VERSION ""

NS_ :

BS_:

BU_: HCM IPMA_ADAS PSCM GWM _delete SCCM PDM DDM GENERIC TSTR

BO_ 2613272740 SymKeyPhysPDMtoGWM_ECG: 64 PDM
 SG_ SymKeyPhysPDMtoGWM_ECG : 7|29@0+ (1,0) [0|536870911] "unitless"  GWM

BO_ 2613215448 SymKeyPhysGWM_ECGtoDDM: 64 GWM
 SG_ SymKeyPhysGWM_ECGtoDDM : 7|29@0+ (1,0) [0|536870911] "unitless"  DDM

BO_ 2613272736 SymKeyPhysDDMtoGWM_ECG: 64 DDM
 SG_ SymKeyPhysDDMtoGWM_ECG : 7|29@0+ (1,0) [0|536870911] "unitless"  GWM

BO_ 831 Pass_Mirror_Sw_StatM: 16 DDM
 SG_ MirrorTelescopic_D_Rq : 9|2@0+ (1,0) [0|3] "SED"  PDM,GWM
 SG_ RearPassWindowLockCmd : 0|1@0+ (1,0) [0|1] "SED"  PDM,GWM
 SG_ RearPassWindowCmd : 20|3@0+ (1,0) [0|7] "SED"  PDM,GWM
 SG_ PassWindowCmd : 12|3@0+ (1,0) [0|7] "SED"  PDM,GWM
 SG_ PassMirrorCmd : 15|3@0+ (1,0) [0|7] "SED"  PDM,GWM
 SG_ DipMirrorPosPassenger : 4|1@0+ (1,0) [0|1] "SED"  PDM,GWM
 SG_ ActiveStoragePassenger : 7|3@0+ (1,0) [0|7] "SED"  PDM,GWM
 SG_ RearDriverWindowPos : 23|3@0+ (1,0) [0|7] "SED"  GWM
 SG_ DriverWindowPosition : 3|3@0+ (1,0) [0|7] "SED"  GWM

BO_ 1258 IPMB_Data1_FD3: 8 GWM
 SG_ TrlrCamraCalib_D_Stat : 3|2@0+ (1,0) [0|3] "SED"  IPMA_ADAS,PSCM
 SG_ TrlrCamraView_D_Stat : 7|4@0+ (1,0) [0|15] "SED"  IPMA_ADAS

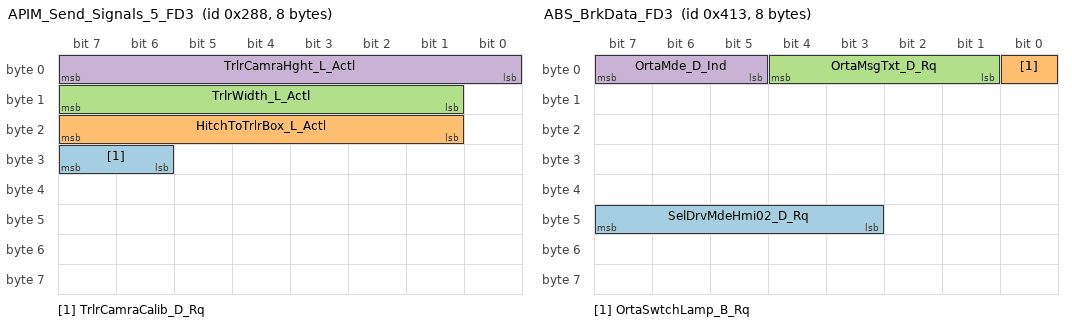
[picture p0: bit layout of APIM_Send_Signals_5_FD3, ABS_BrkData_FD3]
BO_ 648 APIM_Send_Signals_5_FD3: 8 GWM
 SG_ TrlrCamraCalib_D_Rq : 31|2@0+ (1,0) [0|3] "SED"  IPMA_ADAS
 SG_ HitchToTrlrBox_L_Actl : 23|7@0+ (25,0) [0|3175] "millimeter" Vector__XXX
 SG_ TrlrWidth_L_Actl : 15|7@0+ (25,0) [0|3175] "millimeter" Vector__XXX
 SG_ TrlrCamraHght_L_Actl : 7|8@0+ (25,0) [0|6375] "millimeter" Vector__XXX

BO_ 1158 BTT5GRH_Data1_FD3: 8 GWM
 SG_ SodAltRight_D2_StatAft : 7|2@0+ (1,0) [0|3] "SED"  IPMA_ADAS

BO_ 1157 BTT5GLH_Data1_FD3: 8 GWM
 SG_ SodAltLeft_D2_StatAft : 7|2@0+ (1,0) [0|3] "SED"  IPMA_ADAS

BO_ 1208 APIM_Send_Signals_4_FD3: 8 GWM
 SG_ Btt_L2_Actl2 : 7|7@0+ (0.1,5.1) [5.1|17.6] "meter"  IPMA_ADAS

BO_ 1218 Body_Info_5_FD3: 24 GWM
 SG_ OprtSrc_D_Stat : 47|3@0+ (1,0) [0|7] "SED"  _delete
 SG_ DrStopTglRl_No_Actl : 20|3@0+ (1,0) [0|7] "unitless"  _delete
 SG_ DrStopTglRr_No_Actl : 23|3@0+ (1,0) [0|7] "unitless"  _delete
 SG_ DrPsngrRearLck_D_Stat : 5|2@0+ (1,0) [0|3] "SED"  _delete
 SG_ DrDrvRearLck_D_Stat : 7|2@0+ (1,0) [0|3] "SED"  _delete
 SG_ ClsrOprtSrvcId_No_Actl : 36|3@0+ (1,0) [0|7] "unitless" Vector__XXX
 SG_ LckUnlckSrvcId_No_Actl : 39|3@0+ (1,0) [0|7] "unitless" Vector__XXX
 SG_ ClsrOprtSrvc_D_Res : 27|4@0+ (1,0) [0|15] "SED" Vector__XXX
 SG_ LckUnlckSrvc_D_Res : 31|4@0+ (1,0) [0|15] "SED" Vector__XXX
 SG_ ClsrOprtSrvc_D_Arb : 17|2@0+ (1,0) [0|3] "SED" Vector__XXX
 SG_ LckUnlckSrvc_D_Arb : 9|2@0+ (1,0) [0|3] "SED" Vector__XXX
 SG_ LatchFdbck_B_Stat : 33|1@0+ (1,0) [0|1] "SED" Vector__XXX
 SG_ FecSwtchExtLck_D_Stat : 11|2@0+ (1,0) [0|3] "SED" Vector__XXX
 SG_ DrPsngrLck_D_Stat : 13|2@0+ (1,0) [0|3] "SED" Vector__XXX
 SG_ DrDrvLck_D_Stat : 15|2@0+ (1,0) [0|3] "SED" Vector__XXX
 SG_ BecSwtchExtLck_D_Stat : 1|2@0+ (1,0) [0|3] "SED" Vector__XXX
 SG_ BecSwtch2ExtLck_D_Stat : 3|2@0+ (1,0) [0|3] "SED" Vector__XXX

BO_ 121 Steering_Data3: 64 SCCM
 SG_ SteSnsDiagData_No_Actl : 7|64@0+ (1,0) [0|1.84467440737096E+019] "unitless"  GWM

BO_ 1972 TesterPhysicalReqDCMH_FD3: 64 TSTR
 SG_ TesterPhysicalReqDCMH : 7|64@0+ (1,0) [0|1.84467E+019] "unitless" Vector__XXX

BO_ 1971 TesterPhysicalReqDCMG_FD3: 64 TSTR
 SG_ TesterPhysicalReqDCMG : 7|64@0+ (1,0) [0|1.84467E+019] "unitless" Vector__XXX

BO_ 2613272689 SymKeyPhysHCMtoGWM_ECG: 64 HCM
 SG_ SymKeyPhysHCMtoGWM_ECG : 7|29@0+ (1,0) [0|536870911] "unitless"  GWM

BO_ 2613167320 SymKeyPhysGWM_ECGtoHCM: 64 GWM
 SG_ SymKeyPhysGWM_ECGtoHCM : 7|29@0+ (1,0) [0|536870911] "unitless"  HCM

BO_ 1043 ABS_BrkData_FD3: 8 GWM
 SG_ SelDrvMdeHmi02_D_Rq : 47|5@0+ (1,0) [0|31] "SED" Vector__XXX
 SG_ OrtaSwtchLamp_B_Rq : 0|1@0+ (1,0) [0|1] "SED" Vector__XXX
 SG_ OrtaMsgTxt_D_Rq : 4|4@0+ (1,0) [0|15] "SED" Vector__XXX
 SG_ OrtaMde_D_Ind : 7|3@0+ (1,0) [0|7] "SED" Vector__XXX

BO_ 2609948888 OTAPhysGWM_ECGtoPBM: 64 GWM
 SG_ OTAPhysGWM_ECGtoPBM : 7|29@0+ (1,0) [0|536870911] "unitless" Vector__XXX

BO_ 2610997464 PARSEDPhysGWM_ECGtoPBM: 64 GWM
 SG_ PARSEDPhysGWM_ECGtoPBM : 7|29@0+ (1,0) [0|536870911] "unitless" Vector__XXX

BO_ 2612046040 PARSEDPushFcGWM_ECGtoPBM: 8 GWM
 SG_ PARSEDPushFcGWM_ECGtoPBM : 7|29@0+ (1,0) [0|536870911] "unitless" Vector__XXX

BO_ 2613094616 SymKeyPhysGWM_ECGtoPBM: 64 GWM
 SG_ SymKeyPhysGWM_ECGtoPBM : 7|29@0+ (1,0) [0|536870911] "unitless" Vector__XXX

BO_ 1049 APIMSDMsignals_FD3: 8 GWM
 SG_ TrlrRngId_No_RqReset : 27|4@0+ (1,0) [0|15] "unitless"  _delete
 SG_ TrlrId_No_ActlMnu : 31|4@0+ (1,0) [0|15] "unitless"  _delete
 SG_ TrailCtlSwtch_B_Stat4 : 21|1@0+ (1,0) [0|1] "SED"  _delete
 SG_ StabBarCnncButtn_D_Sta3 : 23|2@0+ (1,0) [0|3] "SED"  _delete
 SG_ RearDiffLck_D_RqDrv3 : 9|2@0+ (1,0) [0|3] "SED"  _delete
 SG_ FrontDiffLck_D_RqDrv3 : 11|2@0+ (1,0) [0|3] "SED"  _delete
 SG_ TurnAsstSwtch_D_Stat : 14|2@0+ (1,0) [0|3] "SED"  _delete
 SG_ SelDrvMdeTxtRst_B_Rq2 : 15|1@0+ (1,0) [0|1] "SED"  _delete
 SG_ SelDrvMdePage_B_Stat : 0|1@0+ (1,0) [0|1] "SED"  _delete
 SG_ SelDrvMdeCnfm_D_Stat2 : 2|2@0+ (1,0) [0|3] "SED"  _delete
 SG_ SelDrvMde_D_RqDrv : 7|5@0+ (1,0) [0|31] "SED"  _delete
 SG_ Chrgr_Pw_EstMx : 55|9@0+ (2,0) [0|1018] "kilowatt" Vector__XXX
 SG_ DcacZone3PwBttn_B_Stat : 34|1@0+ (1,0) [0|1] "SED" Vector__XXX
 SG_ DcacZone2PwBttn_B_Stat : 35|1@0+ (1,0) [0|1] "SED" Vector__XXX
 SG_ DcacPwResetBtn2_B_Stat : 36|1@0+ (1,0) [0|1] "SED" Vector__XXX
 SG_ DcacPwOffButtn2_B_Stat : 37|1@0+ (1,0) [0|1] "SED" Vector__XXX
 SG_ DcacPwHiButtn2_B_Stat : 38|1@0+ (1,0) [0|1] "SED" Vector__XXX
 SG_ DcacGfciTestBtn2_B_Stat : 39|1@0+ (1,0) [0|1] "SED" Vector__XXX
 SG_ DcacAllZoneBttn_B_Stat : 16|1@0+ (1,0) [0|1] "SED" Vector__XXX
 SG_ DcacChime_D_Rq : 18|2@0+ (1,0) [0|3] "SED" Vector__XXX
 SG_ PersTurnSglView_D_RqMnu : 20|2@0+ (1,0) [0|3] "SED"  IPMA_ADAS
 SG_ CamraFrnt_B_RqMnu : 12|1@0+ (1,0) [0|1] "SED"  IPMA_ADAS

BO_ 2611024088 PARSEDPhysGWM_ECGtoSCCM: 64 GWM
 SG_ PARSEDPhysGWM_ECGtoSCCM : 7|29@0+ (1,0) [0|536870911] "unitless"  SCCM

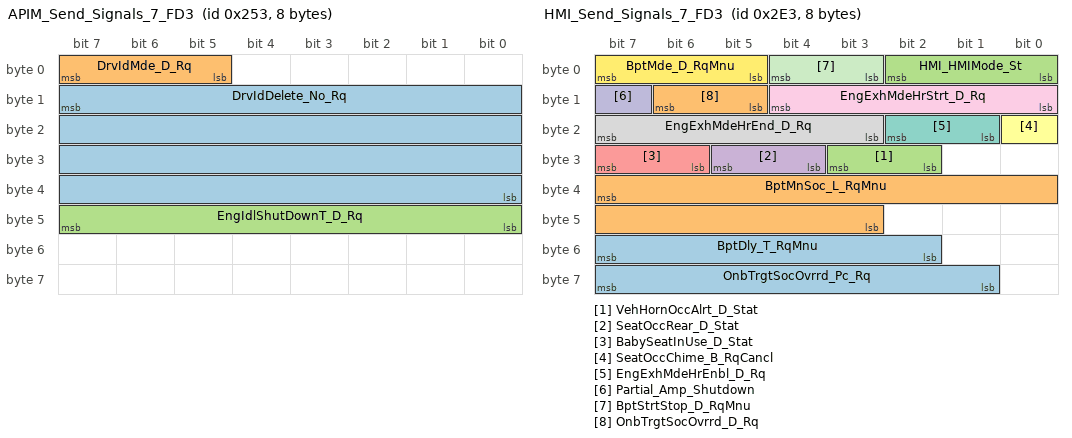
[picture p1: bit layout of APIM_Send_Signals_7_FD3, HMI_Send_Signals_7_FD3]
BO_ 595 APIM_Send_Signals_7_FD3: 8 GWM
 SG_ DrvIdDelete_No_Rq : 15|32@0+ (1,0) [0|4294967295] "Unitless"  _delete
 SG_ DrvIdMde_D_Rq : 7|3@0+ (1,0) [0|7] "SED"  _delete
 SG_ EngIdlShutDownT_D_Rq : 47|8@0+ (1,0) [0|255] "SED" Vector__XXX

BO_ 542 LocationServices_3_FD3: 8 GWM
 SG_ LocationServices_3 : 7|64@0+ (1,0) [0|1.84467440737096E+019] "unitless"  IPMA_ADAS

BO_ 2612224078 PARSEDPushLDCMBtoGWM_ECG: 8 HCM
 SG_ PARSEDPushLDCMBtoGWM_ECG : 7|29@0+ (1,0) [0|536870911] "unitless"  GWM

BO_ 2612224079 PARSEDPushLDCMAtoGWM_ECG: 8 HCM
 SG_ PARSEDPushLDCMAtoGWM_ECG : 7|29@0+ (1,0) [0|536870911] "unitless"  GWM

BO_ 2612082904 PARSEDPushFcGWM_ECGtoLDCMB: 8 GWM
 SG_ PARSEDPushFcGWM_ECGtoLDCMB : 7|29@0+ (1,0) [0|536870911] "unitless"  HCM

BO_ 2612083928 PARSEDPushFcGWM_ECGtoLDCMA: 8 GWM
 SG_ PARSEDPushFcGWM_ECGtoLDCMA : 7|29@0+ (1,0) [0|536870911] "unitless"  HCM

BO_ 2611175502 PARSEDPhysLDCMBtoGWM_ECG: 64 HCM
 SG_ PARSEDPhysLDCMBtoGWM_ECG : 7|29@0+ (1,0) [0|536870911] "Unitless"  GWM

BO_ 2611175503 PARSEDPhysLDCMAtoGWM_ECG: 64 HCM
 SG_ PARSEDPhysLDCMAtoGWM_ECG : 7|29@0+ (1,0) [0|536870911] "unitless"  GWM

BO_ 2611034328 PARSEDPhysGWM_ECGtoLDCMB: 64 GWM
 SG_ PARSEDPhysGWM_ECGtoLDCMB : 7|29@0+ (1,0) [0|536870911] "unitless"  HCM

BO_ 2611035352 PARSEDPhysGWM_ECGtoLDCMA: 64 GWM
 SG_ PARSEDPhysGWM_ECGtoLDCMA : 7|29@0+ (1,0) [0|536870911] "unitless"  HCM

BO_ 2610126926 OTAPhysLDCMBtoGWM_ECG: 64 HCM
 SG_ OTAPhysLDCMBtoGWM_ECG : 7|29@0+ (1,0) [0|536870911] "unitless"  GWM

BO_ 2610126927 OTAPhysLDCMAtoGWM_ECG: 64 HCM
 SG_ OTAPhysLDCMAtoGWM_ECG : 7|29@0+ (1,0) [0|536870911] "unitless"  GWM

BO_ 2609985752 OTAPhysGWM_ECGtoLDCMB: 64 GWM
 SG_ OTAPhysGWM_ECGtoLDCMB : 7|29@0+ (1,0) [0|536870911] "unitless"  HCM

BO_ 2609986776 OTAPhysGWM_ECGtoLDCMA: 64 GWM
 SG_ OTAPhysGWM_ECGtoLDCMA : 7|29@0+ (1,0) [0|536870911] "unitless"  HCM

BO_ 1791 TesterPhysicalResLDCMB: 64 HCM
 SG_ TesterPhysicalResLDCMB : 7|64@0+ (1,0) [0|1.84467E+019] "unitless"  TSTR

BO_ 1790 TesterPhysicalResLDCMA: 64 HCM
 SG_ TesterPhysicalResLDCMA : 7|64@0+ (1,0) [0|1.84467E+019] "unitless"  TSTR

BO_ 1783 TesterPhysicalReqLDCMB: 64 TSTR
 SG_ TesterPhysicalReqLDCMB : 7|64@0+ (1,0) [0|1.84467E+019] "unitless"  HCM

BO_ 1782 TesterPhysicalReqLDCMA: 64 TSTR
 SG_ TesterPhysicalReqLDCMA : 7|64@0+ (1,0) [0|1.84467E+019] "unitless"  HCM

BO_ 140 CruiseCtrl_StrgData2_FD3: 8 GWM
 SG_ DcacPwResetBttn_D_Stat : 36|2@0+ (1,0) [0|3] "SED" Vector__XXX

BO_ 739 HMI_Send_Signals_7_FD3: 8 GWM
 SG_ BptDly_T_RqMnu : 55|6@0+ (0.5,0) [0|30.5] "minute"  _delete
 SG_ BptMnSoc_L_RqMnu : 39|13@0+ (0.1,0) [0|818.9] "kilometer"  _delete
 SG_ VehHornOccAlrt_D_Stat : 27|2@0+ (1,0) [0|3] "SED"  _delete
 SG_ SeatOccRear_D_Stat : 29|2@0+ (1,0) [0|3] "SED"  _delete
 SG_ BabySeatInUse_D_Stat : 31|2@0+ (1,0) [0|3] "SED"  _delete
 SG_ SeatOccChime_B_RqCancl : 16|1@0+ (1,0) [0|1] "SED"  _delete
 SG_ EngExhMdeHrEnbl_D_Rq : 18|2@0+ (1,0) [0|3] "SED"  _delete
 SG_ EngExhMdeHrEnd_D_Rq : 23|5@0+ (1,0) [0|31] "SED"  _delete
 SG_ EngExhMdeHrStrt_D_Rq : 12|5@0+ (1,0) [0|31] "SED"  _delete
 SG_ Partial_Amp_Shutdown : 15|1@0+ (1,0) [0|1] "SED"  _delete
 SG_ BptStrtStop_D_RqMnu : 4|2@0+ (1,0) [0|3] "SED"  _delete
 SG_ BptMde_D_RqMnu : 7|3@0+ (1,0) [0|7] "SED"  _delete
 SG_ OnbTrgtSocOvrrd_Pc_Rq : 63|7@0+ (1,0) [0|127] "percent" Vector__XXX
 SG_ OnbTrgtSocOvrrd_D_Rq : 14|2@0+ (1,0) [0|3] "SED" Vector__XXX
 SG_ HMI_HMIMode_St : 2|3@0+ (1,0) [0|7] "SED"  SCCM,PDM,DDM

BO_ 129 Steering_Wheel_Data2: 8 SCCM
 SG_ SelDrvMdeSwtch4_D_Stat4 : 38|2@0+ (1,0) [0|3] "SED"  GWM
 SG_ EngExhMdeQuiet_B_RqDrv2 : 39|1@0+ (1,0) [0|1] "SED"  GWM
 SG_ SelDrvMdeSwtch3_D_Stat4 : 25|2@0+ (1,0) [0|3] "SED"  GWM
 SG_ SelDrvMdeSwtch2_D_Stat4 : 27|2@0+ (1,0) [0|3] "SED"  GWM
 SG_ SelDrvMdeSwtch1_D_Stat4 : 29|2@0+ (1,0) [0|3] "SED"  GWM
 SG_ PoliceAux4Swtch_B_Stat : 30|1@0+ (1,0) [0|1] "SED"  GWM
 SG_ PoliceAux3Swtch_B_Stat : 31|1@0+ (1,0) [0|1] "SED"  GWM
 SG_ PoliceAux2Swtch_B_Stat : 16|1@0+ (1,0) [0|1] "SED"  GWM
 SG_ PoliceAux1Swtch_B_Stat : 17|1@0+ (1,0) [0|1] "SED"  GWM
 SG_ SteWhlSwtchView_B_Stat : 23|1@0+ (1,0) [0|1] "SED"  GWM
 SG_ SteWhlSwtchSet_B_Stat : 8|1@0+ (1,0) [0|1] "SED"  GWM
 SG_ SteWhlSwtchPhon_B_Stat : 9|1@0+ (1,0) [0|1] "SED"  GWM
 SG_ SteWhlSwtchNav_B_Stat : 10|1@0+ (1,0) [0|1] "SED"  GWM
 SG_ SteWhlSwtchMed_B_Stat : 11|1@0+ (1,0) [0|1] "SED"  GWM
 SG_ SteWhlSwtchIod_B_Stat : 12|1@0+ (1,0) [0|1] "SED"  GWM
 SG_ SteWhlSwtchHud_B_Stat : 13|1@0+ (1,0) [0|1] "SED"  GWM
 SG_ SteWhlSwtchBack_B_Stat : 14|1@0+ (1,0) [0|1] "SED"  GWM
 SG_ SteWhlSwtchMenu_B_Stat : 22|1@0+ (1,0) [0|1] "SED"  GWM
 SG_ SteEffortInc_B_RqDrv : 5|1@0+ (1,0) [0|1] "SED"  GWM
 SG_ SelDrvMdeInc_B_RqDrv : 6|1@0+ (1,0) [0|1] "SED"  GWM
 SG_ SelDrvMdeDec_B_RqDrv : 7|1@0+ (1,0) [0|1] "SED"  GWM
 SG_ SuspDampInc_B_RqDrv : 15|1@0+ (1,0) [0|1] "SED"  GWM
 SG_ SteWhlSwtchUp_B_Stat : 3|1@0+ (1,0) [0|1] "SED"  GWM
 SG_ SteWhlSwtchRght_B_Stat : 2|1@0+ (1,0) [0|1] "SED"  GWM
 SG_ SteWhlSwtchOk_B_Stat : 4|1@0+ (1,0) [0|1] "SED"  GWM
 SG_ SteWhlSwtchLeft_B_Stat : 1|1@0+ (1,0) [0|1] "SED"  GWM
 SG_ SteWhlSwtchDown_B_Stat : 0|1@0+ (1,0) [0|1] "SED"  GWM

BO_ 863 Steering_Data2: 8 SCCM
 SG_ SteWhlHeat_D_Stat : 7|4@0+ (1,0) [0|15] "SED"  GWM

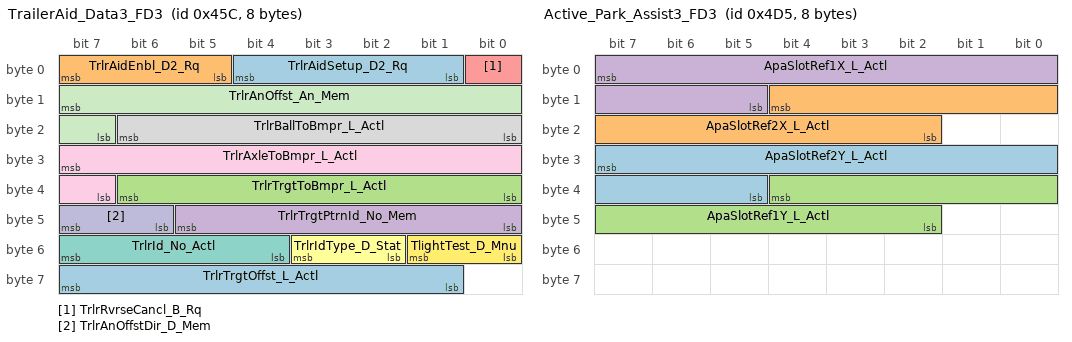
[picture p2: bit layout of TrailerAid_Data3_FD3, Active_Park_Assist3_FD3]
BO_ 1116 TrailerAid_Data3_FD3: 8 GWM
 SG_ TrlrAidSetup_D2_Rq : 4|4@0+ (1,0) [0|15] "SED"  PSCM,IPMA_ADAS
 SG_ TrlrAidEnbl_D2_Rq : 7|3@0+ (1,0) [0|7] "SED"  PSCM,IPMA_ADAS
 SG_ TrlrTrgtToBmpr_L_Actl : 38|7@0+ (0.0127,0) [0|1.6129] "meter"  PSCM,IPMA_ADAS
 SG_ TrlrTrgtPtrnId_No_Mem : 45|6@0+ (1,0) [0|63] "unitless"  IPMA_ADAS
 SG_ TrlrRvrseCancl_B_Rq : 0|1@0+ (1,0) [0|1] "SED"  PSCM,IPMA_ADAS
 SG_ TrlrIdType_D_Stat : 51|2@0+ (1,0) [0|3] "SED"  PSCM,IPMA_ADAS
 SG_ TrlrId_No_Actl : 55|4@0+ (1,0) [0|15] "unitless"  PSCM,IPMA_ADAS
 SG_ TrlrBallToBmpr_L_Actl : 22|7@0+ (0.0127,0) [0|1.6129] "meter"  PSCM,IPMA_ADAS
 SG_ TrlrAxleToBmpr_L_Actl : 31|9@0+ (0.0254,0) [0|12.9794] "meter"  PSCM,IPMA_ADAS
 SG_ TrlrAnOffstDir_D_Mem : 47|2@0+ (1,0) [0|3] "SED"  PSCM,IPMA_ADAS
 SG_ TrlrAnOffst_An_Mem : 15|9@0+ (0.1,0) [0|51.1] "degrees"  PSCM,IPMA_ADAS
 SG_ TlightTest_D_Mnu : 49|2@0+ (1,0) [0|3] "SED" Vector__XXX
 SG_ TrlrTrgtOffst_L_Actl : 63|7@0+ (0.0127,0) [0|1.6129] "meter"  PSCM,IPMA_ADAS

BO_ 1237 Active_Park_Assist3_FD3: 8 IPMA_ADAS
 SG_ ApaSlotRef2Y_L_Actl : 31|11@0+ (0.02,-20.96) [-20.96|19.98] "meter"  GWM
 SG_ ApaSlotRef2X_L_Actl : 12|11@0+ (0.02,-20.96) [-20.96|19.98] "meter"  GWM
 SG_ ApaSlotRef1Y_L_Actl : 36|11@0+ (0.02,-20.96) [-20.96|19.98] "meter"  GWM
 SG_ ApaSlotRef1X_L_Actl : 7|11@0+ (0.02,-20.96) [-20.96|19.98] "meter"  GWM

BO_ 1003 Personality_BCM2_Data_FD3: 16 GWM
 SG_ Pers4Key_D_Stat : 49|2@0+ (1,0) [0|3] "SED"  _delete
 SG_ EmPrflNo_D_Stat : 52|3@0+ (1,0) [0|7] "SED"  _delete
 SG_ EmPrflKeyAssoc_D_Stat : 55|3@0+ (1,0) [0|7] "SED"  _delete
 SG_ Pers3Key_D_Stat : 41|2@0+ (1,0) [0|3] "SED"  _delete
 SG_ Pers2Key_D_Stat : 43|2@0+ (1,0) [0|3] "SED"  _delete
 SG_ VehKeyActv_D_Stat : 47|4@0+ (1,0) [0|15] "SED"  _delete
 SG_ PersNoPos_D_Actl : 18|3@0+ (1,0) [0|7] "SED"  _delete
 SG_ PersConflict_D_Actl : 22|1@0+ (1,0) [0|1] "SED"  _delete
 SG_ Pers1Key_D_Stat : 12|2@0+ (1,0) [0|3] "SED"  _delete
 SG_ AssocConfirm_D_Actl : 15|3@0+ (1,0) [0|7] "SED"  _delete
 SG_ TailLghtLoadMde_D_Stat : 60|3@0+ (1,0) [0|7] "SED" Vector__XXX
 SG_ PersRecallSrc_D_Actl : 63|3@0+ (1,0) [0|7] "SED" Vector__XXX
 SG_ PersSetupRestr_D_Actl : 21|2@0+ (1,0) [0|3] "SED"  DDM,PDM
 SG_ PersSetupAccessCtrl : 19|1@0+ (1,0) [0|1] "SED"  DDM
 SG_ PersSetup_No_Actl : 31|16@0+ (1,0) [0|65535] "Number"  DDM,PDM
 SG_ RecallEvent_No_Cnt : 7|8@0+ (1,0) [0|255] "Counts"  DDM,IPMA_ADAS
 SG_ PersNo_D_Actl : 10|3@0+ (1,0) [0|7] "SED"  DDM,IPMA_ADAS

BO_ 1146 TrailerInfo_2_FD3: 8 GWM
 SG_ TrlrAidSwtch_D_RqDrv : 35|2@0+ (1,0) [0|3] "SED"  PSCM,IPMA_ADAS
 SG_ TrlrAidCtl_U_RqDrv : 31|12@0+ (0.00125,0) [0|5.11625] "volt"  PSCM

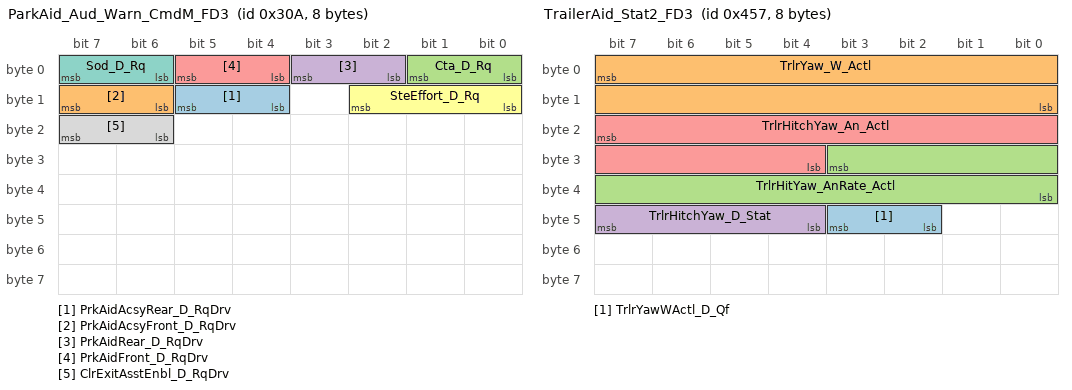
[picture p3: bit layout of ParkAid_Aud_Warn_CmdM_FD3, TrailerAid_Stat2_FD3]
BO_ 778 ParkAid_Aud_Warn_CmdM_FD3: 8 GWM
 SG_ PrkAidAcsyRear_D_RqDrv : 13|2@0+ (1,0) [0|3] "SED"  IPMA_ADAS
 SG_ PrkAidAcsyFront_D_RqDrv : 15|2@0+ (1,0) [0|3] "SED"  IPMA_ADAS
 SG_ Cta_D_Rq : 1|2@0+ (1,0) [0|3] "SED"  IPMA_ADAS
 SG_ PrkAidRear_D_RqDrv : 3|2@0+ (1,0) [0|3] "SED"  IPMA_ADAS
 SG_ PrkAidFront_D_RqDrv : 5|2@0+ (1,0) [0|3] "SED"  IPMA_ADAS
 SG_ SteEffort_D_Rq : 10|3@0+ (1,0) [0|7] "SED" Vector__XXX
 SG_ Sod_D_Rq : 7|2@0+ (1,0) [0|3] "SED"  IPMA_ADAS
 SG_ ClrExitAsstEnbl_D_RqDrv : 23|2@0+ (1,0) [0|3] "SED"  IPMA_ADAS

BO_ 1255 BoundaryAlert_Right_4: 16 IPMA_ADAS
 SG_ BalrRight4Threat_D_Stat : 16|1@0+ (1,0) [0|1] "SED"  GWM
 SG_ BalrRight4Prev3Y_L_Actl : 51|7@0+ (0.5,-32) [-32|31.5] "meter"  GWM
 SG_ BalrRight4Prev3X_L_Actl : 42|7@0+ (0.5,-32) [-32|31.5] "meter"  GWM
 SG_ BalrRight4Prev2Y_L_Actl : 33|7@0+ (0.5,-32) [-32|31.5] "meter"  GWM
 SG_ BalrRight4Prev2X_L_Actl : 24|7@0+ (0.5,-32) [-32|31.5] "meter"  GWM
 SG_ BalrRight4Prev1Y_L_Actl : 31|7@0+ (0.5,-32) [-32|31.5] "meter"  GWM
 SG_ BalrRight4Prev1X_L_Actl : 23|7@0+ (0.5,-32) [-32|31.5] "meter"  GWM
 SG_ BalrRight4Fast_B_Stat : 8|1@0+ (1,0) [0|1] "SED"  GWM
 SG_ BalrRight4Dsply_B_Stat : 0|1@0+ (1,0) [0|1] "SED"  GWM
 SG_ BalrRight4CurntY_L_Actl : 15|7@0+ (0.5,-32) [-32|31.5] "meter"  GWM
 SG_ BalrRight4CurntX_L_Actl : 7|7@0+ (0.5,-32) [-32|31.5] "meter"  GWM

BO_ 1254 BoundaryAlert_Right_3: 16 IPMA_ADAS
 SG_ BalrRight3Threat_D_Stat : 16|1@0+ (1,0) [0|1] "SED"  GWM
 SG_ BalrRight3Prev3Y_L_Actl : 51|7@0+ (0.5,-32) [-32|31.5] "meter"  GWM
 SG_ BalrRight3Prev3X_L_Actl : 42|7@0+ (0.5,-32) [-32|31.5] "meter"  GWM
 SG_ BalrRight3Prev2Y_L_Actl : 33|7@0+ (0.5,-32) [-32|31.5] "meter"  GWM
 SG_ BalrRight3Prev2X_L_Actl : 24|7@0+ (0.5,-32) [-32|31.5] "meter"  GWM
 SG_ BalrRight3Prev1Y_L_Actl : 31|7@0+ (0.5,-32) [-32|31.5] "meter"  GWM
 SG_ BalrRight3Prev1X_L_Actl : 23|7@0+ (0.5,-32) [-32|31.5] "meter"  GWM
 SG_ BalrRight3Fast_B_Stat : 8|1@0+ (1,0) [0|1] "SED"  GWM
 SG_ BalrRight3Dsply_B_Stat : 0|1@0+ (1,0) [0|1] "SED"  GWM
 SG_ BalrRight3CurntY_L_Actl : 15|7@0+ (0.5,-32) [-32|31.5] "meter"  GWM
 SG_ BalrRight3CurntX_L_Actl : 7|7@0+ (0.5,-32) [-32|31.5] "meter"  GWM

BO_ 1253 BoundaryAlert_Right_2: 16 IPMA_ADAS
 SG_ BalrRight2Prev3Y_L_Actl : 51|7@0+ (0.5,-32) [-32|31.5] "meter"  GWM
 SG_ BalrRight2Prev3X_L_Actl : 42|7@0+ (0.5,-32) [-32|31.5] "meter"  GWM
 SG_ BalrRight2Threat_D_Stat : 16|1@0+ (1,0) [0|1] "SED"  GWM
 SG_ BalrRight2Prev2Y_L_Actl : 33|7@0+ (0.5,-32) [-32|31.5] "meter"  GWM
 SG_ BalrRight2Prev2X_L_Actl : 24|7@0+ (0.5,-32) [-32|31.5] "meter"  GWM
 SG_ BalrRight2Prev1Y_L_Actl : 31|7@0+ (0.5,-32) [-32|31.5] "meter"  GWM
 SG_ BalrRight2Prev1X_L_Actl : 23|7@0+ (0.5,-32) [-32|31.5] "meter"  GWM
 SG_ BalrRight2Fast_B_Stat : 8|1@0+ (1,0) [0|1] "SED"  GWM
 SG_ BalrRight2Dsply_B_Stat : 0|1@0+ (1,0) [0|1] "SED"  GWM
 SG_ BalrRight2CurntY_L_Actl : 15|7@0+ (0.5,-32) [-32|31.5] "meter"  GWM
 SG_ BalrRight2CurntX_L_Actl : 7|7@0+ (0.5,-32) [-32|31.5] "meter"  GWM

BO_ 1252 BoundaryAlert_Right_1: 16 IPMA_ADAS
 SG_ BalrRight1Prev3Y_L_Actl : 51|7@0+ (0.5,-32) [-32|31.5] "meter"  GWM
 SG_ BalrRight1Prev3X_L_Actl : 42|7@0+ (0.5,-32) [-32|31.5] "meter"  GWM
 SG_ BalrRight1Threat_D_Stat : 16|1@0+ (1,0) [0|1] "SED"  GWM
 SG_ BalrRight1Prev2Y_L_Actl : 33|7@0+ (0.5,-32) [-32|31.5] "meter"  GWM
 SG_ BalrRight1Prev2X_L_Actl : 24|7@0+ (0.5,-32) [-32|31.5] "meter"  GWM
 SG_ BalrRight1Prev1Y_L_Actl : 31|7@0+ (0.5,-32) [-32|31.5] "meter"  GWM
 SG_ BalrRight1Prev1X_L_Actl : 23|7@0+ (0.5,-32) [-32|31.5] "meter"  GWM
 SG_ BalrRight1Fast_B_Stat : 8|1@0+ (1,0) [0|1] "SED"  GWM
 SG_ BalrRight1Dsply_B_Stat : 0|1@0+ (1,0) [0|1] "SED"  GWM
 SG_ BalrRight1CurntY_L_Actl : 15|7@0+ (0.5,-32) [-32|31.5] "meter"  GWM
 SG_ BalrRight1CurntX_L_Actl : 7|7@0+ (0.5,-32) [-32|31.5] "meter"  GWM

BO_ 1251 BoundaryAlert_Left_4: 16 IPMA_ADAS
 SG_ BalrLeft4Threat_D_Stat : 16|1@0+ (1,0) [0|1] "SED"  GWM
 SG_ BalrLeft4Prev3Y_L_Actl : 51|7@0+ (0.5,-32) [-32|31.5] "meter"  GWM
 SG_ BalrLeft4Prev3X_L_Actl : 42|7@0+ (0.5,-32) [-32|31.5] "meter"  GWM
 SG_ BalrLeft4Prev2Y_L_Actl : 33|7@0+ (0.5,-32) [-32|31.5] "meter"  GWM
 SG_ BalrLeft4Prev2X_L_Actl : 24|7@0+ (0.5,-32) [-32|31.5] "meter"  GWM
 SG_ BalrLeft4Prev1Y_L_Actl : 31|7@0+ (0.5,-32) [-32|31.5] "meter"  GWM
 SG_ BalrLeft4Prev1X_L_Actl : 23|7@0+ (0.5,-32) [-32|31.5] "meter"  GWM
 SG_ BalrLeft4Fast_B_Stat : 8|1@0+ (1,0) [0|1] "SED"  GWM
 SG_ BalrLeft4Dsply_B_Stat : 0|1@0+ (1,0) [0|1] "SED"  GWM
 SG_ BalrLeft4CurntY_L_Actl : 15|7@0+ (0.5,-32) [-32|31.5] "meter"  GWM
 SG_ BalrLeft4CurntX_L_Actl : 7|7@0+ (0.5,-32) [-32|31.5] "meter"  GWM

BO_ 1250 BoundaryAlert_Left_3: 16 IPMA_ADAS
 SG_ BalrLeft3Threat_D_Stat : 16|1@0+ (1,0) [0|1] "SED"  GWM
 SG_ BalrLeft3Prev3Y_L_Actl : 51|7@0+ (0.5,-32) [-32|31.5] "meter"  GWM
 SG_ BalrLeft3Prev3X_L_Actl : 42|7@0+ (0.5,-32) [-32|31.5] "meter"  GWM
 SG_ BalrLeft3Prev2Y_L_Actl : 33|7@0+ (0.5,-32) [-32|31.5] "meter"  GWM
 SG_ BalrLeft3Prev2X_L_Actl : 24|7@0+ (0.5,-32) [-32|31.5] "meter"  GWM
 SG_ BalrLeft3Prev1Y_L_Actl : 31|7@0+ (0.5,-32) [-32|31.5] "meter"  GWM
 SG_ BalrLeft3Prev1X_L_Actl : 23|7@0+ (0.5,-32) [-32|31.5] "meter"  GWM
 SG_ BalrLeft3Fast_B_Stat : 8|1@0+ (1,0) [0|1] "SED"  GWM
 SG_ BalrLeft3Dsply_B_Stat : 0|1@0+ (1,0) [0|1] "SED"  GWM
 SG_ BalrLeft3CurntY_L_Actl : 15|7@0+ (0.5,-32) [-32|31.5] "meter"  GWM
 SG_ BalrLeft3CurntX_L_Actl : 7|7@0+ (0.5,-32) [-32|31.5] "meter"  GWM

BO_ 1249 BoundaryAlert_Left_2: 16 IPMA_ADAS
 SG_ BalrLeft2Prev3Y_L_Actl : 51|7@0+ (0.5,-32) [-32|31.5] "meter"  GWM
 SG_ BalrLeft2Prev3X_L_Actl : 42|7@0+ (0.5,-32) [-32|31.5] "meter"  GWM
 SG_ BalrLeft2Threat_D_Stat : 16|1@0+ (1,0) [0|1] "SED"  GWM
 SG_ BalrLeft2Prev2Y_L_Actl : 33|7@0+ (0.5,-32) [-32|31.5] "meter"  GWM
 SG_ BalrLeft2Prev2X_L_Actl : 24|7@0+ (0.5,-32) [-32|31.5] "meter"  GWM
 SG_ BalrLeft2Prev1Y_L_Actl : 31|7@0+ (0.5,-32) [-32|31.5] "meter"  GWM
 SG_ BalrLeft2Prev1X_L_Actl : 23|7@0+ (0.5,-32) [-32|31.5] "meter"  GWM
 SG_ BalrLeft2Fast_B_Stat : 8|1@0+ (1,0) [0|1] "SED"  GWM
 SG_ BalrLeft2Dsply_B_Stat : 0|1@0+ (1,0) [0|1] "SED"  GWM
 SG_ BalrLeft2CurntY_L_Actl : 15|7@0+ (0.5,-32) [-32|31.5] "meter"  GWM
 SG_ BalrLeft2CurntX_L_Actl : 7|7@0+ (0.5,-32) [-32|31.5] "meter"  GWM

BO_ 1248 BoundaryAlert_Left_1: 16 IPMA_ADAS
 SG_ BalrLeft1Threat_D_Stat : 16|1@0+ (1,0) [0|1] "SED"  GWM
 SG_ BalrLeft1Prev3Y_L_Actl : 51|7@0+ (0.5,-32) [-32|31.5] "meter"  GWM
 SG_ BalrLeft1Prev3X_L_Actl : 42|7@0+ (0.5,-32) [-32|31.5] "meter"  GWM
 SG_ BalrLeft1Prev2Y_L_Actl : 33|7@0+ (0.5,-32) [-32|31.5] "meter"  GWM
 SG_ BalrLeft1Prev2X_L_Actl : 24|7@0+ (0.5,-32) [-32|31.5] "meter"  GWM
 SG_ BalrLeft1Prev1Y_L_Actl : 31|7@0+ (0.5,-32) [-32|31.5] "meter"  GWM
 SG_ BalrLeft1Prev1X_L_Actl : 23|7@0+ (0.5,-32) [-32|31.5] "meter"  GWM
 SG_ BalrLeft1Fast_B_Stat : 8|1@0+ (1,0) [0|1] "SED"  GWM
 SG_ BalrLeft1Dsply_B_Stat : 0|1@0+ (1,0) [0|1] "SED"  GWM
 SG_ BalrLeft1CurntY_L_Actl : 15|7@0+ (0.5,-32) [-32|31.5] "meter"  GWM
 SG_ BalrLeft1CurntX_L_Actl : 7|7@0+ (0.5,-32) [-32|31.5] "meter"  GWM

BO_ 2610988248 PARSEDPhysGWM_ECGtoIPMA: 64 GWM
 SG_ PARSEDPhysGWM_ECGtoIPMA : 7|29@0+ (1,0) [0|536870911] "unitless"  IPMA_ADAS

BO_ 1105 Image_Processing_Data: 16 IPMA_ADAS
 SG_ ClrExitAsstMsgTxt2_D_Rq : 55|4@0+ (1,0) [0|15] "SED"  GWM
 SG_ ClrExitAsstActv_B_Rq : 24|1@0+ (1,0) [0|1] "SED"  GWM
 SG_ TrlrRvrseMsgTxt_D2_Rq : 31|6@0+ (1,0) [0|63] "SED"  PSCM,GWM
 SG_ TrlrRvrseEnbl_D2_Stat : 18|3@0+ (1,0) [0|7] "SED"  PSCM,GWM
 SG_ RbaMsg_D_Rq : 22|2@0+ (1,0) [0|3] "SED"  GWM
 SG_ BrkDecel_B_RqRba : 8|1@0+ (1,0) [0|1] "SED"  GWM
 SG_ BrkEnbl_B_RqRba : 23|1@0+ (1,0) [0|1] "SED"  GWM
 SG_ Rba_D_Stat : 14|2@0+ (1,0) [0|3] "SED"  GWM
 SG_ RbaAlrt_D_Dsply : 12|2@0+ (1,0) [0|3] "SED"  GWM
 SG_ RbaMnu_D_Rq : 10|2@0+ (1,0) [0|3] "SED"  GWM
 SG_ CamraFrntStat_D_Stat : 7|2@0+ (1,0) [0|3] "SED"  GWM
 SG_ TrlrHitchLamp_D_Rq2 : 15|1@0+ (1,0) [0|1] "SED"  GWM
 SG_ TrlrAidSwtchLamp_B_Rq : 32|1@0+ (1,0) [0|1] "SED"  GWM
 SG_ TrlrAidEnbl_D_RqAdas : 5|3@0+ (1,0) [0|7] "SED"  PSCM,GWM
 SG_ TrlrHitchMsgTxt_D_Rq : 47|6@0+ (1,0) [0|63] "SED"  GWM
 SG_ TrlrHitchIcon_D_Rq : 36|4@0+ (1,0) [0|15] "SED"  GWM
 SG_ TrlrHitchChime_D_Rq : 39|3@0+ (1,0) [0|7] "SED"  GWM
 SG_ CamraFrntOffRd_B_Stat : 25|1@0+ (1,0) [0|1] "SED"  GWM

BO_ 1111 TrailerAid_Stat2_FD3: 8 GWM
 SG_ TrlrYawWActl_D_Qf : 43|2@0+ (1,0) [0|3] "SED"  PSCM,IPMA_ADAS
 SG_ TrlrYaw_W_Actl : 7|16@0+ (0.0002,-6.5) [-6.5|6.6066] "radians/second"  PSCM,IPMA_ADAS
 SG_ TrlrHitYaw_AnRate_Actl : 27|12@0+ (0.1,-50) [-50|359.3] "degrees/sec"  PSCM,IPMA_ADAS
 SG_ TrlrHitchYaw_D_Stat : 47|4@0+ (1,0) [0|15] "SED"  PSCM,IPMA_ADAS
 SG_ TrlrHitchYaw_An_Actl : 23|12@0+ (0.1,-90) [-90|319.3] "degrees"  PSCM,IPMA_ADAS

BO_ 1106 TrailerAid_Stat1_FD3: 8 GWM
 SG_ TrlrSnsId_No_Actl : 7|48@0+ (1,0) [0|281474976710653] "unitless"  PSCM,IPMA_ADAS

BO_ 909 Body_Info_6_FD3: 16 GWM
 SG_ HazrdLght_B_Stat : 56|1@0+ (1,0) [0|1] "SED"  _delete
 SG_ IgnPsswrdDsply_B_Rq : 57|1@0+ (1,0) [0|1] "SED"  _delete
 SG_ ElPwPoint_D_Rq : 59|2@0+ (1,0) [0|3] "SED"  _delete
 SG_ TurnLghtSwtch_D_Stat2 : 49|2@0+ (1,0) [0|3] "SED"  _delete
 SG_ PoliceIdlMde_D_Stat : 55|4@0+ (1,0) [0|15] "SED"  _delete
 SG_ PrsnlDevcChrgEnbl_B_Rq : 40|1@0+ (1,0) [0|1] "SED"  _delete
 SG_ DrLatchMsgTxt_D_Rq : 43|3@0+ (1,0) [0|7] "SED"  _delete
 SG_ TracKeyMde_D_Stat : 45|2@0+ (1,0) [0|3] "SED"  _delete
 SG_ SecurityMsgTxt_D_Rq : 47|2@0+ (1,0) [0|3] "SED"  _delete
 SG_ PrmtrAlrmEvnt_D_Stat : 35|4@0+ (1,0) [0|15] "SED"  _delete
 SG_ immoMsgTxt_D_Rq : 39|4@0+ (1,0) [0|15] "SED"  _delete
 SG_ SteWhlLckMsgTxt_D_Rq : 25|2@0+ (1,0) [0|3] "SED"  _delete
 SG_ PEBackupSlot_Stats : 27|2@0+ (1,0) [0|3] "SED"  _delete
 SG_ Keycode_Status : 15|20@0+ (1,0) [0|1048575] "unitless"  _delete
 SG_ KeyMykeyTot_No_Cnt : 3|4@0+ (1,0) [0|15] "Counts"  _delete
 SG_ KeyAdmnTot_No_Cnt : 7|4@0+ (1,0) [0|15] "Counts"  _delete
 SG_ WiprFront_D_Stat2 : 63|4@0+ (1,0) [0|15] "SED" Vector__XXX
 SG_ HeadLghtHiPrmsn_D_Stat : 51|2@0+ (1,0) [0|3] "SED"  SCCM,HCM,IPMA_ADAS

BO_ 963 BCM_Lamp_Stat_FD3: 16 GWM
 SG_ PudLampPsngr_D_Rq : 57|2@0+ (1,0) [0|3] "SED"  _delete
 SG_ DrTgateLck_D_Stat : 61|2@0+ (1,0) [0|3] "SED"  _delete
 SG_ Illuminated_Entry_Stat : 63|2@0+ (1,0) [0|3] "SED"  _delete
 SG_ Dr_Courtesy_Light_Stat : 49|2@0+ (1,0) [0|3] "SED"  _delete
 SG_ Courtesy_Delay_Status : 51|2@0+ (1,0) [0|3] "SED"  _delete
 SG_ ImpactEvntFdbck_D_Stat : 53|2@0+ (1,0) [0|3] "SED"  _delete
 SG_ WrlssAcsyChrgInhbt_B_Rq : 40|1@0+ (1,0) [0|1] "SED"  _delete
 SG_ HeadLampLoOut_B_Stat : 32|1@0+ (1,0) [0|1] "SED"  _delete
 SG_ TrnNotInPrkChime_B_Rq : 24|1@0+ (1,0) [0|1] "SED"  _delete
 SG_ PrkLightChime_B_Rq : 25|1@0+ (1,0) [0|1] "SED"  _delete
 SG_ Park_Brake_Chime_Rqst : 26|1@0+ (1,0) [0|1] "SED"  _delete
 SG_ KeyInIgnWarn_B_Cmd : 27|1@0+ (1,0) [0|1] "SED"  _delete
 SG_ HomeSafeLtChime_B_Rq : 28|1@0+ (1,0) [0|1] "SED"  _delete
 SG_ Headlamp_On_Wrning_Cmd : 29|1@0+ (1,0) [0|1] "SED"  _delete
 SG_ Brk_Fluid_Lvl_Low : 31|2@0+ (1,0) [0|3] "SED"  _delete
 SG_ ReducedGuard_D_Stat : 19|2@0+ (1,0) [0|3] "SED"  _delete
 SG_ BrkWarnInd_B_Rq : 20|1@0+ (1,0) [0|1] "SED"  _delete
 SG_ RvrseLghtOn_B_Stat : 9|1@0+ (1,0) [0|1] "SED"  _delete
 SG_ PrkLght_D_Stat : 13|2@0+ (1,0) [0|3] "SED"  _delete
 SG_ PerimeterAlarmChimeRq : 0|1@0+ (1,0) [0|1] "SED"  _delete
 SG_ CrnrLghtRight_Pc_Rq : 47|7@0+ (1,0) [0|100] "percent"  HCM
 SG_ CrnrLghtLeft_Pc_Rq : 39|7@0+ (1,0) [0|100] "percent"  HCM
 SG_ HeadLghtHiFdbck_D_Stat : 55|2@0+ (1,0) [0|3] "SED"  SCCM
 SG_ PudLampDrv_D_Rq : 59|2@0+ (1,0) [0|3] "SED"  DDM
 SG_ StopLghtOn_B_Stat : 8|1@0+ (1,0) [0|1] "SED"  HCM
 SG_ HeadLghtSwtch_D_Stat : 15|2@0+ (1,0) [0|3] "SED"  HCM,IPMA_ADAS
 SG_ HeadLampLoFrOn_B_Stat : 2|1@0+ (1,0) [0|1] "SED"  SCCM,HCM,IPMA_ADAS
 SG_ HeadLampLoFlOn_B_Stat : 3|1@0+ (1,0) [0|1] "SED"  SCCM,HCM,IPMA_ADAS
 SG_ HeadLampLoActv_B_Stat : 4|1@0+ (1,0) [0|1] "SED"  HCM,IPMA_ADAS
 SG_ HeadLghtHiOn_B_Stat : 1|1@0+ (1,0) [0|1] "SED"  HCM,IPMA_ADAS
 SG_ Perimeter_Alarm_Status : 17|2@0+ (1,0) [0|3] "SED"  IPMA_ADAS
 SG_ Courtesy_BSave_Stat : 7|2@0+ (1,0) [0|3] "SED"  PDM,DDM
 SG_ WndwGlbl_D_Cmd : 23|3@0+ (1,0) [0|7] "SED"  PDM,DDM
 SG_ PudLamp_D_Rq : 11|2@0+ (1,0) [0|3] "SED"  PDM,DDM
 SG_ DayRnngLampOn_B_Stat : 5|1@0+ (1,0) [0|1] "SED"  HCM

BO_ 578 Body_Info_4_FD3: 16 GWM
 SG_ PtLatchActv_B_RqBcm : 56|1@0+ (1,0) [0|1] "SED" Vector__XXX
 SG_ immoSecureIdleMode : 61|2@0+ (1,0) [0|3] "SED" Vector__XXX
 SG_ ReFuelSwtchStat_D_Actl : 63|2@0+ (1,0) [0|3] "SED" Vector__XXX
 SG_ FuelPumpPwr_D_Stat : 50|3@0+ (1,0) [0|7] "SED" Vector__XXX
 SG_ BattULo_U_Actl : 39|8@0+ (0.0625,0) [0|15.875] "volt"  PSCM,IPMA_ADAS
 SG_ PrkLckCtl_B_Enbl : 22|1@0+ (1,0) [0|1] "SED" Vector__XXX
 SG_ PrkLckCtlMsgTxt_D_Rq : 55|2@0+ (1,0) [0|3] "SED" Vector__XXX
 SG_ PrkLckCtlAvail_T_Stat : 47|8@0+ (1,0) [0|255] "second" Vector__XXX
 SG_ BrkTrnShifLck_B_Stat : 23|1@0+ (1,0) [0|1] "SED" Vector__XXX
 SG_ PrkLckCtlUnlck_D_Stat : 58|2@0+ (1,0) [0|3] "SED" Vector__XXX
 SG_ PrkLckCtlTow_B_Enbl : 59|1@0+ (1,0) [0|1] "SED" Vector__XXX
 SG_ DriverCrankingReq : 51|1@0+ (1,0) [0|1] "SED" Vector__XXX
 SG_ EngOff_T_Actl : 7|16@0+ (1,0) [0|65534] "second^0.5"  IPMA_ADAS
 SG_ DcacElPw_D_Rq : 53|2@0+ (1,0) [0|3] "SED" Vector__XXX
 SG_ BattULo_I_Actl : 21|14@0+ (0.0625,-512) [-512|511.875] "ampere" Vector__XXX

BO_ 1892 TesterPhysicalReqCCM: 64 TSTR
 SG_ TesterPhysicalReqCCM : 7|64@0+ (1,0) [0|1.84467E+019] "unitless"  IPMA_ADAS

BO_ 1798 TesterPhysicalReqIPMA: 64 TSTR
 SG_ TesterPhysicalReqIPMA : 7|64@0+ (1,0) [0|1.84467E+019] "unitless"  IPMA_ADAS

BO_ 1900 TesterPhysicalResCCM: 64 IPMA_ADAS
 SG_ TesterPhysicalResCCM : 7|64@0+ (1,0) [0|1.84467E+019] "unitless"  TSTR

BO_ 1806 TesterPhysicalResIPMA: 64 IPMA_ADAS
 SG_ TesterPhysicalResIPMA : 7|64@0+ (1,0) [0|1.84467E+019] "unitless"  TSTR

BO_ 1010 IPMA_Data3: 16 IPMA_ADAS
 SG_ LightRng_L_Max : 55|6@0+ (2,0) [0|126] "meter"  HCM,GWM
 SG_ LightPathOffst_L_Actl : 31|10@0+ (0.01,-5.12) [-5.12|5.11] "meter"  HCM,GWM
 SG_ LightPath_An_Actl : 12|11@0+ (0.0005,-0.5) [-0.5|0.5235] "radians"  HCM,GWM
 SG_ LightCurv_NoRate_Actl : 37|13@0+ (2.5E-007,-0.001024) [-0.001024|0.00102375] "1/meter"  HCM,GWM
 SG_ LightCurv_No_Actl : 7|11@0+ (2E-005,-0.02) [-0.02|0.02094] "1/meter"  HCM,GWM
 SG_ MbdblActv_B_RqAdas : 48|1@0+ (1,0) [0|1] "SED"  GWM,HCM
 SG_ CbdblActv_B_RqAdas : 49|1@0+ (1,0) [0|1] "SED"  HCM,GWM
 SG_ AdbUrbanArea_B_Stat : 40|1@0+ (1,0) [0|1] "SED"  HCM,GWM

BO_ 985 IPMA_Data2: 16 IPMA_ADAS
 SG_ LongCtrlEnblDRq_No_Cs : 63|8@0+ (1,0) [0|255] "Unitless"  GWM
 SG_ LongCtrlEnblDRq_No_Cnt : 29|4@0+ (1,0) [0|15] "Unitless"  GWM
 SG_ ClrExitAsst_D_Stat : 39|2@0+ (1,0) [0|3] "SED"  GWM
 SG_ ClrExitAsstMsgTxt_D_Rq : 52|4@0+ (1,0) [0|15] "SED"  GWM
 SG_ ClrExitAsstChime_D_Rq : 55|3@0+ (1,0) [0|7] "SED"  GWM
 SG_ PwSustnAdas_B_Rq : 48|1@0+ (1,0) [0|1] "SED"  GWM
 SG_ AdbDrvSide_B_Stat : 35|1@0+ (1,0) [0|1] "SED"  GWM
 SG_ LcwaMsgTxt_D_Stat : 37|2@0+ (1,0) [0|3] "SED"  GWM
 SG_ AdbDividedRoad_B_Stat : 30|1@0+ (1,0) [0|1] "SED"  GWM
 SG_ IsaVLimUnit_D_Rq : 15|2@0+ (1,0) [0|3] "SED"  GWM
 SG_ SblmYieldScnr_B_Stat : 31|1@0+ (1,0) [0|1] "SED"  HCM,GWM
 SG_ SblmStopScnr_B_Stat : 8|1@0+ (1,0) [0|1] "SED"  HCM,GWM
 SG_ IsaVLim_D_Rq : 7|8@0+ (1,0) [0|255] "SED"  GWM
 SG_ IaccVLimUnit_D_Rq : 11|2@0+ (1,0) [0|3] "SED"  GWM
 SG_ IaccVLim_D_Rq : 23|8@0+ (1,0) [0|255] "SED"  GWM
 SG_ DasAlrtInfo_D_Dsply : 13|2@0+ (1,0) [0|3] "SED"  GWM
 SG_ SblmRndAbtScnr_B_Stat : 9|1@0+ (1,0) [0|1] "SED"  HCM,GWM
 SG_ LongCtrlEnbl_D_Rq : 42|3@0+ (1,0) [0|7] "SED"  GWM
 SG_ SblmPedCrossScnr_B_Stat : 33|1@0+ (1,0) [0|1] "SED"  HCM,GWM
 SG_ TsrRegionTxt_D_Stat : 47|5@0+ (1,0) [0|31] "SED"  GWM
 SG_ LongCtrlBrk_D_Rq : 25|2@0+ (1,0) [0|3] "SED"  GWM
 SG_ LdwChime_B_Rq : 34|1@0+ (1,0) [0|1] "SED"  GWM

BO_ 984 IPMA_Data: 16 IPMA_ADAS
 SG_ AhbFeat_D_Stat : 63|2@0+ (1,0) [0|3] "SED"  HCM,SCCM,GWM
 SG_ LaActvStats_D2_Dsply : 55|5@0+ (1,0) [0|31] "SED"  GWM
 SG_ DasWarn_D_Dsply : 44|2@0+ (1,0) [0|3] "SED"  GWM
 SG_ DasStats_D_Dsply : 47|2@0+ (1,0) [0|3] "SED"  GWM
 SG_ DasAlrtLvl_D_Dsply : 42|3@0+ (1,0) [0|7] "SED"  GWM
 SG_ CamraStats_D_Dsply : 35|2@0+ (1,0) [0|3] "SED"  GWM
 SG_ CamraDefog_B_Req : 36|1@0+ (1,0) [0|1] "SED"  GWM
 SG_ LaHandsOff_D_Dsply : 50|2@0+ (1,0) [0|3] "SED"  GWM
 SG_ LaDenyStats_B_Dsply : 32|1@0+ (1,0) [0|1] "SED"  GWM
 SG_ AhbcRampingV_D_Rq : 57|2@0+ (1,0) [0|3] "SED"  GWM
 SG_ PersIndexIpma_D_Actl : 39|3@0+ (1,0) [0|7] "SED"  GWM
 SG_ FeatNoIpmaActl : 23|16@0+ (1,0) [0|65535] "Number"  GWM
 SG_ FeatConfigIpmaActl : 7|16@0+ (1,0) [0|65535] "Undefined"  GWM
 SG_ AhbHiBeam_D_Rq : 59|2@0+ (1,0) [0|3] "SED"  SCCM,GWM
 SG_ DsmcMsgTxt_D_Dsply : 61|2@0+ (1,0) [0|3] "SED" Vector__XXX

BO_ 983 Steer_Assist_Data: 16 IPMA_ADAS
 SG_ CmbbObjRelLong_V_Actl : 39|10@0+ (0.1,-102.1) [-102.1|0] "meters/sec"  PSCM,GWM
 SG_ CmbbObjRelLat_V_Actl : 23|9@0+ (0.1,-25.5) [-25.5|25.4] "meters/sec"  PSCM,GWM
 SG_ CmbbObjDistLong_L_Actl : 7|10@0+ (0.1,0) [0|102.1] "meter"  PSCM,GWM
 SG_ CmbbObjDistLat_L_Actl : 45|9@0+ (0.1,-25.5) [-25.5|25.4] "meter"  PSCM,GWM
 SG_ CmbbObjConfdnc_D_Stat : 9|2@0+ (1,0) [0|3] "SED"  PSCM,GWM
 SG_ CmbbObjColl_T_Actl : 30|7@0+ (0.05,0) [0|6.25] "second"  PSCM,GWM
 SG_ CmbbObjClass_D_Stat : 13|4@0+ (1,0) [0|15] "SED"  PSCM,GWM
 SG_ EsaEnbl_D2_Rq : 52|2@0+ (1,0) [0|3] "SED"  PSCM,GWM

BO_ 970 Lane_Assist_Data1: 16 IPMA_ADAS
 SG_ LkaDrvOvrrd_D_Rq : 38|2@0+ (1,0) [0|3] "SED"  PSCM,GWM
 SG_ LkaActvStats_D2_Req : 7|3@0+ (1,0) [0|7] "SED"  PSCM,GWM
 SG_ LaRefAng_No_Req : 19|12@0+ (0.05,-102.4) [-102.4|102.3] "mrad"  PSCM,GWM
 SG_ LaRampType_B_Req : 39|1@0+ (1,0) [0|1] "SED"  PSCM,GWM
 SG_ LaCurvature_No_Calc : 15|12@0+ (5E-006,-0.01024) [-0.01024|0.01023] "1/m"  PSCM,GWM
 SG_ LdwActvStats_D_Req : 4|3@0+ (1,0) [0|7] "SED"  PSCM,GWM
 SG_ LdwActvIntns_D_Req : 1|2@0+ (1,0) [0|3] "SED"  PSCM,GWM

CM_ SG_ 542 LocationServices_3 "Tx by HS3 APIM";
CM_ BO_ 739 "FCDIM Tx";
CM_ SG_ 739 Partial_Amp_Shutdown "Method Partial_Amp_Shutdown";
CM_ SG_ 739 HMI_HMIMode_St "Object ACU System Master.HMIMode
OR
Object NAV System Master.HMIMode

Refer Method HMIAudioMode in the SPSS";
CM_ SG_ 129 SelDrvMdeSwtch3_D_Stat4 "ECM_HEV does not support or Transmit signal.";
CM_ BO_ 1111 " new RCM Serial Trailer Aid (TrailerAid_Stat1) 48 bits";
CM_ BO_ 1106 " new RCM Serial Trailer Aid (TrailerAid_Stat1) 48 bits";
CM_ SG_ 985 LongCtrlEnblDRq_No_Cs "Signal not transmitted on gas and diesel variants.";
CM_ SG_ 985 LongCtrlEnblDRq_No_Cnt "Signal not transmitted on gas and diesel variants.";
BA_DEF_ BO_  "VFrameFormat" ENUM  "StandardCAN","ExtendedCAN","reserved","reserved","reserved","reserved","reserved","reserved","reserved","reserved","reserved","reserved","reserved","reserved","StandardCAN_FD","ExtendedCAN_FD";
BA_DEF_ BO_  "FrameRouting" STRING ;
BA_DEF_ BO_  "NetworkInitialization" ENUM  "No","Yes";
BA_DEF_ BO_  "GenMsgStartDelayTime" INT 0 10000;
BA_DEF_ BO_  "GenMsgNrOfRepetition" INT 0 100;
BA_DEF_ BO_  "GenMsgDelayTime" INT 0 1000;
BA_DEF_ BO_  "GenMsgCycleTime" INT 0 100000;
BA_DEF_ BO_  "GenMsgSendType" ENUM  "FixedPeriodic","Event","EnabledPeriodic","NotUsed","NotUsed","EventPeriodic","NotUsed","NotUsed","NoMsgSendType";
BA_DEF_ SG_  "U_P702_MY2024_Tx" ENUM  "No","Yes";
BA_DEF_ SG_  "U_V710_MY2023_Tx" ENUM  "No","Yes";
BA_DEF_ SG_  "U_CDX74X_MY2024_Tx" ENUM  "No","Yes";
BA_DEF_ SG_  "U_P708_MY2023_Tx" ENUM  "No","Yes";
BA_DEF_ SG_  "U_V713AV_MY2022_Tx" ENUM  "No","Yes";
BA_DEF_ SG_  "U_V713N_MY2022_Tx" ENUM  "No","Yes";
BA_DEF_ SG_  "ECGUsedTxSignal" ENUM  "No","Yes";
BA_DEF_ SG_  "U_P702_MY2024_Rx" ENUM  "No","Yes";
BA_DEF_ SG_  "U_V710_MY2023_Rx" ENUM  "No","Yes";
BA_DEF_ SG_  "U_CDX74X_MY2024_Rx" ENUM  "No","Yes";
BA_DEF_ SG_  "U_CDX707_MY2023_Rx" ENUM  "No","Yes";
BA_DEF_ SG_  "U_P708_MY2023_Rx" ENUM  "No","Yes";
BA_DEF_ SG_  "U_V713N_MY2022_Rx" ENUM  "No","Yes";
BA_DEF_ SG_  "ECGUsedRxSignal" ENUM  "No","Yes";
BA_DEF_ SG_  "UsedOnPgmDBC" ENUM  "No","Yes";
BA_DEF_ SG_  "ContentDependant" ENUM  "No","Yes";
BA_DEF_ SG_  "GenSigStartValue" HEX 0 268435455;
BA_DEF_ SG_  "MetaData" ENUM  "No","Yes";
BA_DEF_ SG_  "WakeupSignal" ENUM  "No","Yes";
BA_DEF_ SG_  "GenSigInactiveValue" INT 0 100000;
BA_DEF_ SG_  "GenSigSendType" ENUM  "Cyclic","OnWrite","vector_leerstring","OnChange","vector_leerstring","IfActive","vector_leerstring","NoSigSendType";
BA_DEF_ BO_  "TpTxIndex" INT 0 536870911;
BA_DEF_ BO_  "OvtpPushApplication" ENUM  "FALSE","TRUE";
BA_DEF_ BO_  "SCP_FreshnessValueLength" INT 0 512;
BA_DEF_ BO_  "SCP_DataId" INT 0 17663;
BA_DEF_ BO_  "SCP_FreshnessValueTxLength" INT 0 512;
BA_DEF_ BO_  "SCP_AuthInfoTxLength" INT 0 512;
BA_DEF_ BO_  "SC_Message" ENUM  "No","Yes";
BA_DEF_ BO_  "GenMsgRoutingTimeoutTime" INT 0 5000;
BA_DEF_ BO_  "MessageGateway" ENUM  "No","Yes";
BA_DEF_ BO_  "NmAsrMessage" ENUM  "No","Yes";
BA_DEF_ BO_  "DiagState" ENUM  "No","Yes";
BA_DEF_ BO_  "DiagRequest" ENUM  "No","Yes";
BA_DEF_ BO_  "DiagResponse" ENUM  "No","Yes";
BA_DEF_ BO_  "GenMsgILSupport" ENUM  "No","Yes";
BA_DEF_REL_ BU_SG_REL_  "SC_Verification" ENUM  "No","Yes";
BA_DEF_DEF_  "VFrameFormat" "ExtendedCAN_FD";
BA_DEF_DEF_  "FrameRouting" "";
BA_DEF_DEF_  "NetworkInitialization" "Yes";
BA_DEF_DEF_  "GenMsgStartDelayTime" 0;
BA_DEF_DEF_  "GenMsgNrOfRepetition" 1;
BA_DEF_DEF_  "GenMsgDelayTime" 20;
BA_DEF_DEF_  "GenMsgCycleTime" 0;
BA_DEF_DEF_  "GenMsgSendType" "NoMsgSendType";
BA_DEF_DEF_  "U_P702_MY2024_Tx" "No";
BA_DEF_DEF_  "U_V710_MY2023_Tx" "No";
BA_DEF_DEF_  "U_CDX74X_MY2024_Tx" "No";
BA_DEF_DEF_  "U_P708_MY2023_Tx" "No";
BA_DEF_DEF_  "U_V713AV_MY2022_Tx" "No";
BA_DEF_DEF_  "U_V713N_MY2022_Tx" "No";
BA_DEF_DEF_  "ECGUsedTxSignal" "No";
BA_DEF_DEF_  "U_P702_MY2024_Rx" "No";
BA_DEF_DEF_  "U_V710_MY2023_Rx" "No";
BA_DEF_DEF_  "U_CDX74X_MY2024_Rx" "No";
BA_DEF_DEF_  "U_CDX707_MY2023_Rx" "No";
BA_DEF_DEF_  "U_P708_MY2023_Rx" "No";
BA_DEF_DEF_  "U_V713N_MY2022_Rx" "No";
BA_DEF_DEF_  "ECGUsedRxSignal" "No";
BA_DEF_DEF_  "UsedOnPgmDBC" "Yes";
BA_DEF_DEF_  "ContentDependant" "No";
BA_DEF_DEF_  "GenSigStartValue" 0;
BA_DEF_DEF_  "MetaData" "No";
BA_DEF_DEF_  "WakeupSignal" "No";
BA_DEF_DEF_  "GenSigInactiveValue" 0;
BA_DEF_DEF_  "GenSigSendType" "NoSigSendType";
BA_DEF_DEF_  "TpTxIndex" 0;
BA_DEF_DEF_  "OvtpPushApplication" "FALSE";
BA_DEF_DEF_  "SCP_FreshnessValueLength" 64;
BA_DEF_DEF_  "SCP_DataId" 0;
BA_DEF_DEF_  "SCP_FreshnessValueTxLength" 11;
BA_DEF_DEF_  "SCP_AuthInfoTxLength" 53;
BA_DEF_DEF_  "SC_Message" "No";
BA_DEF_DEF_  "GenMsgRoutingTimeoutTime" 0;
BA_DEF_DEF_  "MessageGateway" "No";
BA_DEF_DEF_  "NmAsrMessage" "No";
BA_DEF_DEF_  "DiagState" "No";
BA_DEF_DEF_  "DiagRequest" "No";
BA_DEF_DEF_  "DiagResponse" "No";
BA_DEF_DEF_  "GenMsgILSupport" "Yes";
BA_DEF_DEF_REL_ "SC_Verification" "No";
BA_ "GenMsgSendType" BO_ 2613272740 1;
BA_ "GenMsgDelayTime" BO_ 2613272740 0;
BA_ "NetworkInitialization" BO_ 2613272740 0;
BA_ "GenMsgSendType" BO_ 2613215448 1;
BA_ "GenMsgDelayTime" BO_ 2613215448 0;
BA_ "NetworkInitialization" BO_ 2613215448 0;
BA_ "GenMsgSendType" BO_ 2613272736 1;
BA_ "GenMsgDelayTime" BO_ 2613272736 0;
BA_ "NetworkInitialization" BO_ 2613272736 0;
BA_ "GenMsgSendType" BO_ 831 5;
BA_ "GenMsgCycleTime" BO_ 831 1000;
BA_ "GenMsgStartDelayTime" BO_ 831 200;
BA_ "SCP_DataId" BO_ 831 17215;
BA_ "SC_Message" BO_ 831 1;
BA_ "VFrameFormat" BO_ 831 14;
BA_ "FrameRouting" BO_ 1258 "MS2_CAN,0x4EA;";
BA_ "VFrameFormat" BO_ 1258 14;
BA_ "FrameRouting" BO_ 648 "HS3_CAN,0x288;";
BA_ "VFrameFormat" BO_ 648 14;
BA_ "FrameRouting" BO_ 1158 "MS2_CAN,0x486;";
BA_ "VFrameFormat" BO_ 1158 14;
BA_ "FrameRouting" BO_ 1157 "MS2_CAN,0x485;";
BA_ "VFrameFormat" BO_ 1157 14;
BA_ "FrameRouting" BO_ 1208 "HS3_CAN,0x4B8;";
BA_ "VFrameFormat" BO_ 1208 14;
BA_ "FrameRouting" BO_ 1218 "FD1_CAN,0x4C2;";
BA_ "SCP_DataId" BO_ 1218 13506;
BA_ "SC_Message" BO_ 1218 1;
BA_ "VFrameFormat" BO_ 1218 14;
BA_ "GenMsgSendType" BO_ 121 0;
BA_ "GenMsgCycleTime" BO_ 121 10;
BA_ "GenMsgDelayTime" BO_ 121 0;
BA_ "VFrameFormat" BO_ 121 14;
BA_ "GenMsgILSupport" BO_ 1972 0;
BA_ "DiagRequest" BO_ 1972 1;
BA_ "GenMsgSendType" BO_ 1972 1;
BA_ "GenMsgDelayTime" BO_ 1972 0;
BA_ "NetworkInitialization" BO_ 1972 0;
BA_ "VFrameFormat" BO_ 1972 14;
BA_ "GenMsgILSupport" BO_ 1971 0;
BA_ "DiagRequest" BO_ 1971 1;
BA_ "GenMsgSendType" BO_ 1971 1;
BA_ "GenMsgDelayTime" BO_ 1971 0;
BA_ "NetworkInitialization" BO_ 1971 0;
BA_ "VFrameFormat" BO_ 1971 14;
BA_ "TpTxIndex" BO_ 2613272689 465683672;
BA_ "GenMsgSendType" BO_ 2613272689 1;
BA_ "GenMsgDelayTime" BO_ 2613272689 0;
BA_ "NetworkInitialization" BO_ 2613272689 0;
BA_ "TpTxIndex" BO_ 2613167320 465683672;
BA_ "GenMsgSendType" BO_ 2613167320 1;
BA_ "GenMsgDelayTime" BO_ 2613167320 0;
BA_ "NetworkInitialization" BO_ 2613167320 0;
BA_ "FrameRouting" BO_ 1043 "FD1_CAN,0x413;";
BA_ "VFrameFormat" BO_ 1043 14;
BA_ "TpTxIndex" BO_ 2609948888 462465240;
BA_ "GenMsgSendType" BO_ 2609948888 1;
BA_ "GenMsgDelayTime" BO_ 2609948888 0;
BA_ "NetworkInitialization" BO_ 2609948888 0;
BA_ "TpTxIndex" BO_ 2610997464 463513816;
BA_ "GenMsgSendType" BO_ 2610997464 1;
BA_ "GenMsgDelayTime" BO_ 2610997464 0;
BA_ "NetworkInitialization" BO_ 2610997464 0;
BA_ "OvtpPushApplication" BO_ 2612046040 1;
BA_ "TpTxIndex" BO_ 2612046040 464562392;
BA_ "GenMsgSendType" BO_ 2612046040 1;
BA_ "GenMsgDelayTime" BO_ 2612046040 0;
BA_ "NetworkInitialization" BO_ 2612046040 0;
BA_ "TpTxIndex" BO_ 2613094616 465610968;
BA_ "GenMsgSendType" BO_ 2613094616 1;
BA_ "GenMsgDelayTime" BO_ 2613094616 0;
BA_ "NetworkInitialization" BO_ 2613094616 0;
BA_ "FrameRouting" BO_ 1049 "HS3_CAN,0x419;";
BA_ "VFrameFormat" BO_ 1049 14;
BA_ "TpTxIndex" BO_ 2611024088 463540440;
BA_ "GenMsgSendType" BO_ 2611024088 1;
BA_ "GenMsgDelayTime" BO_ 2611024088 0;
BA_ "NetworkInitialization" BO_ 2611024088 0;
BA_ "FrameRouting" BO_ 595 "HS3_CAN,0x253;";
BA_ "VFrameFormat" BO_ 595 14;
BA_ "FrameRouting" BO_ 542 "FD2_CAN,0x21E;";
BA_ "VFrameFormat" BO_ 542 14;
BA_ "OvtpPushApplication" BO_ 2612224078 1;
BA_ "TpTxIndex" BO_ 2612224078 464599256;
BA_ "GenMsgSendType" BO_ 2612224078 1;
BA_ "GenMsgDelayTime" BO_ 2612224078 0;
BA_ "NetworkInitialization" BO_ 2612224078 0;
BA_ "OvtpPushApplication" BO_ 2612224079 1;
BA_ "TpTxIndex" BO_ 2612224079 464600280;
BA_ "GenMsgSendType" BO_ 2612224079 1;
BA_ "GenMsgDelayTime" BO_ 2612224079 0;
BA_ "NetworkInitialization" BO_ 2612224079 0;
BA_ "OvtpPushApplication" BO_ 2612082904 1;
BA_ "TpTxIndex" BO_ 2612082904 464599256;
BA_ "GenMsgSendType" BO_ 2612082904 1;
BA_ "GenMsgDelayTime" BO_ 2612082904 0;
BA_ "NetworkInitialization" BO_ 2612082904 0;
BA_ "OvtpPushApplication" BO_ 2612083928 1;
BA_ "TpTxIndex" BO_ 2612083928 464600280;
BA_ "GenMsgSendType" BO_ 2612083928 1;
BA_ "GenMsgDelayTime" BO_ 2612083928 0;
BA_ "NetworkInitialization" BO_ 2612083928 0;
BA_ "TpTxIndex" BO_ 2611175502 463550680;
BA_ "GenMsgSendType" BO_ 2611175502 1;
BA_ "GenMsgDelayTime" BO_ 2611175502 0;
BA_ "NetworkInitialization" BO_ 2611175502 0;
BA_ "TpTxIndex" BO_ 2611175503 463551704;
BA_ "GenMsgSendType" BO_ 2611175503 1;
BA_ "GenMsgDelayTime" BO_ 2611175503 0;
BA_ "NetworkInitialization" BO_ 2611175503 0;
BA_ "TpTxIndex" BO_ 2611034328 463550680;
BA_ "GenMsgSendType" BO_ 2611034328 1;
BA_ "GenMsgDelayTime" BO_ 2611034328 0;
BA_ "NetworkInitialization" BO_ 2611034328 0;
BA_ "TpTxIndex" BO_ 2611035352 463551704;
BA_ "GenMsgSendType" BO_ 2611035352 1;
BA_ "GenMsgDelayTime" BO_ 2611035352 0;
BA_ "NetworkInitialization" BO_ 2611035352 0;
BA_ "TpTxIndex" BO_ 2610126926 462502104;
BA_ "GenMsgSendType" BO_ 2610126926 1;
BA_ "GenMsgDelayTime" BO_ 2610126926 0;
BA_ "NetworkInitialization" BO_ 2610126926 0;
BA_ "TpTxIndex" BO_ 2610126927 462503128;
BA_ "GenMsgSendType" BO_ 2610126927 1;
BA_ "GenMsgDelayTime" BO_ 2610126927 0;
BA_ "NetworkInitialization" BO_ 2610126927 0;
BA_ "TpTxIndex" BO_ 2609985752 462502104;
BA_ "GenMsgSendType" BO_ 2609985752 1;
BA_ "GenMsgDelayTime" BO_ 2609985752 0;
BA_ "NetworkInitialization" BO_ 2609985752 0;
BA_ "TpTxIndex" BO_ 2609986776 462503128;
BA_ "GenMsgSendType" BO_ 2609986776 1;
BA_ "GenMsgDelayTime" BO_ 2609986776 0;
BA_ "NetworkInitialization" BO_ 2609986776 0;
BA_ "GenMsgILSupport" BO_ 1791 0;
BA_ "DiagResponse" BO_ 1791 1;
BA_ "GenMsgSendType" BO_ 1791 1;
BA_ "GenMsgDelayTime" BO_ 1791 0;
BA_ "NetworkInitialization" BO_ 1791 0;
BA_ "VFrameFormat" BO_ 1791 14;
BA_ "GenMsgILSupport" BO_ 1790 0;
BA_ "DiagResponse" BO_ 1790 1;
BA_ "GenMsgSendType" BO_ 1790 1;
BA_ "GenMsgDelayTime" BO_ 1790 0;
BA_ "NetworkInitialization" BO_ 1790 0;
BA_ "VFrameFormat" BO_ 1790 14;
BA_ "GenMsgILSupport" BO_ 1783 0;
BA_ "DiagRequest" BO_ 1783 1;
BA_ "GenMsgSendType" BO_ 1783 1;
BA_ "GenMsgDelayTime" BO_ 1783 0;
BA_ "NetworkInitialization" BO_ 1783 0;
BA_ "VFrameFormat" BO_ 1783 14;
BA_ "GenMsgILSupport" BO_ 1782 0;
BA_ "DiagRequest" BO_ 1782 1;
BA_ "GenMsgSendType" BO_ 1782 1;
BA_ "GenMsgDelayTime" BO_ 1782 0;
BA_ "NetworkInitialization" BO_ 1782 0;
BA_ "VFrameFormat" BO_ 1782 14;
BA_ "FrameRouting" BO_ 140 "HS3_CAN,0x8C;";
BA_ "VFrameFormat" BO_ 140 14;
BA_ "FrameRouting" BO_ 739 "HS3_CAN,0x2E3;";
BA_ "VFrameFormat" BO_ 739 14;
BA_ "GenMsgSendType" BO_ 129 5;
BA_ "GenMsgCycleTime" BO_ 129 1000;
BA_ "VFrameFormat" BO_ 129 14;
BA_ "GenMsgSendType" BO_ 863 5;
BA_ "GenMsgCycleTime" BO_ 863 1000;
BA_ "VFrameFormat" BO_ 863 14;
BA_ "FrameRouting" BO_ 1116 "HS3_CAN,0x45C;";
BA_ "VFrameFormat" BO_ 1116 14;
BA_ "GenMsgSendType" BO_ 1237 5;
BA_ "GenMsgCycleTime" BO_ 1237 200;
BA_ "VFrameFormat" BO_ 1237 14;
BA_ "FrameRouting" BO_ 1003 "FD1_CAN,0x3EB;";
BA_ "SCP_DataId" BO_ 1003 5099;
BA_ "SC_Message" BO_ 1003 1;
BA_ "VFrameFormat" BO_ 1003 14;
BA_ "FrameRouting" BO_ 1146 "HS3_CAN,0x47A;";
BA_ "VFrameFormat" BO_ 1146 14;
BA_ "FrameRouting" BO_ 778 "HS3_CAN,0x30A;";
BA_ "VFrameFormat" BO_ 778 14;
BA_ "GenMsgSendType" BO_ 1255 0;
BA_ "GenMsgCycleTime" BO_ 1255 1000;
BA_ "SCP_DataId" BO_ 1255 13543;
BA_ "SC_Message" BO_ 1255 1;
BA_ "VFrameFormat" BO_ 1255 14;
BA_ "GenMsgSendType" BO_ 1254 0;
BA_ "GenMsgCycleTime" BO_ 1254 1000;
BA_ "SCP_DataId" BO_ 1254 13542;
BA_ "SC_Message" BO_ 1254 1;
BA_ "VFrameFormat" BO_ 1254 14;
BA_ "GenMsgSendType" BO_ 1253 0;
BA_ "GenMsgCycleTime" BO_ 1253 1000;
BA_ "SCP_DataId" BO_ 1253 13541;
BA_ "SC_Message" BO_ 1253 1;
BA_ "VFrameFormat" BO_ 1253 14;
BA_ "GenMsgSendType" BO_ 1252 0;
BA_ "GenMsgCycleTime" BO_ 1252 1000;
BA_ "SCP_DataId" BO_ 1252 13540;
BA_ "SC_Message" BO_ 1252 1;
BA_ "VFrameFormat" BO_ 1252 14;
BA_ "GenMsgSendType" BO_ 1251 0;
BA_ "GenMsgCycleTime" BO_ 1251 1000;
BA_ "SCP_DataId" BO_ 1251 13539;
BA_ "SC_Message" BO_ 1251 1;
BA_ "VFrameFormat" BO_ 1251 14;
BA_ "GenMsgSendType" BO_ 1250 0;
BA_ "GenMsgCycleTime" BO_ 1250 1000;
BA_ "SCP_DataId" BO_ 1250 13538;
BA_ "SC_Message" BO_ 1250 1;
BA_ "VFrameFormat" BO_ 1250 14;
BA_ "GenMsgSendType" BO_ 1249 0;
BA_ "GenMsgCycleTime" BO_ 1249 1000;
BA_ "SCP_DataId" BO_ 1249 13537;
BA_ "SC_Message" BO_ 1249 1;
BA_ "VFrameFormat" BO_ 1249 14;
BA_ "GenMsgSendType" BO_ 1248 0;
BA_ "GenMsgCycleTime" BO_ 1248 1000;
BA_ "SCP_DataId" BO_ 1248 13536;
BA_ "SC_Message" BO_ 1248 1;
BA_ "VFrameFormat" BO_ 1248 14;
BA_ "TpTxIndex" BO_ 2610988248 463504600;
BA_ "GenMsgSendType" BO_ 2610988248 1;
BA_ "GenMsgDelayTime" BO_ 2610988248 0;
BA_ "NetworkInitialization" BO_ 2610988248 0;
BA_ "GenMsgSendType" BO_ 1105 5;
BA_ "GenMsgCycleTime" BO_ 1105 1000;
BA_ "SCP_DataId" BO_ 1105 5201;
BA_ "SC_Message" BO_ 1105 1;
BA_ "VFrameFormat" BO_ 1105 14;
BA_ "FrameRouting" BO_ 1111 "HS2_CAN,0x457;FD1_CAN,0x457";
BA_ "VFrameFormat" BO_ 1111 14;
BA_ "FrameRouting" BO_ 1106 "HS2_CAN,0x452;FD1_CAN,0x452";
BA_ "VFrameFormat" BO_ 1106 14;
BA_ "FrameRouting" BO_ 909 "FD1_CAN,0x38D;";
BA_ "SCP_DataId" BO_ 909 9101;
BA_ "SC_Message" BO_ 909 1;
BA_ "VFrameFormat" BO_ 909 14;
BA_ "FrameRouting" BO_ 963 "FD1_CAN,0x3C3;";
BA_ "SCP_DataId" BO_ 963 5059;
BA_ "SC_Message" BO_ 963 1;
BA_ "VFrameFormat" BO_ 963 14;
BA_ "FrameRouting" BO_ 578 "FD1_CAN,0x242;";
BA_ "SCP_DataId" BO_ 578 4674;
BA_ "SC_Message" BO_ 578 1;
BA_ "VFrameFormat" BO_ 578 14;
BA_ "GenMsgILSupport" BO_ 1892 0;
BA_ "DiagRequest" BO_ 1892 1;
BA_ "GenMsgSendType" BO_ 1892 1;
BA_ "GenMsgDelayTime" BO_ 1892 0;
BA_ "NetworkInitialization" BO_ 1892 0;
BA_ "VFrameFormat" BO_ 1892 14;
BA_ "GenMsgILSupport" BO_ 1798 0;
BA_ "DiagRequest" BO_ 1798 1;
BA_ "GenMsgSendType" BO_ 1798 1;
BA_ "GenMsgDelayTime" BO_ 1798 0;
BA_ "NetworkInitialization" BO_ 1798 0;
BA_ "VFrameFormat" BO_ 1798 14;
BA_ "GenMsgILSupport" BO_ 1900 0;
BA_ "DiagResponse" BO_ 1900 1;
BA_ "GenMsgSendType" BO_ 1900 1;
BA_ "GenMsgDelayTime" BO_ 1900 0;
BA_ "NetworkInitialization" BO_ 1900 0;
BA_ "VFrameFormat" BO_ 1900 14;
BA_ "GenMsgILSupport" BO_ 1806 0;
BA_ "DiagResponse" BO_ 1806 1;
BA_ "GenMsgSendType" BO_ 1806 1;
BA_ "GenMsgDelayTime" BO_ 1806 0;
BA_ "NetworkInitialization" BO_ 1806 0;
BA_ "VFrameFormat" BO_ 1806 14;
BA_ "GenMsgSendType" BO_ 1010 0;
BA_ "GenMsgCycleTime" BO_ 1010 50;
BA_ "SCP_DataId" BO_ 1010 17394;
BA_ "SC_Message" BO_ 1010 1;
BA_ "VFrameFormat" BO_ 1010 14;
BA_ "GenMsgSendType" BO_ 985 5;
BA_ "GenMsgCycleTime" BO_ 985 60;
BA_ "SCP_DataId" BO_ 985 5081;
BA_ "SC_Message" BO_ 985 1;
BA_ "VFrameFormat" BO_ 985 14;
BA_ "GenMsgSendType" BO_ 984 5;
BA_ "GenMsgCycleTime" BO_ 984 1000;
BA_ "SCP_DataId" BO_ 984 9176;
BA_ "SC_Message" BO_ 984 1;
BA_ "VFrameFormat" BO_ 984 14;
BA_ "GenMsgSendType" BO_ 983 0;
BA_ "GenMsgCycleTime" BO_ 983 50;
BA_ "SCP_DataId" BO_ 983 5079;
BA_ "SC_Message" BO_ 983 1;
BA_ "VFrameFormat" BO_ 983 14;
BA_ "GenMsgSendType" BO_ 970 0;
BA_ "GenMsgCycleTime" BO_ 970 30;
BA_ "GenMsgDelayTime" BO_ 970 10;
BA_ "SCP_DataId" BO_ 970 5066;
BA_ "SC_Message" BO_ 970 1;
BA_ "VFrameFormat" BO_ 970 14;
BA_ "GenSigSendType" SG_ 2613272740 SymKeyPhysPDMtoGWM_ECG 3;
BA_ "ECGUsedRxSignal" SG_ 2613272740 SymKeyPhysPDMtoGWM_ECG 1;
BA_ "U_P708_MY2023_Rx" SG_ 2613272740 SymKeyPhysPDMtoGWM_ECG 1;
BA_ "U_P702_MY2024_Rx" SG_ 2613272740 SymKeyPhysPDMtoGWM_ECG 1;
BA_ "U_P708_MY2023_Tx" SG_ 2613272740 SymKeyPhysPDMtoGWM_ECG 1;
BA_ "U_P702_MY2024_Tx" SG_ 2613272740 SymKeyPhysPDMtoGWM_ECG 1;
BA_ "GenSigSendType" SG_ 2613215448 SymKeyPhysGWM_ECGtoDDM 3;
BA_ "U_P708_MY2023_Rx" SG_ 2613215448 SymKeyPhysGWM_ECGtoDDM 1;
BA_ "U_P702_MY2024_Rx" SG_ 2613215448 SymKeyPhysGWM_ECGtoDDM 1;
BA_ "ECGUsedTxSignal" SG_ 2613215448 SymKeyPhysGWM_ECGtoDDM 1;
BA_ "U_P708_MY2023_Tx" SG_ 2613215448 SymKeyPhysGWM_ECGtoDDM 1;
BA_ "U_CDX74X_MY2024_Tx" SG_ 2613215448 SymKeyPhysGWM_ECGtoDDM 1;
BA_ "U_P702_MY2024_Tx" SG_ 2613215448 SymKeyPhysGWM_ECGtoDDM 1;
BA_ "GenSigSendType" SG_ 2613272736 SymKeyPhysDDMtoGWM_ECG 3;
BA_ "ECGUsedRxSignal" SG_ 2613272736 SymKeyPhysDDMtoGWM_ECG 1;
BA_ "U_P708_MY2023_Rx" SG_ 2613272736 SymKeyPhysDDMtoGWM_ECG 1;
BA_ "U_P702_MY2024_Rx" SG_ 2613272736 SymKeyPhysDDMtoGWM_ECG 1;
BA_ "U_P708_MY2023_Tx" SG_ 2613272736 SymKeyPhysDDMtoGWM_ECG 1;
BA_ "U_P702_MY2024_Tx" SG_ 2613272736 SymKeyPhysDDMtoGWM_ECG 1;
BA_ "GenSigSendType" SG_ 831 MirrorTelescopic_D_Rq 3;
BA_ "U_P708_MY2023_Rx" SG_ 831 MirrorTelescopic_D_Rq 1;
BA_ "U_P702_MY2024_Rx" SG_ 831 MirrorTelescopic_D_Rq 1;
BA_ "U_P708_MY2023_Tx" SG_ 831 MirrorTelescopic_D_Rq 1;
BA_ "U_P702_MY2024_Tx" SG_ 831 MirrorTelescopic_D_Rq 1;
BA_ "GenSigSendType" SG_ 831 RearPassWindowLockCmd 3;
BA_ "U_P708_MY2023_Rx" SG_ 831 RearPassWindowLockCmd 1;
BA_ "U_P702_MY2024_Rx" SG_ 831 RearPassWindowLockCmd 1;
BA_ "U_V713N_MY2022_Tx" SG_ 831 RearPassWindowLockCmd 1;
BA_ "U_P708_MY2023_Tx" SG_ 831 RearPassWindowLockCmd 1;
BA_ "U_P702_MY2024_Tx" SG_ 831 RearPassWindowLockCmd 1;
BA_ "WakeupSignal" SG_ 831 RearPassWindowCmd 1;
BA_ "GenSigSendType" SG_ 831 RearPassWindowCmd 3;
BA_ "U_P708_MY2023_Rx" SG_ 831 RearPassWindowCmd 1;
BA_ "U_P702_MY2024_Rx" SG_ 831 RearPassWindowCmd 1;
BA_ "U_V713N_MY2022_Tx" SG_ 831 RearPassWindowCmd 1;
BA_ "U_P708_MY2023_Tx" SG_ 831 RearPassWindowCmd 1;
BA_ "U_P702_MY2024_Tx" SG_ 831 RearPassWindowCmd 1;
BA_ "WakeupSignal" SG_ 831 PassWindowCmd 1;
BA_ "GenSigSendType" SG_ 831 PassWindowCmd 3;
BA_ "U_P708_MY2023_Rx" SG_ 831 PassWindowCmd 1;
BA_ "U_P702_MY2024_Rx" SG_ 831 PassWindowCmd 1;
BA_ "U_V713N_MY2022_Tx" SG_ 831 PassWindowCmd 1;
BA_ "U_P708_MY2023_Tx" SG_ 831 PassWindowCmd 1;
BA_ "U_P702_MY2024_Tx" SG_ 831 PassWindowCmd 1;
BA_ "WakeupSignal" SG_ 831 PassMirrorCmd 1;
BA_ "GenSigSendType" SG_ 831 PassMirrorCmd 3;
BA_ "U_P708_MY2023_Rx" SG_ 831 PassMirrorCmd 1;
BA_ "U_P702_MY2024_Rx" SG_ 831 PassMirrorCmd 1;
BA_ "U_V713N_MY2022_Tx" SG_ 831 PassMirrorCmd 1;
BA_ "U_P708_MY2023_Tx" SG_ 831 PassMirrorCmd 1;
BA_ "U_P702_MY2024_Tx" SG_ 831 PassMirrorCmd 1;
BA_ "GenSigSendType" SG_ 831 DipMirrorPosPassenger 3;
BA_ "U_P708_MY2023_Rx" SG_ 831 DipMirrorPosPassenger 1;
BA_ "U_P702_MY2024_Rx" SG_ 831 DipMirrorPosPassenger 1;
BA_ "U_P708_MY2023_Tx" SG_ 831 DipMirrorPosPassenger 1;
BA_ "U_P702_MY2024_Tx" SG_ 831 DipMirrorPosPassenger 1;
BA_ "GenSigSendType" SG_ 831 ActiveStoragePassenger 3;
BA_ "U_P708_MY2023_Rx" SG_ 831 ActiveStoragePassenger 1;
BA_ "U_P702_MY2024_Rx" SG_ 831 ActiveStoragePassenger 1;
BA_ "U_P708_MY2023_Tx" SG_ 831 ActiveStoragePassenger 1;
BA_ "U_P702_MY2024_Tx" SG_ 831 ActiveStoragePassenger 1;
BA_ "WakeupSignal" SG_ 831 RearDriverWindowPos 1;
BA_ "GenSigSendType" SG_ 831 RearDriverWindowPos 3;
BA_ "ECGUsedRxSignal" SG_ 831 RearDriverWindowPos 1;
BA_ "U_P708_MY2023_Rx" SG_ 831 RearDriverWindowPos 1;
BA_ "U_CDX74X_MY2024_Rx" SG_ 831 RearDriverWindowPos 1;
BA_ "U_P702_MY2024_Rx" SG_ 831 RearDriverWindowPos 1;
BA_ "U_V713N_MY2022_Tx" SG_ 831 RearDriverWindowPos 1;
BA_ "U_P708_MY2023_Tx" SG_ 831 RearDriverWindowPos 1;
BA_ "U_P702_MY2024_Tx" SG_ 831 RearDriverWindowPos 1;
BA_ "WakeupSignal" SG_ 831 DriverWindowPosition 1;
BA_ "GenSigSendType" SG_ 831 DriverWindowPosition 3;
BA_ "ECGUsedRxSignal" SG_ 831 DriverWindowPosition 1;
BA_ "U_P708_MY2023_Rx" SG_ 831 DriverWindowPosition 1;
BA_ "U_CDX74X_MY2024_Rx" SG_ 831 DriverWindowPosition 1;
BA_ "U_P702_MY2024_Rx" SG_ 831 DriverWindowPosition 1;
BA_ "U_P708_MY2023_Tx" SG_ 831 DriverWindowPosition 1;
BA_ "U_P702_MY2024_Tx" SG_ 831 DriverWindowPosition 1;
BA_ "U_P708_MY2023_Rx" SG_ 1258 TrlrCamraCalib_D_Stat 1;
BA_ "U_P702_MY2024_Rx" SG_ 1258 TrlrCamraCalib_D_Stat 1;
BA_ "U_P708_MY2023_Rx" SG_ 1258 TrlrCamraView_D_Stat 1;
BA_ "U_P702_MY2024_Rx" SG_ 1258 TrlrCamraView_D_Stat 1;
BA_ "U_P708_MY2023_Rx" SG_ 648 TrlrCamraCalib_D_Rq 1;
BA_ "U_P702_MY2024_Rx" SG_ 648 TrlrCamraCalib_D_Rq 1;
BA_ "U_P708_MY2023_Rx" SG_ 1158 SodAltRight_D2_StatAft 1;
BA_ "U_P702_MY2024_Rx" SG_ 1158 SodAltRight_D2_StatAft 1;
BA_ "U_P708_MY2023_Rx" SG_ 1157 SodAltLeft_D2_StatAft 1;
BA_ "U_P702_MY2024_Rx" SG_ 1157 SodAltLeft_D2_StatAft 1;
BA_ "GenSigStartValue" SG_ 1208 Btt_L2_Actl2 124;
BA_ "U_P708_MY2023_Rx" SG_ 1208 Btt_L2_Actl2 1;
BA_ "U_P702_MY2024_Rx" SG_ 1208 Btt_L2_Actl2 1;
BA_ "WakeupSignal" SG_ 1218 DrStopTglRl_No_Actl 1;
BA_ "WakeupSignal" SG_ 1218 DrStopTglRr_No_Actl 1;
BA_ "WakeupSignal" SG_ 1218 DrPsngrRearLck_D_Stat 1;
BA_ "WakeupSignal" SG_ 1218 DrDrvRearLck_D_Stat 1;
BA_ "WakeupSignal" SG_ 1218 LatchFdbck_B_Stat 1;
BA_ "WakeupSignal" SG_ 1218 FecSwtchExtLck_D_Stat 1;
BA_ "WakeupSignal" SG_ 1218 DrPsngrLck_D_Stat 1;
BA_ "WakeupSignal" SG_ 1218 DrDrvLck_D_Stat 1;
BA_ "WakeupSignal" SG_ 1218 BecSwtchExtLck_D_Stat 1;
BA_ "WakeupSignal" SG_ 1218 BecSwtch2ExtLck_D_Stat 1;
BA_ "U_P708_MY2023_Tx" SG_ 121 SteSnsDiagData_No_Actl 1;
BA_ "U_P702_MY2024_Tx" SG_ 121 SteSnsDiagData_No_Actl 1;
BA_ "GenSigSendType" SG_ 1972 TesterPhysicalReqDCMH 3;
BA_ "GenSigSendType" SG_ 1971 TesterPhysicalReqDCMG 3;
BA_ "GenSigSendType" SG_ 2613272689 SymKeyPhysHCMtoGWM_ECG 3;
BA_ "ECGUsedRxSignal" SG_ 2613272689 SymKeyPhysHCMtoGWM_ECG 1;
BA_ "U_P708_MY2023_Rx" SG_ 2613272689 SymKeyPhysHCMtoGWM_ECG 1;
BA_ "U_P702_MY2024_Rx" SG_ 2613272689 SymKeyPhysHCMtoGWM_ECG 1;
BA_ "U_P708_MY2023_Tx" SG_ 2613272689 SymKeyPhysHCMtoGWM_ECG 1;
BA_ "U_CDX74X_MY2024_Tx" SG_ 2613272689 SymKeyPhysHCMtoGWM_ECG 1;
BA_ "U_P702_MY2024_Tx" SG_ 2613272689 SymKeyPhysHCMtoGWM_ECG 1;
BA_ "GenSigSendType" SG_ 2613167320 SymKeyPhysGWM_ECGtoHCM 3;
BA_ "U_P708_MY2023_Rx" SG_ 2613167320 SymKeyPhysGWM_ECGtoHCM 1;
BA_ "U_P702_MY2024_Rx" SG_ 2613167320 SymKeyPhysGWM_ECGtoHCM 1;
BA_ "ECGUsedTxSignal" SG_ 2613167320 SymKeyPhysGWM_ECGtoHCM 1;
BA_ "U_P708_MY2023_Tx" SG_ 2613167320 SymKeyPhysGWM_ECGtoHCM 1;
BA_ "U_P702_MY2024_Tx" SG_ 2613167320 SymKeyPhysGWM_ECGtoHCM 1;
BA_ "GenSigSendType" SG_ 2609948888 OTAPhysGWM_ECGtoPBM 3;
BA_ "ECGUsedTxSignal" SG_ 2609948888 OTAPhysGWM_ECGtoPBM 1;
BA_ "U_P708_MY2023_Tx" SG_ 2609948888 OTAPhysGWM_ECGtoPBM 1;
BA_ "U_P702_MY2024_Tx" SG_ 2609948888 OTAPhysGWM_ECGtoPBM 1;
BA_ "GenSigSendType" SG_ 2610997464 PARSEDPhysGWM_ECGtoPBM 3;
BA_ "ECGUsedTxSignal" SG_ 2610997464 PARSEDPhysGWM_ECGtoPBM 1;
BA_ "U_P708_MY2023_Tx" SG_ 2610997464 PARSEDPhysGWM_ECGtoPBM 1;
BA_ "U_P702_MY2024_Tx" SG_ 2610997464 PARSEDPhysGWM_ECGtoPBM 1;
BA_ "GenSigSendType" SG_ 2612046040 PARSEDPushFcGWM_ECGtoPBM 3;
BA_ "ECGUsedTxSignal" SG_ 2612046040 PARSEDPushFcGWM_ECGtoPBM 1;
BA_ "U_P708_MY2023_Tx" SG_ 2612046040 PARSEDPushFcGWM_ECGtoPBM 1;
BA_ "U_P702_MY2024_Tx" SG_ 2612046040 PARSEDPushFcGWM_ECGtoPBM 1;
BA_ "GenSigSendType" SG_ 2613094616 SymKeyPhysGWM_ECGtoPBM 3;
BA_ "ECGUsedTxSignal" SG_ 2613094616 SymKeyPhysGWM_ECGtoPBM 1;
BA_ "U_P708_MY2023_Tx" SG_ 2613094616 SymKeyPhysGWM_ECGtoPBM 1;
BA_ "U_P702_MY2024_Tx" SG_ 2613094616 SymKeyPhysGWM_ECGtoPBM 1;
BA_ "GenSigStartValue" SG_ 1049 RearDiffLck_D_RqDrv3 2;
BA_ "GenSigStartValue" SG_ 1049 FrontDiffLck_D_RqDrv3 2;
BA_ "GenSigStartValue" SG_ 1049 SelDrvMde_D_RqDrv 31;
BA_ "U_P708_MY2023_Rx" SG_ 1049 PersTurnSglView_D_RqMnu 1;
BA_ "U_V710_MY2023_Rx" SG_ 1049 PersTurnSglView_D_RqMnu 1;
BA_ "U_P702_MY2024_Rx" SG_ 1049 PersTurnSglView_D_RqMnu 1;
BA_ "U_P708_MY2023_Rx" SG_ 1049 CamraFrnt_B_RqMnu 1;
BA_ "U_V710_MY2023_Rx" SG_ 1049 CamraFrnt_B_RqMnu 1;
BA_ "U_P702_MY2024_Rx" SG_ 1049 CamraFrnt_B_RqMnu 1;
BA_ "GenSigSendType" SG_ 2611024088 PARSEDPhysGWM_ECGtoSCCM 3;
BA_ "U_P708_MY2023_Rx" SG_ 2611024088 PARSEDPhysGWM_ECGtoSCCM 1;
BA_ "ECGUsedTxSignal" SG_ 2611024088 PARSEDPhysGWM_ECGtoSCCM 1;
BA_ "U_P708_MY2023_Tx" SG_ 2611024088 PARSEDPhysGWM_ECGtoSCCM 1;
BA_ "U_P702_MY2024_Tx" SG_ 2611024088 PARSEDPhysGWM_ECGtoSCCM 1;
BA_ "U_CDX707_MY2023_Rx" SG_ 595 DrvIdDelete_No_Rq 1;
BA_ "GenSigStartValue" SG_ 595 DrvIdMde_D_Rq 1;
BA_ "U_CDX707_MY2023_Rx" SG_ 595 DrvIdMde_D_Rq 1;
BA_ "U_P708_MY2023_Rx" SG_ 542 LocationServices_3 1;
BA_ "U_V710_MY2023_Rx" SG_ 542 LocationServices_3 1;
BA_ "U_P702_MY2024_Rx" SG_ 542 LocationServices_3 1;
BA_ "ECGUsedRxSignal" SG_ 2612224078 PARSEDPushLDCMBtoGWM_ECG 1;
BA_ "U_P708_MY2023_Rx" SG_ 2612224078 PARSEDPushLDCMBtoGWM_ECG 1;
BA_ "U_P702_MY2024_Rx" SG_ 2612224078 PARSEDPushLDCMBtoGWM_ECG 1;
BA_ "U_P708_MY2023_Tx" SG_ 2612224078 PARSEDPushLDCMBtoGWM_ECG 1;
BA_ "U_CDX74X_MY2024_Tx" SG_ 2612224078 PARSEDPushLDCMBtoGWM_ECG 1;
BA_ "U_P702_MY2024_Tx" SG_ 2612224078 PARSEDPushLDCMBtoGWM_ECG 1;
BA_ "GenSigSendType" SG_ 2612224079 PARSEDPushLDCMAtoGWM_ECG 3;
BA_ "ECGUsedRxSignal" SG_ 2612224079 PARSEDPushLDCMAtoGWM_ECG 1;
BA_ "U_P708_MY2023_Rx" SG_ 2612224079 PARSEDPushLDCMAtoGWM_ECG 1;
BA_ "U_P702_MY2024_Rx" SG_ 2612224079 PARSEDPushLDCMAtoGWM_ECG 1;
BA_ "U_CDX74X_MY2024_Tx" SG_ 2612224079 PARSEDPushLDCMAtoGWM_ECG 1;
BA_ "U_P702_MY2024_Tx" SG_ 2612224079 PARSEDPushLDCMAtoGWM_ECG 1;
BA_ "GenSigSendType" SG_ 2612082904 PARSEDPushFcGWM_ECGtoLDCMB 3;
BA_ "U_P708_MY2023_Rx" SG_ 2612082904 PARSEDPushFcGWM_ECGtoLDCMB 1;
BA_ "U_CDX74X_MY2024_Rx" SG_ 2612082904 PARSEDPushFcGWM_ECGtoLDCMB 1;
BA_ "U_P702_MY2024_Rx" SG_ 2612082904 PARSEDPushFcGWM_ECGtoLDCMB 1;
BA_ "ECGUsedTxSignal" SG_ 2612082904 PARSEDPushFcGWM_ECGtoLDCMB 1;
BA_ "U_P708_MY2023_Tx" SG_ 2612082904 PARSEDPushFcGWM_ECGtoLDCMB 1;
BA_ "U_P702_MY2024_Tx" SG_ 2612082904 PARSEDPushFcGWM_ECGtoLDCMB 1;
BA_ "GenSigSendType" SG_ 2612083928 PARSEDPushFcGWM_ECGtoLDCMA 3;
BA_ "U_P708_MY2023_Rx" SG_ 2612083928 PARSEDPushFcGWM_ECGtoLDCMA 1;
BA_ "U_CDX74X_MY2024_Rx" SG_ 2612083928 PARSEDPushFcGWM_ECGtoLDCMA 1;
BA_ "U_P702_MY2024_Rx" SG_ 2612083928 PARSEDPushFcGWM_ECGtoLDCMA 1;
BA_ "ECGUsedTxSignal" SG_ 2612083928 PARSEDPushFcGWM_ECGtoLDCMA 1;
BA_ "U_P708_MY2023_Tx" SG_ 2612083928 PARSEDPushFcGWM_ECGtoLDCMA 1;
BA_ "U_P702_MY2024_Tx" SG_ 2612083928 PARSEDPushFcGWM_ECGtoLDCMA 1;
BA_ "GenSigSendType" SG_ 2611175502 PARSEDPhysLDCMBtoGWM_ECG 3;
BA_ "ECGUsedRxSignal" SG_ 2611175502 PARSEDPhysLDCMBtoGWM_ECG 1;
BA_ "U_P708_MY2023_Rx" SG_ 2611175502 PARSEDPhysLDCMBtoGWM_ECG 1;
BA_ "U_P702_MY2024_Rx" SG_ 2611175502 PARSEDPhysLDCMBtoGWM_ECG 1;
BA_ "U_P708_MY2023_Tx" SG_ 2611175502 PARSEDPhysLDCMBtoGWM_ECG 1;
BA_ "U_CDX74X_MY2024_Tx" SG_ 2611175502 PARSEDPhysLDCMBtoGWM_ECG 1;
BA_ "U_P702_MY2024_Tx" SG_ 2611175502 PARSEDPhysLDCMBtoGWM_ECG 1;
BA_ "GenSigSendType" SG_ 2611175503 PARSEDPhysLDCMAtoGWM_ECG 3;
BA_ "ECGUsedRxSignal" SG_ 2611175503 PARSEDPhysLDCMAtoGWM_ECG 1;
BA_ "U_P708_MY2023_Rx" SG_ 2611175503 PARSEDPhysLDCMAtoGWM_ECG 1;
BA_ "U_P702_MY2024_Rx" SG_ 2611175503 PARSEDPhysLDCMAtoGWM_ECG 1;
BA_ "U_P708_MY2023_Tx" SG_ 2611175503 PARSEDPhysLDCMAtoGWM_ECG 1;
BA_ "U_CDX74X_MY2024_Tx" SG_ 2611175503 PARSEDPhysLDCMAtoGWM_ECG 1;
BA_ "U_P702_MY2024_Tx" SG_ 2611175503 PARSEDPhysLDCMAtoGWM_ECG 1;
BA_ "GenSigSendType" SG_ 2611034328 PARSEDPhysGWM_ECGtoLDCMB 3;
BA_ "U_P708_MY2023_Rx" SG_ 2611034328 PARSEDPhysGWM_ECGtoLDCMB 1;
BA_ "U_CDX74X_MY2024_Rx" SG_ 2611034328 PARSEDPhysGWM_ECGtoLDCMB 1;
BA_ "U_P702_MY2024_Rx" SG_ 2611034328 PARSEDPhysGWM_ECGtoLDCMB 1;
BA_ "ECGUsedTxSignal" SG_ 2611034328 PARSEDPhysGWM_ECGtoLDCMB 1;
BA_ "U_P708_MY2023_Tx" SG_ 2611034328 PARSEDPhysGWM_ECGtoLDCMB 1;
BA_ "U_P702_MY2024_Tx" SG_ 2611034328 PARSEDPhysGWM_ECGtoLDCMB 1;
BA_ "GenSigSendType" SG_ 2611035352 PARSEDPhysGWM_ECGtoLDCMA 3;
BA_ "U_P708_MY2023_Rx" SG_ 2611035352 PARSEDPhysGWM_ECGtoLDCMA 1;
BA_ "U_CDX74X_MY2024_Rx" SG_ 2611035352 PARSEDPhysGWM_ECGtoLDCMA 1;
BA_ "U_P702_MY2024_Rx" SG_ 2611035352 PARSEDPhysGWM_ECGtoLDCMA 1;
BA_ "ECGUsedTxSignal" SG_ 2611035352 PARSEDPhysGWM_ECGtoLDCMA 1;
BA_ "U_P708_MY2023_Tx" SG_ 2611035352 PARSEDPhysGWM_ECGtoLDCMA 1;
BA_ "U_P702_MY2024_Tx" SG_ 2611035352 PARSEDPhysGWM_ECGtoLDCMA 1;
BA_ "GenSigSendType" SG_ 2610126926 OTAPhysLDCMBtoGWM_ECG 3;
BA_ "ECGUsedRxSignal" SG_ 2610126926 OTAPhysLDCMBtoGWM_ECG 1;
BA_ "U_P708_MY2023_Rx" SG_ 2610126926 OTAPhysLDCMBtoGWM_ECG 1;
BA_ "U_P702_MY2024_Rx" SG_ 2610126926 OTAPhysLDCMBtoGWM_ECG 1;
BA_ "U_P708_MY2023_Tx" SG_ 2610126926 OTAPhysLDCMBtoGWM_ECG 1;
BA_ "U_CDX74X_MY2024_Tx" SG_ 2610126926 OTAPhysLDCMBtoGWM_ECG 1;
BA_ "U_P702_MY2024_Tx" SG_ 2610126926 OTAPhysLDCMBtoGWM_ECG 1;
BA_ "GenSigSendType" SG_ 2610126927 OTAPhysLDCMAtoGWM_ECG 3;
BA_ "ECGUsedRxSignal" SG_ 2610126927 OTAPhysLDCMAtoGWM_ECG 1;
BA_ "U_P708_MY2023_Rx" SG_ 2610126927 OTAPhysLDCMAtoGWM_ECG 1;
BA_ "U_P702_MY2024_Rx" SG_ 2610126927 OTAPhysLDCMAtoGWM_ECG 1;
BA_ "U_P708_MY2023_Tx" SG_ 2610126927 OTAPhysLDCMAtoGWM_ECG 1;
BA_ "U_CDX74X_MY2024_Tx" SG_ 2610126927 OTAPhysLDCMAtoGWM_ECG 1;
BA_ "U_P702_MY2024_Tx" SG_ 2610126927 OTAPhysLDCMAtoGWM_ECG 1;
BA_ "GenSigSendType" SG_ 2609985752 OTAPhysGWM_ECGtoLDCMB 3;
BA_ "U_P708_MY2023_Rx" SG_ 2609985752 OTAPhysGWM_ECGtoLDCMB 1;
BA_ "U_CDX74X_MY2024_Rx" SG_ 2609985752 OTAPhysGWM_ECGtoLDCMB 1;
BA_ "U_P702_MY2024_Rx" SG_ 2609985752 OTAPhysGWM_ECGtoLDCMB 1;
BA_ "ECGUsedTxSignal" SG_ 2609985752 OTAPhysGWM_ECGtoLDCMB 1;
BA_ "U_P708_MY2023_Tx" SG_ 2609985752 OTAPhysGWM_ECGtoLDCMB 1;
BA_ "U_P702_MY2024_Tx" SG_ 2609985752 OTAPhysGWM_ECGtoLDCMB 1;
BA_ "GenSigSendType" SG_ 2609986776 OTAPhysGWM_ECGtoLDCMA 3;
BA_ "U_P708_MY2023_Rx" SG_ 2609986776 OTAPhysGWM_ECGtoLDCMA 1;
BA_ "U_CDX74X_MY2024_Rx" SG_ 2609986776 OTAPhysGWM_ECGtoLDCMA 1;
BA_ "U_P702_MY2024_Rx" SG_ 2609986776 OTAPhysGWM_ECGtoLDCMA 1;
BA_ "ECGUsedTxSignal" SG_ 2609986776 OTAPhysGWM_ECGtoLDCMA 1;
BA_ "U_P708_MY2023_Tx" SG_ 2609986776 OTAPhysGWM_ECGtoLDCMA 1;
BA_ "U_P702_MY2024_Tx" SG_ 2609986776 OTAPhysGWM_ECGtoLDCMA 1;
BA_ "GenSigSendType" SG_ 1791 TesterPhysicalResLDCMB 3;
BA_ "U_P708_MY2023_Tx" SG_ 1791 TesterPhysicalResLDCMB 1;
BA_ "U_CDX74X_MY2024_Tx" SG_ 1791 TesterPhysicalResLDCMB 1;
BA_ "U_P702_MY2024_Tx" SG_ 1791 TesterPhysicalResLDCMB 1;
BA_ "GenSigSendType" SG_ 1790 TesterPhysicalResLDCMA 3;
BA_ "U_P708_MY2023_Tx" SG_ 1790 TesterPhysicalResLDCMA 1;
BA_ "U_CDX74X_MY2024_Tx" SG_ 1790 TesterPhysicalResLDCMA 1;
BA_ "U_P702_MY2024_Tx" SG_ 1790 TesterPhysicalResLDCMA 1;
BA_ "GenSigSendType" SG_ 1783 TesterPhysicalReqLDCMB 3;
BA_ "U_P708_MY2023_Rx" SG_ 1783 TesterPhysicalReqLDCMB 1;
BA_ "U_CDX74X_MY2024_Rx" SG_ 1783 TesterPhysicalReqLDCMB 1;
BA_ "U_P702_MY2024_Rx" SG_ 1783 TesterPhysicalReqLDCMB 1;
BA_ "GenSigSendType" SG_ 1782 TesterPhysicalReqLDCMA 3;
BA_ "U_P708_MY2023_Rx" SG_ 1782 TesterPhysicalReqLDCMA 1;
BA_ "U_CDX74X_MY2024_Rx" SG_ 1782 TesterPhysicalReqLDCMA 1;
BA_ "U_P702_MY2024_Rx" SG_ 1782 TesterPhysicalReqLDCMA 1;
BA_ "GenSigStartValue" SG_ 739 BptDly_T_RqMnu 62;
BA_ "GenSigStartValue" SG_ 739 BptMnSoc_L_RqMnu 8190;
BA_ "GenSigStartValue" SG_ 739 OnbTrgtSocOvrrd_Pc_Rq 100;
BA_ "WakeupSignal" SG_ 739 HMI_HMIMode_St 1;
BA_ "U_P708_MY2023_Rx" SG_ 739 HMI_HMIMode_St 1;
BA_ "U_P702_MY2024_Rx" SG_ 739 HMI_HMIMode_St 1;
BA_ "GenSigSendType" SG_ 129 SelDrvMdeSwtch4_D_Stat4 3;
BA_ "U_V713N_MY2022_Tx" SG_ 129 SelDrvMdeSwtch4_D_Stat4 1;
BA_ "U_V713AV_MY2022_Tx" SG_ 129 SelDrvMdeSwtch4_D_Stat4 1;
BA_ "U_P708_MY2023_Tx" SG_ 129 SelDrvMdeSwtch4_D_Stat4 1;
BA_ "U_V710_MY2023_Tx" SG_ 129 SelDrvMdeSwtch4_D_Stat4 1;
BA_ "GenSigSendType" SG_ 129 EngExhMdeQuiet_B_RqDrv2 3;
BA_ "U_V713AV_MY2022_Tx" SG_ 129 EngExhMdeQuiet_B_RqDrv2 1;
BA_ "U_P708_MY2023_Tx" SG_ 129 EngExhMdeQuiet_B_RqDrv2 1;
BA_ "U_P702_MY2024_Tx" SG_ 129 EngExhMdeQuiet_B_RqDrv2 1;
BA_ "GenSigSendType" SG_ 129 SelDrvMdeSwtch3_D_Stat4 3;
BA_ "U_P708_MY2023_Tx" SG_ 129 SelDrvMdeSwtch3_D_Stat4 1;
BA_ "U_V710_MY2023_Tx" SG_ 129 SelDrvMdeSwtch3_D_Stat4 1;
BA_ "U_P702_MY2024_Tx" SG_ 129 SelDrvMdeSwtch3_D_Stat4 1;
BA_ "GenSigSendType" SG_ 129 SelDrvMdeSwtch2_D_Stat4 3;
BA_ "U_P708_MY2023_Tx" SG_ 129 SelDrvMdeSwtch2_D_Stat4 1;
BA_ "U_V710_MY2023_Tx" SG_ 129 SelDrvMdeSwtch2_D_Stat4 1;
BA_ "U_P702_MY2024_Tx" SG_ 129 SelDrvMdeSwtch2_D_Stat4 1;
BA_ "GenSigSendType" SG_ 129 SelDrvMdeSwtch1_D_Stat4 3;
BA_ "U_P708_MY2023_Tx" SG_ 129 SelDrvMdeSwtch1_D_Stat4 1;
BA_ "U_V710_MY2023_Tx" SG_ 129 SelDrvMdeSwtch1_D_Stat4 1;
BA_ "U_P702_MY2024_Tx" SG_ 129 SelDrvMdeSwtch1_D_Stat4 1;
BA_ "GenSigSendType" SG_ 129 PoliceAux4Swtch_B_Stat 3;
BA_ "U_P708_MY2023_Tx" SG_ 129 PoliceAux4Swtch_B_Stat 1;
BA_ "U_P702_MY2024_Tx" SG_ 129 PoliceAux4Swtch_B_Stat 1;
BA_ "GenSigSendType" SG_ 129 PoliceAux3Swtch_B_Stat 3;
BA_ "U_P708_MY2023_Tx" SG_ 129 PoliceAux3Swtch_B_Stat 1;
BA_ "U_P702_MY2024_Tx" SG_ 129 PoliceAux3Swtch_B_Stat 1;
BA_ "GenSigSendType" SG_ 129 PoliceAux2Swtch_B_Stat 3;
BA_ "U_P708_MY2023_Tx" SG_ 129 PoliceAux2Swtch_B_Stat 1;
BA_ "U_P702_MY2024_Tx" SG_ 129 PoliceAux2Swtch_B_Stat 1;
BA_ "GenSigSendType" SG_ 129 PoliceAux1Swtch_B_Stat 3;
BA_ "U_P708_MY2023_Tx" SG_ 129 PoliceAux1Swtch_B_Stat 1;
BA_ "U_P702_MY2024_Tx" SG_ 129 PoliceAux1Swtch_B_Stat 1;
BA_ "WakeupSignal" SG_ 129 SteWhlSwtchView_B_Stat 1;
BA_ "GenSigSendType" SG_ 129 SteWhlSwtchView_B_Stat 3;
BA_ "U_V713N_MY2022_Tx" SG_ 129 SteWhlSwtchView_B_Stat 1;
BA_ "U_V713AV_MY2022_Tx" SG_ 129 SteWhlSwtchView_B_Stat 1;
BA_ "U_P708_MY2023_Tx" SG_ 129 SteWhlSwtchView_B_Stat 1;
BA_ "U_V710_MY2023_Tx" SG_ 129 SteWhlSwtchView_B_Stat 1;
BA_ "U_P702_MY2024_Tx" SG_ 129 SteWhlSwtchView_B_Stat 1;
BA_ "WakeupSignal" SG_ 129 SteWhlSwtchSet_B_Stat 1;
BA_ "GenSigSendType" SG_ 129 SteWhlSwtchSet_B_Stat 3;
BA_ "U_V713N_MY2022_Tx" SG_ 129 SteWhlSwtchSet_B_Stat 1;
BA_ "U_V713AV_MY2022_Tx" SG_ 129 SteWhlSwtchSet_B_Stat 1;
BA_ "U_P708_MY2023_Tx" SG_ 129 SteWhlSwtchSet_B_Stat 1;
BA_ "U_V710_MY2023_Tx" SG_ 129 SteWhlSwtchSet_B_Stat 1;
BA_ "U_P702_MY2024_Tx" SG_ 129 SteWhlSwtchSet_B_Stat 1;
BA_ "WakeupSignal" SG_ 129 SteWhlSwtchPhon_B_Stat 1;
BA_ "GenSigSendType" SG_ 129 SteWhlSwtchPhon_B_Stat 3;
BA_ "U_V713N_MY2022_Tx" SG_ 129 SteWhlSwtchPhon_B_Stat 1;
BA_ "U_V713AV_MY2022_Tx" SG_ 129 SteWhlSwtchPhon_B_Stat 1;
BA_ "U_P708_MY2023_Tx" SG_ 129 SteWhlSwtchPhon_B_Stat 1;
BA_ "U_V710_MY2023_Tx" SG_ 129 SteWhlSwtchPhon_B_Stat 1;
BA_ "U_P702_MY2024_Tx" SG_ 129 SteWhlSwtchPhon_B_Stat 1;
BA_ "WakeupSignal" SG_ 129 SteWhlSwtchNav_B_Stat 1;
BA_ "GenSigSendType" SG_ 129 SteWhlSwtchNav_B_Stat 3;
BA_ "U_V713N_MY2022_Tx" SG_ 129 SteWhlSwtchNav_B_Stat 1;
BA_ "U_V713AV_MY2022_Tx" SG_ 129 SteWhlSwtchNav_B_Stat 1;
BA_ "U_P708_MY2023_Tx" SG_ 129 SteWhlSwtchNav_B_Stat 1;
BA_ "U_V710_MY2023_Tx" SG_ 129 SteWhlSwtchNav_B_Stat 1;
BA_ "U_P702_MY2024_Tx" SG_ 129 SteWhlSwtchNav_B_Stat 1;
BA_ "WakeupSignal" SG_ 129 SteWhlSwtchMed_B_Stat 1;
BA_ "GenSigSendType" SG_ 129 SteWhlSwtchMed_B_Stat 3;
BA_ "U_V713N_MY2022_Tx" SG_ 129 SteWhlSwtchMed_B_Stat 1;
BA_ "U_V713AV_MY2022_Tx" SG_ 129 SteWhlSwtchMed_B_Stat 1;
BA_ "U_P708_MY2023_Tx" SG_ 129 SteWhlSwtchMed_B_Stat 1;
BA_ "U_V710_MY2023_Tx" SG_ 129 SteWhlSwtchMed_B_Stat 1;
BA_ "U_P702_MY2024_Tx" SG_ 129 SteWhlSwtchMed_B_Stat 1;
BA_ "WakeupSignal" SG_ 129 SteWhlSwtchIod_B_Stat 1;
BA_ "GenSigSendType" SG_ 129 SteWhlSwtchIod_B_Stat 3;
BA_ "U_V713N_MY2022_Tx" SG_ 129 SteWhlSwtchIod_B_Stat 1;
BA_ "U_V713AV_MY2022_Tx" SG_ 129 SteWhlSwtchIod_B_Stat 1;
BA_ "U_P708_MY2023_Tx" SG_ 129 SteWhlSwtchIod_B_Stat 1;
BA_ "U_V710_MY2023_Tx" SG_ 129 SteWhlSwtchIod_B_Stat 1;
BA_ "U_P702_MY2024_Tx" SG_ 129 SteWhlSwtchIod_B_Stat 1;
BA_ "WakeupSignal" SG_ 129 SteWhlSwtchHud_B_Stat 1;
BA_ "GenSigSendType" SG_ 129 SteWhlSwtchHud_B_Stat 3;
BA_ "U_V713N_MY2022_Tx" SG_ 129 SteWhlSwtchHud_B_Stat 1;
BA_ "U_V713AV_MY2022_Tx" SG_ 129 SteWhlSwtchHud_B_Stat 1;
BA_ "U_P708_MY2023_Tx" SG_ 129 SteWhlSwtchHud_B_Stat 1;
BA_ "U_V710_MY2023_Tx" SG_ 129 SteWhlSwtchHud_B_Stat 1;
BA_ "U_P702_MY2024_Tx" SG_ 129 SteWhlSwtchHud_B_Stat 1;
BA_ "WakeupSignal" SG_ 129 SteWhlSwtchBack_B_Stat 1;
BA_ "GenSigSendType" SG_ 129 SteWhlSwtchBack_B_Stat 3;
BA_ "U_V713N_MY2022_Tx" SG_ 129 SteWhlSwtchBack_B_Stat 1;
BA_ "U_V713AV_MY2022_Tx" SG_ 129 SteWhlSwtchBack_B_Stat 1;
BA_ "U_P708_MY2023_Tx" SG_ 129 SteWhlSwtchBack_B_Stat 1;
BA_ "U_V710_MY2023_Tx" SG_ 129 SteWhlSwtchBack_B_Stat 1;
BA_ "U_P702_MY2024_Tx" SG_ 129 SteWhlSwtchBack_B_Stat 1;
BA_ "WakeupSignal" SG_ 129 SteWhlSwtchMenu_B_Stat 1;
BA_ "GenSigSendType" SG_ 129 SteWhlSwtchMenu_B_Stat 3;
BA_ "U_V713N_MY2022_Tx" SG_ 129 SteWhlSwtchMenu_B_Stat 1;
BA_ "U_V713AV_MY2022_Tx" SG_ 129 SteWhlSwtchMenu_B_Stat 1;
BA_ "U_P708_MY2023_Tx" SG_ 129 SteWhlSwtchMenu_B_Stat 1;
BA_ "U_V710_MY2023_Tx" SG_ 129 SteWhlSwtchMenu_B_Stat 1;
BA_ "U_P702_MY2024_Tx" SG_ 129 SteWhlSwtchMenu_B_Stat 1;
BA_ "GenSigSendType" SG_ 129 SteEffortInc_B_RqDrv 3;
BA_ "U_V713N_MY2022_Tx" SG_ 129 SteEffortInc_B_RqDrv 1;
BA_ "U_V713AV_MY2022_Tx" SG_ 129 SteEffortInc_B_RqDrv 1;
BA_ "U_P708_MY2023_Tx" SG_ 129 SteEffortInc_B_RqDrv 1;
BA_ "GenSigSendType" SG_ 129 SelDrvMdeInc_B_RqDrv 3;
BA_ "U_V713N_MY2022_Tx" SG_ 129 SelDrvMdeInc_B_RqDrv 1;
BA_ "U_V713AV_MY2022_Tx" SG_ 129 SelDrvMdeInc_B_RqDrv 1;
BA_ "U_P708_MY2023_Tx" SG_ 129 SelDrvMdeInc_B_RqDrv 1;
BA_ "U_V710_MY2023_Tx" SG_ 129 SelDrvMdeInc_B_RqDrv 1;
BA_ "U_P702_MY2024_Tx" SG_ 129 SelDrvMdeInc_B_RqDrv 1;
BA_ "GenSigSendType" SG_ 129 SelDrvMdeDec_B_RqDrv 3;
BA_ "U_V713N_MY2022_Tx" SG_ 129 SelDrvMdeDec_B_RqDrv 1;
BA_ "U_V713AV_MY2022_Tx" SG_ 129 SelDrvMdeDec_B_RqDrv 1;
BA_ "U_P708_MY2023_Tx" SG_ 129 SelDrvMdeDec_B_RqDrv 1;
BA_ "U_V710_MY2023_Tx" SG_ 129 SelDrvMdeDec_B_RqDrv 1;
BA_ "U_P702_MY2024_Tx" SG_ 129 SelDrvMdeDec_B_RqDrv 1;
BA_ "GenSigSendType" SG_ 129 SuspDampInc_B_RqDrv 3;
BA_ "U_V713N_MY2022_Tx" SG_ 129 SuspDampInc_B_RqDrv 1;
BA_ "U_V713AV_MY2022_Tx" SG_ 129 SuspDampInc_B_RqDrv 1;
BA_ "U_P708_MY2023_Tx" SG_ 129 SuspDampInc_B_RqDrv 1;
BA_ "U_V710_MY2023_Tx" SG_ 129 SuspDampInc_B_RqDrv 1;
BA_ "WakeupSignal" SG_ 129 SteWhlSwtchUp_B_Stat 1;
BA_ "GenSigSendType" SG_ 129 SteWhlSwtchUp_B_Stat 3;
BA_ "U_V713N_MY2022_Tx" SG_ 129 SteWhlSwtchUp_B_Stat 1;
BA_ "U_V713AV_MY2022_Tx" SG_ 129 SteWhlSwtchUp_B_Stat 1;
BA_ "U_P708_MY2023_Tx" SG_ 129 SteWhlSwtchUp_B_Stat 1;
BA_ "U_V710_MY2023_Tx" SG_ 129 SteWhlSwtchUp_B_Stat 1;
BA_ "U_P702_MY2024_Tx" SG_ 129 SteWhlSwtchUp_B_Stat 1;
BA_ "WakeupSignal" SG_ 129 SteWhlSwtchRght_B_Stat 1;
BA_ "GenSigSendType" SG_ 129 SteWhlSwtchRght_B_Stat 3;
BA_ "U_V713N_MY2022_Tx" SG_ 129 SteWhlSwtchRght_B_Stat 1;
BA_ "U_V713AV_MY2022_Tx" SG_ 129 SteWhlSwtchRght_B_Stat 1;
BA_ "U_P708_MY2023_Tx" SG_ 129 SteWhlSwtchRght_B_Stat 1;
BA_ "U_V710_MY2023_Tx" SG_ 129 SteWhlSwtchRght_B_Stat 1;
BA_ "U_P702_MY2024_Tx" SG_ 129 SteWhlSwtchRght_B_Stat 1;
BA_ "WakeupSignal" SG_ 129 SteWhlSwtchOk_B_Stat 1;
BA_ "GenSigSendType" SG_ 129 SteWhlSwtchOk_B_Stat 3;
BA_ "U_V713N_MY2022_Tx" SG_ 129 SteWhlSwtchOk_B_Stat 1;
BA_ "U_V713AV_MY2022_Tx" SG_ 129 SteWhlSwtchOk_B_Stat 1;
BA_ "U_P708_MY2023_Tx" SG_ 129 SteWhlSwtchOk_B_Stat 1;
BA_ "U_V710_MY2023_Tx" SG_ 129 SteWhlSwtchOk_B_Stat 1;
BA_ "U_P702_MY2024_Tx" SG_ 129 SteWhlSwtchOk_B_Stat 1;
BA_ "WakeupSignal" SG_ 129 SteWhlSwtchLeft_B_Stat 1;
BA_ "GenSigSendType" SG_ 129 SteWhlSwtchLeft_B_Stat 3;
BA_ "U_V713N_MY2022_Tx" SG_ 129 SteWhlSwtchLeft_B_Stat 1;
BA_ "U_V713AV_MY2022_Tx" SG_ 129 SteWhlSwtchLeft_B_Stat 1;
BA_ "U_P708_MY2023_Tx" SG_ 129 SteWhlSwtchLeft_B_Stat 1;
BA_ "U_V710_MY2023_Tx" SG_ 129 SteWhlSwtchLeft_B_Stat 1;
BA_ "U_P702_MY2024_Tx" SG_ 129 SteWhlSwtchLeft_B_Stat 1;
BA_ "WakeupSignal" SG_ 129 SteWhlSwtchDown_B_Stat 1;
BA_ "GenSigSendType" SG_ 129 SteWhlSwtchDown_B_Stat 3;
BA_ "U_V713N_MY2022_Tx" SG_ 129 SteWhlSwtchDown_B_Stat 1;
BA_ "U_V713AV_MY2022_Tx" SG_ 129 SteWhlSwtchDown_B_Stat 1;
BA_ "U_P708_MY2023_Tx" SG_ 129 SteWhlSwtchDown_B_Stat 1;
BA_ "U_V710_MY2023_Tx" SG_ 129 SteWhlSwtchDown_B_Stat 1;
BA_ "U_P702_MY2024_Tx" SG_ 129 SteWhlSwtchDown_B_Stat 1;
BA_ "GenSigSendType" SG_ 863 SteWhlHeat_D_Stat 3;
BA_ "U_P708_MY2023_Tx" SG_ 863 SteWhlHeat_D_Stat 1;
BA_ "U_P702_MY2024_Tx" SG_ 863 SteWhlHeat_D_Stat 1;
BA_ "U_P708_MY2023_Rx" SG_ 1116 TrlrAidSetup_D2_Rq 1;
BA_ "U_V710_MY2023_Rx" SG_ 1116 TrlrAidSetup_D2_Rq 1;
BA_ "U_P702_MY2024_Rx" SG_ 1116 TrlrAidSetup_D2_Rq 1;
BA_ "U_P708_MY2023_Rx" SG_ 1116 TrlrAidEnbl_D2_Rq 1;
BA_ "U_V710_MY2023_Rx" SG_ 1116 TrlrAidEnbl_D2_Rq 1;
BA_ "U_P702_MY2024_Rx" SG_ 1116 TrlrAidEnbl_D2_Rq 1;
BA_ "U_P708_MY2023_Rx" SG_ 1116 TrlrTrgtToBmpr_L_Actl 1;
BA_ "U_V710_MY2023_Rx" SG_ 1116 TrlrTrgtToBmpr_L_Actl 1;
BA_ "U_P702_MY2024_Rx" SG_ 1116 TrlrTrgtToBmpr_L_Actl 1;
BA_ "U_P708_MY2023_Rx" SG_ 1116 TrlrTrgtPtrnId_No_Mem 1;
BA_ "U_V710_MY2023_Rx" SG_ 1116 TrlrTrgtPtrnId_No_Mem 1;
BA_ "U_P702_MY2024_Rx" SG_ 1116 TrlrTrgtPtrnId_No_Mem 1;
BA_ "U_P708_MY2023_Rx" SG_ 1116 TrlrRvrseCancl_B_Rq 1;
BA_ "U_V710_MY2023_Rx" SG_ 1116 TrlrRvrseCancl_B_Rq 1;
BA_ "U_P702_MY2024_Rx" SG_ 1116 TrlrRvrseCancl_B_Rq 1;
BA_ "U_P708_MY2023_Rx" SG_ 1116 TrlrIdType_D_Stat 1;
BA_ "U_V710_MY2023_Rx" SG_ 1116 TrlrIdType_D_Stat 1;
BA_ "U_P702_MY2024_Rx" SG_ 1116 TrlrIdType_D_Stat 1;
BA_ "U_P708_MY2023_Rx" SG_ 1116 TrlrId_No_Actl 1;
BA_ "U_V710_MY2023_Rx" SG_ 1116 TrlrId_No_Actl 1;
BA_ "U_P702_MY2024_Rx" SG_ 1116 TrlrId_No_Actl 1;
BA_ "U_P708_MY2023_Rx" SG_ 1116 TrlrBallToBmpr_L_Actl 1;
BA_ "U_V710_MY2023_Rx" SG_ 1116 TrlrBallToBmpr_L_Actl 1;
BA_ "U_P702_MY2024_Rx" SG_ 1116 TrlrBallToBmpr_L_Actl 1;
BA_ "U_P708_MY2023_Rx" SG_ 1116 TrlrAxleToBmpr_L_Actl 1;
BA_ "U_V710_MY2023_Rx" SG_ 1116 TrlrAxleToBmpr_L_Actl 1;
BA_ "U_P702_MY2024_Rx" SG_ 1116 TrlrAxleToBmpr_L_Actl 1;
BA_ "U_P708_MY2023_Rx" SG_ 1116 TrlrAnOffstDir_D_Mem 1;
BA_ "U_V710_MY2023_Rx" SG_ 1116 TrlrAnOffstDir_D_Mem 1;
BA_ "U_P702_MY2024_Rx" SG_ 1116 TrlrAnOffstDir_D_Mem 1;
BA_ "U_P708_MY2023_Rx" SG_ 1116 TrlrAnOffst_An_Mem 1;
BA_ "U_V710_MY2023_Rx" SG_ 1116 TrlrAnOffst_An_Mem 1;
BA_ "U_P702_MY2024_Rx" SG_ 1116 TrlrAnOffst_An_Mem 1;
BA_ "U_P708_MY2023_Rx" SG_ 1116 TrlrTrgtOffst_L_Actl 1;
BA_ "U_V710_MY2023_Rx" SG_ 1116 TrlrTrgtOffst_L_Actl 1;
BA_ "U_P702_MY2024_Rx" SG_ 1116 TrlrTrgtOffst_L_Actl 1;
BA_ "GenSigSendType" SG_ 1237 ApaSlotRef2Y_L_Actl 3;
BA_ "U_P708_MY2023_Tx" SG_ 1237 ApaSlotRef2Y_L_Actl 1;
BA_ "U_V710_MY2023_Tx" SG_ 1237 ApaSlotRef2Y_L_Actl 1;
BA_ "U_P702_MY2024_Tx" SG_ 1237 ApaSlotRef2Y_L_Actl 1;
BA_ "GenSigSendType" SG_ 1237 ApaSlotRef2X_L_Actl 3;
BA_ "U_P708_MY2023_Tx" SG_ 1237 ApaSlotRef2X_L_Actl 1;
BA_ "U_V710_MY2023_Tx" SG_ 1237 ApaSlotRef2X_L_Actl 1;
BA_ "U_P702_MY2024_Tx" SG_ 1237 ApaSlotRef2X_L_Actl 1;
BA_ "GenSigSendType" SG_ 1237 ApaSlotRef1Y_L_Actl 3;
BA_ "U_P708_MY2023_Tx" SG_ 1237 ApaSlotRef1Y_L_Actl 1;
BA_ "U_V710_MY2023_Tx" SG_ 1237 ApaSlotRef1Y_L_Actl 1;
BA_ "U_P702_MY2024_Tx" SG_ 1237 ApaSlotRef1Y_L_Actl 1;
BA_ "GenSigSendType" SG_ 1237 ApaSlotRef1X_L_Actl 3;
BA_ "U_P708_MY2023_Tx" SG_ 1237 ApaSlotRef1X_L_Actl 1;
BA_ "U_V710_MY2023_Tx" SG_ 1237 ApaSlotRef1X_L_Actl 1;
BA_ "U_P702_MY2024_Tx" SG_ 1237 ApaSlotRef1X_L_Actl 1;
BA_ "GenSigStartValue" SG_ 1003 PersNoPos_D_Actl 4;
BA_ "GenSigStartValue" SG_ 1003 PersConflict_D_Actl 1;
BA_ "U_P708_MY2023_Rx" SG_ 1003 PersSetupRestr_D_Actl 1;
BA_ "U_P702_MY2024_Rx" SG_ 1003 PersSetupRestr_D_Actl 1;
BA_ "U_P708_MY2023_Rx" SG_ 1003 PersSetupAccessCtrl 1;
BA_ "U_P702_MY2024_Rx" SG_ 1003 PersSetupAccessCtrl 1;
BA_ "U_P708_MY2023_Rx" SG_ 1003 PersSetup_No_Actl 1;
BA_ "U_P702_MY2024_Rx" SG_ 1003 PersSetup_No_Actl 1;
BA_ "MetaData" SG_ 1003 RecallEvent_No_Cnt 1;
BA_ "U_P708_MY2023_Rx" SG_ 1003 RecallEvent_No_Cnt 1;
BA_ "U_V710_MY2023_Rx" SG_ 1003 RecallEvent_No_Cnt 1;
BA_ "U_P702_MY2024_Rx" SG_ 1003 RecallEvent_No_Cnt 1;
BA_ "GenSigStartValue" SG_ 1003 PersNo_D_Actl 4;
BA_ "U_P708_MY2023_Rx" SG_ 1003 PersNo_D_Actl 1;
BA_ "U_V710_MY2023_Rx" SG_ 1003 PersNo_D_Actl 1;
BA_ "U_P702_MY2024_Rx" SG_ 1003 PersNo_D_Actl 1;
BA_ "U_P708_MY2023_Rx" SG_ 1146 TrlrAidSwtch_D_RqDrv 1;
BA_ "U_P702_MY2024_Rx" SG_ 1146 TrlrAidSwtch_D_RqDrv 1;
BA_ "GenSigStartValue" SG_ 1146 TrlrAidCtl_U_RqDrv 4093;
BA_ "U_P708_MY2023_Rx" SG_ 1146 TrlrAidCtl_U_RqDrv 1;
BA_ "U_P702_MY2024_Rx" SG_ 1146 TrlrAidCtl_U_RqDrv 1;
BA_ "U_P708_MY2023_Rx" SG_ 778 PrkAidAcsyRear_D_RqDrv 1;
BA_ "U_V710_MY2023_Rx" SG_ 778 PrkAidAcsyRear_D_RqDrv 1;
BA_ "U_P702_MY2024_Rx" SG_ 778 PrkAidAcsyRear_D_RqDrv 1;
BA_ "U_P708_MY2023_Rx" SG_ 778 PrkAidAcsyFront_D_RqDrv 1;
BA_ "U_V710_MY2023_Rx" SG_ 778 PrkAidAcsyFront_D_RqDrv 1;
BA_ "U_P702_MY2024_Rx" SG_ 778 PrkAidAcsyFront_D_RqDrv 1;
BA_ "GenSigStartValue" SG_ 778 Cta_D_Rq 1;
BA_ "U_P708_MY2023_Rx" SG_ 778 Cta_D_Rq 1;
BA_ "U_V710_MY2023_Rx" SG_ 778 Cta_D_Rq 1;
BA_ "U_P702_MY2024_Rx" SG_ 778 Cta_D_Rq 1;
BA_ "U_P708_MY2023_Rx" SG_ 778 PrkAidRear_D_RqDrv 1;
BA_ "U_V710_MY2023_Rx" SG_ 778 PrkAidRear_D_RqDrv 1;
BA_ "U_P702_MY2024_Rx" SG_ 778 PrkAidRear_D_RqDrv 1;
BA_ "U_P708_MY2023_Rx" SG_ 778 PrkAidFront_D_RqDrv 1;
BA_ "U_V710_MY2023_Rx" SG_ 778 PrkAidFront_D_RqDrv 1;
BA_ "U_P702_MY2024_Rx" SG_ 778 PrkAidFront_D_RqDrv 1;
BA_ "GenSigStartValue" SG_ 778 Sod_D_Rq 2;
BA_ "U_P708_MY2023_Rx" SG_ 778 Sod_D_Rq 1;
BA_ "U_V710_MY2023_Rx" SG_ 778 Sod_D_Rq 1;
BA_ "U_P702_MY2024_Rx" SG_ 778 Sod_D_Rq 1;
BA_ "U_P708_MY2023_Rx" SG_ 778 ClrExitAsstEnbl_D_RqDrv 1;
BA_ "U_V710_MY2023_Rx" SG_ 778 ClrExitAsstEnbl_D_RqDrv 1;
BA_ "U_P702_MY2024_Rx" SG_ 778 ClrExitAsstEnbl_D_RqDrv 1;
BA_ "U_P708_MY2023_Tx" SG_ 1255 BalrRight4Threat_D_Stat 1;
BA_ "U_V710_MY2023_Tx" SG_ 1255 BalrRight4Threat_D_Stat 1;
BA_ "U_P702_MY2024_Tx" SG_ 1255 BalrRight4Threat_D_Stat 1;
BA_ "U_P708_MY2023_Tx" SG_ 1255 BalrRight4Prev3Y_L_Actl 1;
BA_ "U_V710_MY2023_Tx" SG_ 1255 BalrRight4Prev3Y_L_Actl 1;
BA_ "U_P702_MY2024_Tx" SG_ 1255 BalrRight4Prev3Y_L_Actl 1;
BA_ "U_P708_MY2023_Tx" SG_ 1255 BalrRight4Prev3X_L_Actl 1;
BA_ "U_V710_MY2023_Tx" SG_ 1255 BalrRight4Prev3X_L_Actl 1;
BA_ "U_P702_MY2024_Tx" SG_ 1255 BalrRight4Prev3X_L_Actl 1;
BA_ "U_P708_MY2023_Tx" SG_ 1255 BalrRight4Prev2Y_L_Actl 1;
BA_ "U_V710_MY2023_Tx" SG_ 1255 BalrRight4Prev2Y_L_Actl 1;
BA_ "U_P702_MY2024_Tx" SG_ 1255 BalrRight4Prev2Y_L_Actl 1;
BA_ "U_P708_MY2023_Tx" SG_ 1255 BalrRight4Prev2X_L_Actl 1;
BA_ "U_V710_MY2023_Tx" SG_ 1255 BalrRight4Prev2X_L_Actl 1;
BA_ "U_P702_MY2024_Tx" SG_ 1255 BalrRight4Prev2X_L_Actl 1;
BA_ "U_P708_MY2023_Tx" SG_ 1255 BalrRight4Prev1Y_L_Actl 1;
BA_ "U_V710_MY2023_Tx" SG_ 1255 BalrRight4Prev1Y_L_Actl 1;
BA_ "U_P702_MY2024_Tx" SG_ 1255 BalrRight4Prev1Y_L_Actl 1;
BA_ "U_P708_MY2023_Tx" SG_ 1255 BalrRight4Prev1X_L_Actl 1;
BA_ "U_V710_MY2023_Tx" SG_ 1255 BalrRight4Prev1X_L_Actl 1;
BA_ "U_P702_MY2024_Tx" SG_ 1255 BalrRight4Prev1X_L_Actl 1;
BA_ "U_P708_MY2023_Tx" SG_ 1255 BalrRight4Fast_B_Stat 1;
BA_ "U_V710_MY2023_Tx" SG_ 1255 BalrRight4Fast_B_Stat 1;
BA_ "U_P702_MY2024_Tx" SG_ 1255 BalrRight4Fast_B_Stat 1;
BA_ "U_P708_MY2023_Tx" SG_ 1255 BalrRight4Dsply_B_Stat 1;
BA_ "U_V710_MY2023_Tx" SG_ 1255 BalrRight4Dsply_B_Stat 1;
BA_ "U_P702_MY2024_Tx" SG_ 1255 BalrRight4Dsply_B_Stat 1;
BA_ "U_P708_MY2023_Tx" SG_ 1255 BalrRight4CurntY_L_Actl 1;
BA_ "U_V710_MY2023_Tx" SG_ 1255 BalrRight4CurntY_L_Actl 1;
BA_ "U_P702_MY2024_Tx" SG_ 1255 BalrRight4CurntY_L_Actl 1;
BA_ "U_P708_MY2023_Tx" SG_ 1255 BalrRight4CurntX_L_Actl 1;
BA_ "U_V710_MY2023_Tx" SG_ 1255 BalrRight4CurntX_L_Actl 1;
BA_ "U_P702_MY2024_Tx" SG_ 1255 BalrRight4CurntX_L_Actl 1;
BA_ "GenSigSendType" SG_ 1254 BalrRight3Threat_D_Stat 3;
BA_ "U_P708_MY2023_Tx" SG_ 1254 BalrRight3Threat_D_Stat 1;
BA_ "U_V710_MY2023_Tx" SG_ 1254 BalrRight3Threat_D_Stat 1;
BA_ "U_P702_MY2024_Tx" SG_ 1254 BalrRight3Threat_D_Stat 1;
BA_ "U_P708_MY2023_Tx" SG_ 1254 BalrRight3Prev3Y_L_Actl 1;
BA_ "U_V710_MY2023_Tx" SG_ 1254 BalrRight3Prev3Y_L_Actl 1;
BA_ "U_P702_MY2024_Tx" SG_ 1254 BalrRight3Prev3Y_L_Actl 1;
BA_ "U_P708_MY2023_Tx" SG_ 1254 BalrRight3Prev3X_L_Actl 1;
BA_ "U_V710_MY2023_Tx" SG_ 1254 BalrRight3Prev3X_L_Actl 1;
BA_ "U_P702_MY2024_Tx" SG_ 1254 BalrRight3Prev3X_L_Actl 1;
BA_ "U_P708_MY2023_Tx" SG_ 1254 BalrRight3Prev2Y_L_Actl 1;
BA_ "U_V710_MY2023_Tx" SG_ 1254 BalrRight3Prev2Y_L_Actl 1;
BA_ "U_P702_MY2024_Tx" SG_ 1254 BalrRight3Prev2Y_L_Actl 1;
BA_ "U_P708_MY2023_Tx" SG_ 1254 BalrRight3Prev2X_L_Actl 1;
BA_ "U_V710_MY2023_Tx" SG_ 1254 BalrRight3Prev2X_L_Actl 1;
BA_ "U_P702_MY2024_Tx" SG_ 1254 BalrRight3Prev2X_L_Actl 1;
BA_ "U_P708_MY2023_Tx" SG_ 1254 BalrRight3Prev1Y_L_Actl 1;
BA_ "U_V710_MY2023_Tx" SG_ 1254 BalrRight3Prev1Y_L_Actl 1;
BA_ "U_P702_MY2024_Tx" SG_ 1254 BalrRight3Prev1Y_L_Actl 1;
BA_ "U_P708_MY2023_Tx" SG_ 1254 BalrRight3Prev1X_L_Actl 1;
BA_ "U_V710_MY2023_Tx" SG_ 1254 BalrRight3Prev1X_L_Actl 1;
BA_ "U_P702_MY2024_Tx" SG_ 1254 BalrRight3Prev1X_L_Actl 1;
BA_ "GenSigSendType" SG_ 1254 BalrRight3Fast_B_Stat 3;
BA_ "U_P708_MY2023_Tx" SG_ 1254 BalrRight3Fast_B_Stat 1;
BA_ "U_V710_MY2023_Tx" SG_ 1254 BalrRight3Fast_B_Stat 1;
BA_ "U_P702_MY2024_Tx" SG_ 1254 BalrRight3Fast_B_Stat 1;
BA_ "GenSigSendType" SG_ 1254 BalrRight3Dsply_B_Stat 3;
BA_ "U_P708_MY2023_Tx" SG_ 1254 BalrRight3Dsply_B_Stat 1;
BA_ "U_V710_MY2023_Tx" SG_ 1254 BalrRight3Dsply_B_Stat 1;
BA_ "U_P702_MY2024_Tx" SG_ 1254 BalrRight3Dsply_B_Stat 1;
BA_ "U_P708_MY2023_Tx" SG_ 1254 BalrRight3CurntY_L_Actl 1;
BA_ "U_V710_MY2023_Tx" SG_ 1254 BalrRight3CurntY_L_Actl 1;
BA_ "U_P702_MY2024_Tx" SG_ 1254 BalrRight3CurntY_L_Actl 1;
BA_ "U_P708_MY2023_Tx" SG_ 1254 BalrRight3CurntX_L_Actl 1;
BA_ "U_V710_MY2023_Tx" SG_ 1254 BalrRight3CurntX_L_Actl 1;
BA_ "U_P702_MY2024_Tx" SG_ 1254 BalrRight3CurntX_L_Actl 1;
BA_ "U_P708_MY2023_Tx" SG_ 1253 BalrRight2Prev3Y_L_Actl 1;
BA_ "U_V710_MY2023_Tx" SG_ 1253 BalrRight2Prev3Y_L_Actl 1;
BA_ "U_P702_MY2024_Tx" SG_ 1253 BalrRight2Prev3Y_L_Actl 1;
BA_ "U_P708_MY2023_Tx" SG_ 1253 BalrRight2Prev3X_L_Actl 1;
BA_ "U_V710_MY2023_Tx" SG_ 1253 BalrRight2Prev3X_L_Actl 1;
BA_ "U_P702_MY2024_Tx" SG_ 1253 BalrRight2Prev3X_L_Actl 1;
BA_ "GenSigSendType" SG_ 1253 BalrRight2Threat_D_Stat 3;
BA_ "U_P708_MY2023_Tx" SG_ 1253 BalrRight2Threat_D_Stat 1;
BA_ "U_V710_MY2023_Tx" SG_ 1253 BalrRight2Threat_D_Stat 1;
BA_ "U_P702_MY2024_Tx" SG_ 1253 BalrRight2Threat_D_Stat 1;
BA_ "U_P708_MY2023_Tx" SG_ 1253 BalrRight2Prev2Y_L_Actl 1;
BA_ "U_V710_MY2023_Tx" SG_ 1253 BalrRight2Prev2Y_L_Actl 1;
BA_ "U_P702_MY2024_Tx" SG_ 1253 BalrRight2Prev2Y_L_Actl 1;
BA_ "U_P708_MY2023_Tx" SG_ 1253 BalrRight2Prev2X_L_Actl 1;
BA_ "U_V710_MY2023_Tx" SG_ 1253 BalrRight2Prev2X_L_Actl 1;
BA_ "U_P702_MY2024_Tx" SG_ 1253 BalrRight2Prev2X_L_Actl 1;
BA_ "U_P708_MY2023_Tx" SG_ 1253 BalrRight2Prev1Y_L_Actl 1;
BA_ "U_V710_MY2023_Tx" SG_ 1253 BalrRight2Prev1Y_L_Actl 1;
BA_ "U_P702_MY2024_Tx" SG_ 1253 BalrRight2Prev1Y_L_Actl 1;
BA_ "U_P708_MY2023_Tx" SG_ 1253 BalrRight2Prev1X_L_Actl 1;
BA_ "U_V710_MY2023_Tx" SG_ 1253 BalrRight2Prev1X_L_Actl 1;
BA_ "U_P702_MY2024_Tx" SG_ 1253 BalrRight2Prev1X_L_Actl 1;
BA_ "GenSigSendType" SG_ 1253 BalrRight2Fast_B_Stat 3;
BA_ "U_P708_MY2023_Tx" SG_ 1253 BalrRight2Fast_B_Stat 1;
BA_ "U_V710_MY2023_Tx" SG_ 1253 BalrRight2Fast_B_Stat 1;
BA_ "U_P702_MY2024_Tx" SG_ 1253 BalrRight2Fast_B_Stat 1;
BA_ "GenSigSendType" SG_ 1253 BalrRight2Dsply_B_Stat 3;
BA_ "U_P708_MY2023_Tx" SG_ 1253 BalrRight2Dsply_B_Stat 1;
BA_ "U_V710_MY2023_Tx" SG_ 1253 BalrRight2Dsply_B_Stat 1;
BA_ "U_P702_MY2024_Tx" SG_ 1253 BalrRight2Dsply_B_Stat 1;
BA_ "U_P708_MY2023_Tx" SG_ 1253 BalrRight2CurntY_L_Actl 1;
BA_ "U_V710_MY2023_Tx" SG_ 1253 BalrRight2CurntY_L_Actl 1;
BA_ "U_P702_MY2024_Tx" SG_ 1253 BalrRight2CurntY_L_Actl 1;
BA_ "U_P708_MY2023_Tx" SG_ 1253 BalrRight2CurntX_L_Actl 1;
BA_ "U_V710_MY2023_Tx" SG_ 1253 BalrRight2CurntX_L_Actl 1;
BA_ "U_P702_MY2024_Tx" SG_ 1253 BalrRight2CurntX_L_Actl 1;
BA_ "U_P708_MY2023_Tx" SG_ 1252 BalrRight1Prev3Y_L_Actl 1;
BA_ "U_V710_MY2023_Tx" SG_ 1252 BalrRight1Prev3Y_L_Actl 1;
BA_ "U_P702_MY2024_Tx" SG_ 1252 BalrRight1Prev3Y_L_Actl 1;
BA_ "U_P708_MY2023_Tx" SG_ 1252 BalrRight1Prev3X_L_Actl 1;
BA_ "U_V710_MY2023_Tx" SG_ 1252 BalrRight1Prev3X_L_Actl 1;
BA_ "U_P702_MY2024_Tx" SG_ 1252 BalrRight1Prev3X_L_Actl 1;
BA_ "GenSigSendType" SG_ 1252 BalrRight1Threat_D_Stat 3;
BA_ "U_P708_MY2023_Tx" SG_ 1252 BalrRight1Threat_D_Stat 1;
BA_ "U_V710_MY2023_Tx" SG_ 1252 BalrRight1Threat_D_Stat 1;
BA_ "U_P702_MY2024_Tx" SG_ 1252 BalrRight1Threat_D_Stat 1;
BA_ "U_P708_MY2023_Tx" SG_ 1252 BalrRight1Prev2Y_L_Actl 1;
BA_ "U_V710_MY2023_Tx" SG_ 1252 BalrRight1Prev2Y_L_Actl 1;
BA_ "U_P702_MY2024_Tx" SG_ 1252 BalrRight1Prev2Y_L_Actl 1;
BA_ "U_P708_MY2023_Tx" SG_ 1252 BalrRight1Prev2X_L_Actl 1;
BA_ "U_V710_MY2023_Tx" SG_ 1252 BalrRight1Prev2X_L_Actl 1;
BA_ "U_P702_MY2024_Tx" SG_ 1252 BalrRight1Prev2X_L_Actl 1;
BA_ "U_P708_MY2023_Tx" SG_ 1252 BalrRight1Prev1Y_L_Actl 1;
BA_ "U_V710_MY2023_Tx" SG_ 1252 BalrRight1Prev1Y_L_Actl 1;
BA_ "U_P702_MY2024_Tx" SG_ 1252 BalrRight1Prev1Y_L_Actl 1;
BA_ "U_P708_MY2023_Tx" SG_ 1252 BalrRight1Prev1X_L_Actl 1;
BA_ "U_V710_MY2023_Tx" SG_ 1252 BalrRight1Prev1X_L_Actl 1;
BA_ "U_P702_MY2024_Tx" SG_ 1252 BalrRight1Prev1X_L_Actl 1;
BA_ "GenSigSendType" SG_ 1252 BalrRight1Fast_B_Stat 3;
BA_ "U_P708_MY2023_Tx" SG_ 1252 BalrRight1Fast_B_Stat 1;
BA_ "U_V710_MY2023_Tx" SG_ 1252 BalrRight1Fast_B_Stat 1;
BA_ "U_P702_MY2024_Tx" SG_ 1252 BalrRight1Fast_B_Stat 1;
BA_ "GenSigSendType" SG_ 1252 BalrRight1Dsply_B_Stat 3;
BA_ "U_P708_MY2023_Tx" SG_ 1252 BalrRight1Dsply_B_Stat 1;
BA_ "U_V710_MY2023_Tx" SG_ 1252 BalrRight1Dsply_B_Stat 1;
BA_ "U_P702_MY2024_Tx" SG_ 1252 BalrRight1Dsply_B_Stat 1;
BA_ "U_P708_MY2023_Tx" SG_ 1252 BalrRight1CurntY_L_Actl 1;
BA_ "U_V710_MY2023_Tx" SG_ 1252 BalrRight1CurntY_L_Actl 1;
BA_ "U_P702_MY2024_Tx" SG_ 1252 BalrRight1CurntY_L_Actl 1;
BA_ "U_P708_MY2023_Tx" SG_ 1252 BalrRight1CurntX_L_Actl 1;
BA_ "U_V710_MY2023_Tx" SG_ 1252 BalrRight1CurntX_L_Actl 1;
BA_ "U_P702_MY2024_Tx" SG_ 1252 BalrRight1CurntX_L_Actl 1;
BA_ "U_P708_MY2023_Tx" SG_ 1251 BalrLeft4Threat_D_Stat 1;
BA_ "U_V710_MY2023_Tx" SG_ 1251 BalrLeft4Threat_D_Stat 1;
BA_ "U_P702_MY2024_Tx" SG_ 1251 BalrLeft4Threat_D_Stat 1;
BA_ "U_P708_MY2023_Tx" SG_ 1251 BalrLeft4Prev3Y_L_Actl 1;
BA_ "U_V710_MY2023_Tx" SG_ 1251 BalrLeft4Prev3Y_L_Actl 1;
BA_ "U_P702_MY2024_Tx" SG_ 1251 BalrLeft4Prev3Y_L_Actl 1;
BA_ "U_P708_MY2023_Tx" SG_ 1251 BalrLeft4Prev3X_L_Actl 1;
BA_ "U_V710_MY2023_Tx" SG_ 1251 BalrLeft4Prev3X_L_Actl 1;
BA_ "U_P702_MY2024_Tx" SG_ 1251 BalrLeft4Prev3X_L_Actl 1;
BA_ "U_P708_MY2023_Tx" SG_ 1251 BalrLeft4Prev2Y_L_Actl 1;
BA_ "U_V710_MY2023_Tx" SG_ 1251 BalrLeft4Prev2Y_L_Actl 1;
BA_ "U_P702_MY2024_Tx" SG_ 1251 BalrLeft4Prev2Y_L_Actl 1;
BA_ "U_P708_MY2023_Tx" SG_ 1251 BalrLeft4Prev2X_L_Actl 1;
BA_ "U_V710_MY2023_Tx" SG_ 1251 BalrLeft4Prev2X_L_Actl 1;
BA_ "U_P702_MY2024_Tx" SG_ 1251 BalrLeft4Prev2X_L_Actl 1;
BA_ "U_P708_MY2023_Tx" SG_ 1251 BalrLeft4Prev1Y_L_Actl 1;
BA_ "U_V710_MY2023_Tx" SG_ 1251 BalrLeft4Prev1Y_L_Actl 1;
BA_ "U_P702_MY2024_Tx" SG_ 1251 BalrLeft4Prev1Y_L_Actl 1;
BA_ "U_P708_MY2023_Tx" SG_ 1251 BalrLeft4Prev1X_L_Actl 1;
BA_ "U_V710_MY2023_Tx" SG_ 1251 BalrLeft4Prev1X_L_Actl 1;
BA_ "U_P702_MY2024_Tx" SG_ 1251 BalrLeft4Prev1X_L_Actl 1;
BA_ "U_P708_MY2023_Tx" SG_ 1251 BalrLeft4Fast_B_Stat 1;
BA_ "U_V710_MY2023_Tx" SG_ 1251 BalrLeft4Fast_B_Stat 1;
BA_ "U_P702_MY2024_Tx" SG_ 1251 BalrLeft4Fast_B_Stat 1;
BA_ "U_P708_MY2023_Tx" SG_ 1251 BalrLeft4Dsply_B_Stat 1;
BA_ "U_V710_MY2023_Tx" SG_ 1251 BalrLeft4Dsply_B_Stat 1;
BA_ "U_P702_MY2024_Tx" SG_ 1251 BalrLeft4Dsply_B_Stat 1;
BA_ "U_P708_MY2023_Tx" SG_ 1251 BalrLeft4CurntY_L_Actl 1;
BA_ "U_V710_MY2023_Tx" SG_ 1251 BalrLeft4CurntY_L_Actl 1;
BA_ "U_P702_MY2024_Tx" SG_ 1251 BalrLeft4CurntY_L_Actl 1;
BA_ "U_P708_MY2023_Tx" SG_ 1251 BalrLeft4CurntX_L_Actl 1;
BA_ "U_V710_MY2023_Tx" SG_ 1251 BalrLeft4CurntX_L_Actl 1;
BA_ "U_P702_MY2024_Tx" SG_ 1251 BalrLeft4CurntX_L_Actl 1;
BA_ "U_P708_MY2023_Tx" SG_ 1250 BalrLeft3Threat_D_Stat 1;
BA_ "U_V710_MY2023_Tx" SG_ 1250 BalrLeft3Threat_D_Stat 1;
BA_ "U_P702_MY2024_Tx" SG_ 1250 BalrLeft3Threat_D_Stat 1;
BA_ "U_P708_MY2023_Tx" SG_ 1250 BalrLeft3Prev3Y_L_Actl 1;
BA_ "U_V710_MY2023_Tx" SG_ 1250 BalrLeft3Prev3Y_L_Actl 1;
BA_ "U_P702_MY2024_Tx" SG_ 1250 BalrLeft3Prev3Y_L_Actl 1;
BA_ "U_P708_MY2023_Tx" SG_ 1250 BalrLeft3Prev3X_L_Actl 1;
BA_ "U_V710_MY2023_Tx" SG_ 1250 BalrLeft3Prev3X_L_Actl 1;
BA_ "U_P702_MY2024_Tx" SG_ 1250 BalrLeft3Prev3X_L_Actl 1;
BA_ "U_P708_MY2023_Tx" SG_ 1250 BalrLeft3Prev2Y_L_Actl 1;
BA_ "U_V710_MY2023_Tx" SG_ 1250 BalrLeft3Prev2Y_L_Actl 1;
BA_ "U_P702_MY2024_Tx" SG_ 1250 BalrLeft3Prev2Y_L_Actl 1;
BA_ "U_P708_MY2023_Tx" SG_ 1250 BalrLeft3Prev2X_L_Actl 1;
BA_ "U_V710_MY2023_Tx" SG_ 1250 BalrLeft3Prev2X_L_Actl 1;
BA_ "U_P702_MY2024_Tx" SG_ 1250 BalrLeft3Prev2X_L_Actl 1;
BA_ "U_P708_MY2023_Tx" SG_ 1250 BalrLeft3Prev1Y_L_Actl 1;
BA_ "U_V710_MY2023_Tx" SG_ 1250 BalrLeft3Prev1Y_L_Actl 1;
BA_ "U_P702_MY2024_Tx" SG_ 1250 BalrLeft3Prev1Y_L_Actl 1;
BA_ "U_P708_MY2023_Tx" SG_ 1250 BalrLeft3Prev1X_L_Actl 1;
BA_ "U_V710_MY2023_Tx" SG_ 1250 BalrLeft3Prev1X_L_Actl 1;
BA_ "U_P702_MY2024_Tx" SG_ 1250 BalrLeft3Prev1X_L_Actl 1;
BA_ "U_P708_MY2023_Tx" SG_ 1250 BalrLeft3Fast_B_Stat 1;
BA_ "U_V710_MY2023_Tx" SG_ 1250 BalrLeft3Fast_B_Stat 1;
BA_ "U_P702_MY2024_Tx" SG_ 1250 BalrLeft3Fast_B_Stat 1;
BA_ "U_P708_MY2023_Tx" SG_ 1250 BalrLeft3Dsply_B_Stat 1;
BA_ "U_V710_MY2023_Tx" SG_ 1250 BalrLeft3Dsply_B_Stat 1;
BA_ "U_P702_MY2024_Tx" SG_ 1250 BalrLeft3Dsply_B_Stat 1;
BA_ "U_P708_MY2023_Tx" SG_ 1250 BalrLeft3CurntY_L_Actl 1;
BA_ "U_V710_MY2023_Tx" SG_ 1250 BalrLeft3CurntY_L_Actl 1;
BA_ "U_P702_MY2024_Tx" SG_ 1250 BalrLeft3CurntY_L_Actl 1;
BA_ "U_P708_MY2023_Tx" SG_ 1250 BalrLeft3CurntX_L_Actl 1;
BA_ "U_V710_MY2023_Tx" SG_ 1250 BalrLeft3CurntX_L_Actl 1;
BA_ "U_P702_MY2024_Tx" SG_ 1250 BalrLeft3CurntX_L_Actl 1;
BA_ "U_P708_MY2023_Tx" SG_ 1249 BalrLeft2Prev3Y_L_Actl 1;
BA_ "U_V710_MY2023_Tx" SG_ 1249 BalrLeft2Prev3Y_L_Actl 1;
BA_ "U_P702_MY2024_Tx" SG_ 1249 BalrLeft2Prev3Y_L_Actl 1;
BA_ "U_P708_MY2023_Tx" SG_ 1249 BalrLeft2Prev3X_L_Actl 1;
BA_ "U_V710_MY2023_Tx" SG_ 1249 BalrLeft2Prev3X_L_Actl 1;
BA_ "U_P702_MY2024_Tx" SG_ 1249 BalrLeft2Prev3X_L_Actl 1;
BA_ "U_P708_MY2023_Tx" SG_ 1249 BalrLeft2Threat_D_Stat 1;
BA_ "U_V710_MY2023_Tx" SG_ 1249 BalrLeft2Threat_D_Stat 1;
BA_ "U_P702_MY2024_Tx" SG_ 1249 BalrLeft2Threat_D_Stat 1;
BA_ "U_P708_MY2023_Tx" SG_ 1249 BalrLeft2Prev2Y_L_Actl 1;
BA_ "U_V710_MY2023_Tx" SG_ 1249 BalrLeft2Prev2Y_L_Actl 1;
BA_ "U_P702_MY2024_Tx" SG_ 1249 BalrLeft2Prev2Y_L_Actl 1;
BA_ "U_P708_MY2023_Tx" SG_ 1249 BalrLeft2Prev2X_L_Actl 1;
BA_ "U_V710_MY2023_Tx" SG_ 1249 BalrLeft2Prev2X_L_Actl 1;
BA_ "U_P702_MY2024_Tx" SG_ 1249 BalrLeft2Prev2X_L_Actl 1;
BA_ "U_P708_MY2023_Tx" SG_ 1249 BalrLeft2Prev1Y_L_Actl 1;
BA_ "U_V710_MY2023_Tx" SG_ 1249 BalrLeft2Prev1Y_L_Actl 1;
BA_ "U_P702_MY2024_Tx" SG_ 1249 BalrLeft2Prev1Y_L_Actl 1;
BA_ "U_P708_MY2023_Tx" SG_ 1249 BalrLeft2Prev1X_L_Actl 1;
BA_ "U_V710_MY2023_Tx" SG_ 1249 BalrLeft2Prev1X_L_Actl 1;
BA_ "U_P702_MY2024_Tx" SG_ 1249 BalrLeft2Prev1X_L_Actl 1;
BA_ "U_P708_MY2023_Tx" SG_ 1249 BalrLeft2Fast_B_Stat 1;
BA_ "U_V710_MY2023_Tx" SG_ 1249 BalrLeft2Fast_B_Stat 1;
BA_ "U_P702_MY2024_Tx" SG_ 1249 BalrLeft2Fast_B_Stat 1;
BA_ "U_P708_MY2023_Tx" SG_ 1249 BalrLeft2Dsply_B_Stat 1;
BA_ "U_V710_MY2023_Tx" SG_ 1249 BalrLeft2Dsply_B_Stat 1;
BA_ "U_P702_MY2024_Tx" SG_ 1249 BalrLeft2Dsply_B_Stat 1;
BA_ "U_P708_MY2023_Tx" SG_ 1249 BalrLeft2CurntY_L_Actl 1;
BA_ "U_V710_MY2023_Tx" SG_ 1249 BalrLeft2CurntY_L_Actl 1;
BA_ "U_P702_MY2024_Tx" SG_ 1249 BalrLeft2CurntY_L_Actl 1;
BA_ "U_P708_MY2023_Tx" SG_ 1249 BalrLeft2CurntX_L_Actl 1;
BA_ "U_V710_MY2023_Tx" SG_ 1249 BalrLeft2CurntX_L_Actl 1;
BA_ "U_P702_MY2024_Tx" SG_ 1249 BalrLeft2CurntX_L_Actl 1;
BA_ "GenSigSendType" SG_ 1248 BalrLeft1Threat_D_Stat 3;
BA_ "U_P708_MY2023_Tx" SG_ 1248 BalrLeft1Threat_D_Stat 1;
BA_ "U_V710_MY2023_Tx" SG_ 1248 BalrLeft1Threat_D_Stat 1;
BA_ "U_P702_MY2024_Tx" SG_ 1248 BalrLeft1Threat_D_Stat 1;
BA_ "U_P708_MY2023_Tx" SG_ 1248 BalrLeft1Prev3Y_L_Actl 1;
BA_ "U_V710_MY2023_Tx" SG_ 1248 BalrLeft1Prev3Y_L_Actl 1;
BA_ "U_P702_MY2024_Tx" SG_ 1248 BalrLeft1Prev3Y_L_Actl 1;
BA_ "U_P708_MY2023_Tx" SG_ 1248 BalrLeft1Prev3X_L_Actl 1;
BA_ "U_V710_MY2023_Tx" SG_ 1248 BalrLeft1Prev3X_L_Actl 1;
BA_ "U_P702_MY2024_Tx" SG_ 1248 BalrLeft1Prev3X_L_Actl 1;
BA_ "U_P708_MY2023_Tx" SG_ 1248 BalrLeft1Prev2Y_L_Actl 1;
BA_ "U_V710_MY2023_Tx" SG_ 1248 BalrLeft1Prev2Y_L_Actl 1;
BA_ "U_P702_MY2024_Tx" SG_ 1248 BalrLeft1Prev2Y_L_Actl 1;
BA_ "U_P708_MY2023_Tx" SG_ 1248 BalrLeft1Prev2X_L_Actl 1;
BA_ "U_V710_MY2023_Tx" SG_ 1248 BalrLeft1Prev2X_L_Actl 1;
BA_ "U_P702_MY2024_Tx" SG_ 1248 BalrLeft1Prev2X_L_Actl 1;
BA_ "U_P708_MY2023_Tx" SG_ 1248 BalrLeft1Prev1Y_L_Actl 1;
BA_ "U_V710_MY2023_Tx" SG_ 1248 BalrLeft1Prev1Y_L_Actl 1;
BA_ "U_P702_MY2024_Tx" SG_ 1248 BalrLeft1Prev1Y_L_Actl 1;
BA_ "U_P708_MY2023_Tx" SG_ 1248 BalrLeft1Prev1X_L_Actl 1;
BA_ "U_V710_MY2023_Tx" SG_ 1248 BalrLeft1Prev1X_L_Actl 1;
BA_ "U_P702_MY2024_Tx" SG_ 1248 BalrLeft1Prev1X_L_Actl 1;
BA_ "GenSigSendType" SG_ 1248 BalrLeft1Fast_B_Stat 3;
BA_ "U_P708_MY2023_Tx" SG_ 1248 BalrLeft1Fast_B_Stat 1;
BA_ "U_V710_MY2023_Tx" SG_ 1248 BalrLeft1Fast_B_Stat 1;
BA_ "U_P702_MY2024_Tx" SG_ 1248 BalrLeft1Fast_B_Stat 1;
BA_ "GenSigSendType" SG_ 1248 BalrLeft1Dsply_B_Stat 3;
BA_ "U_P708_MY2023_Tx" SG_ 1248 BalrLeft1Dsply_B_Stat 1;
BA_ "U_V710_MY2023_Tx" SG_ 1248 BalrLeft1Dsply_B_Stat 1;
BA_ "U_P702_MY2024_Tx" SG_ 1248 BalrLeft1Dsply_B_Stat 1;
BA_ "U_P708_MY2023_Tx" SG_ 1248 BalrLeft1CurntY_L_Actl 1;
BA_ "U_V710_MY2023_Tx" SG_ 1248 BalrLeft1CurntY_L_Actl 1;
BA_ "U_P702_MY2024_Tx" SG_ 1248 BalrLeft1CurntY_L_Actl 1;
BA_ "U_P708_MY2023_Tx" SG_ 1248 BalrLeft1CurntX_L_Actl 1;
BA_ "U_V710_MY2023_Tx" SG_ 1248 BalrLeft1CurntX_L_Actl 1;
BA_ "U_P702_MY2024_Tx" SG_ 1248 BalrLeft1CurntX_L_Actl 1;
BA_ "GenSigSendType" SG_ 2610988248 PARSEDPhysGWM_ECGtoIPMA 3;
BA_ "U_P708_MY2023_Rx" SG_ 2610988248 PARSEDPhysGWM_ECGtoIPMA 1;
BA_ "U_V710_MY2023_Rx" SG_ 2610988248 PARSEDPhysGWM_ECGtoIPMA 1;
BA_ "U_P702_MY2024_Rx" SG_ 2610988248 PARSEDPhysGWM_ECGtoIPMA 1;
BA_ "ECGUsedTxSignal" SG_ 2610988248 PARSEDPhysGWM_ECGtoIPMA 1;
BA_ "U_P708_MY2023_Tx" SG_ 2610988248 PARSEDPhysGWM_ECGtoIPMA 1;
BA_ "U_CDX74X_MY2024_Tx" SG_ 2610988248 PARSEDPhysGWM_ECGtoIPMA 1;
BA_ "U_V710_MY2023_Tx" SG_ 2610988248 PARSEDPhysGWM_ECGtoIPMA 1;
BA_ "U_P702_MY2024_Tx" SG_ 2610988248 PARSEDPhysGWM_ECGtoIPMA 1;
BA_ "GenSigSendType" SG_ 1105 ClrExitAsstMsgTxt2_D_Rq 3;
BA_ "U_P708_MY2023_Tx" SG_ 1105 ClrExitAsstMsgTxt2_D_Rq 1;
BA_ "U_V710_MY2023_Tx" SG_ 1105 ClrExitAsstMsgTxt2_D_Rq 1;
BA_ "U_P702_MY2024_Tx" SG_ 1105 ClrExitAsstMsgTxt2_D_Rq 1;
BA_ "GenSigSendType" SG_ 1105 ClrExitAsstActv_B_Rq 3;
BA_ "U_P708_MY2023_Tx" SG_ 1105 ClrExitAsstActv_B_Rq 1;
BA_ "U_V710_MY2023_Tx" SG_ 1105 ClrExitAsstActv_B_Rq 1;
BA_ "U_P702_MY2024_Tx" SG_ 1105 ClrExitAsstActv_B_Rq 1;
BA_ "GenSigSendType" SG_ 1105 TrlrRvrseMsgTxt_D2_Rq 3;
BA_ "U_P708_MY2023_Rx" SG_ 1105 TrlrRvrseMsgTxt_D2_Rq 1;
BA_ "U_P702_MY2024_Rx" SG_ 1105 TrlrRvrseMsgTxt_D2_Rq 1;
BA_ "U_P708_MY2023_Tx" SG_ 1105 TrlrRvrseMsgTxt_D2_Rq 1;
BA_ "U_V710_MY2023_Tx" SG_ 1105 TrlrRvrseMsgTxt_D2_Rq 1;
BA_ "U_P702_MY2024_Tx" SG_ 1105 TrlrRvrseMsgTxt_D2_Rq 1;
BA_ "GenSigSendType" SG_ 1105 TrlrRvrseEnbl_D2_Stat 3;
BA_ "U_P708_MY2023_Rx" SG_ 1105 TrlrRvrseEnbl_D2_Stat 1;
BA_ "U_P702_MY2024_Rx" SG_ 1105 TrlrRvrseEnbl_D2_Stat 1;
BA_ "U_P708_MY2023_Tx" SG_ 1105 TrlrRvrseEnbl_D2_Stat 1;
BA_ "U_V710_MY2023_Tx" SG_ 1105 TrlrRvrseEnbl_D2_Stat 1;
BA_ "U_P702_MY2024_Tx" SG_ 1105 TrlrRvrseEnbl_D2_Stat 1;
BA_ "GenSigSendType" SG_ 1105 RbaMsg_D_Rq 3;
BA_ "U_P708_MY2023_Tx" SG_ 1105 RbaMsg_D_Rq 1;
BA_ "U_V710_MY2023_Tx" SG_ 1105 RbaMsg_D_Rq 1;
BA_ "U_P702_MY2024_Tx" SG_ 1105 RbaMsg_D_Rq 1;
BA_ "WakeupSignal" SG_ 1105 BrkDecel_B_RqRba 1;
BA_ "GenSigSendType" SG_ 1105 BrkDecel_B_RqRba 3;
BA_ "U_P708_MY2023_Tx" SG_ 1105 BrkDecel_B_RqRba 1;
BA_ "U_V710_MY2023_Tx" SG_ 1105 BrkDecel_B_RqRba 1;
BA_ "U_P702_MY2024_Tx" SG_ 1105 BrkDecel_B_RqRba 1;
BA_ "WakeupSignal" SG_ 1105 BrkEnbl_B_RqRba 1;
BA_ "GenSigSendType" SG_ 1105 BrkEnbl_B_RqRba 3;
BA_ "U_P708_MY2023_Tx" SG_ 1105 BrkEnbl_B_RqRba 1;
BA_ "U_V710_MY2023_Tx" SG_ 1105 BrkEnbl_B_RqRba 1;
BA_ "U_P702_MY2024_Tx" SG_ 1105 BrkEnbl_B_RqRba 1;
BA_ "GenSigStartValue" SG_ 1105 Rba_D_Stat 1;
BA_ "GenSigSendType" SG_ 1105 Rba_D_Stat 3;
BA_ "U_P708_MY2023_Tx" SG_ 1105 Rba_D_Stat 1;
BA_ "U_V710_MY2023_Tx" SG_ 1105 Rba_D_Stat 1;
BA_ "U_P702_MY2024_Tx" SG_ 1105 Rba_D_Stat 1;
BA_ "GenSigSendType" SG_ 1105 RbaAlrt_D_Dsply 3;
BA_ "U_P708_MY2023_Tx" SG_ 1105 RbaAlrt_D_Dsply 1;
BA_ "U_V710_MY2023_Tx" SG_ 1105 RbaAlrt_D_Dsply 1;
BA_ "U_P702_MY2024_Tx" SG_ 1105 RbaAlrt_D_Dsply 1;
BA_ "GenSigSendType" SG_ 1105 RbaMnu_D_Rq 3;
BA_ "U_P708_MY2023_Tx" SG_ 1105 RbaMnu_D_Rq 1;
BA_ "U_V710_MY2023_Tx" SG_ 1105 RbaMnu_D_Rq 1;
BA_ "U_P702_MY2024_Tx" SG_ 1105 RbaMnu_D_Rq 1;
BA_ "GenSigSendType" SG_ 1105 CamraFrntStat_D_Stat 3;
BA_ "U_P708_MY2023_Tx" SG_ 1105 CamraFrntStat_D_Stat 1;
BA_ "U_V710_MY2023_Tx" SG_ 1105 CamraFrntStat_D_Stat 1;
BA_ "U_P702_MY2024_Tx" SG_ 1105 CamraFrntStat_D_Stat 1;
BA_ "GenSigSendType" SG_ 1105 TrlrHitchLamp_D_Rq2 3;
BA_ "U_P708_MY2023_Tx" SG_ 1105 TrlrHitchLamp_D_Rq2 1;
BA_ "U_V710_MY2023_Tx" SG_ 1105 TrlrHitchLamp_D_Rq2 1;
BA_ "U_P702_MY2024_Tx" SG_ 1105 TrlrHitchLamp_D_Rq2 1;
BA_ "GenSigSendType" SG_ 1105 TrlrAidSwtchLamp_B_Rq 3;
BA_ "U_P708_MY2023_Tx" SG_ 1105 TrlrAidSwtchLamp_B_Rq 1;
BA_ "U_V710_MY2023_Tx" SG_ 1105 TrlrAidSwtchLamp_B_Rq 1;
BA_ "U_P702_MY2024_Tx" SG_ 1105 TrlrAidSwtchLamp_B_Rq 1;
BA_ "GenSigSendType" SG_ 1105 TrlrAidEnbl_D_RqAdas 3;
BA_ "U_P708_MY2023_Rx" SG_ 1105 TrlrAidEnbl_D_RqAdas 1;
BA_ "U_P702_MY2024_Rx" SG_ 1105 TrlrAidEnbl_D_RqAdas 1;
BA_ "U_P708_MY2023_Tx" SG_ 1105 TrlrAidEnbl_D_RqAdas 1;
BA_ "U_V710_MY2023_Tx" SG_ 1105 TrlrAidEnbl_D_RqAdas 1;
BA_ "U_P702_MY2024_Tx" SG_ 1105 TrlrAidEnbl_D_RqAdas 1;
BA_ "GenSigSendType" SG_ 1105 TrlrHitchMsgTxt_D_Rq 3;
BA_ "U_P708_MY2023_Tx" SG_ 1105 TrlrHitchMsgTxt_D_Rq 1;
BA_ "U_V710_MY2023_Tx" SG_ 1105 TrlrHitchMsgTxt_D_Rq 1;
BA_ "U_P702_MY2024_Tx" SG_ 1105 TrlrHitchMsgTxt_D_Rq 1;
BA_ "GenSigSendType" SG_ 1105 TrlrHitchIcon_D_Rq 3;
BA_ "U_P708_MY2023_Tx" SG_ 1105 TrlrHitchIcon_D_Rq 1;
BA_ "U_V710_MY2023_Tx" SG_ 1105 TrlrHitchIcon_D_Rq 1;
BA_ "U_P702_MY2024_Tx" SG_ 1105 TrlrHitchIcon_D_Rq 1;
BA_ "GenSigSendType" SG_ 1105 TrlrHitchChime_D_Rq 3;
BA_ "U_P708_MY2023_Tx" SG_ 1105 TrlrHitchChime_D_Rq 1;
BA_ "U_V710_MY2023_Tx" SG_ 1105 TrlrHitchChime_D_Rq 1;
BA_ "U_P702_MY2024_Tx" SG_ 1105 TrlrHitchChime_D_Rq 1;
BA_ "GenSigSendType" SG_ 1105 CamraFrntOffRd_B_Stat 3;
BA_ "U_P708_MY2023_Tx" SG_ 1105 CamraFrntOffRd_B_Stat 1;
BA_ "U_V710_MY2023_Tx" SG_ 1105 CamraFrntOffRd_B_Stat 1;
BA_ "U_P702_MY2024_Tx" SG_ 1105 CamraFrntOffRd_B_Stat 1;
BA_ "MetaData" SG_ 1111 TrlrYawWActl_D_Qf 1;
BA_ "GenSigStartValue" SG_ 1111 TrlrYawWActl_D_Qf 1;
BA_ "U_P708_MY2023_Rx" SG_ 1111 TrlrYawWActl_D_Qf 1;
BA_ "U_V710_MY2023_Rx" SG_ 1111 TrlrYawWActl_D_Qf 1;
BA_ "U_P702_MY2024_Rx" SG_ 1111 TrlrYawWActl_D_Qf 1;
BA_ "GenSigStartValue" SG_ 1111 TrlrYaw_W_Actl 65534;
BA_ "U_P708_MY2023_Rx" SG_ 1111 TrlrYaw_W_Actl 1;
BA_ "U_V710_MY2023_Rx" SG_ 1111 TrlrYaw_W_Actl 1;
BA_ "U_P702_MY2024_Rx" SG_ 1111 TrlrYaw_W_Actl 1;
BA_ "GenSigStartValue" SG_ 1111 TrlrHitYaw_AnRate_Actl 4093;
BA_ "U_P708_MY2023_Rx" SG_ 1111 TrlrHitYaw_AnRate_Actl 1;
BA_ "U_V710_MY2023_Rx" SG_ 1111 TrlrHitYaw_AnRate_Actl 1;
BA_ "U_P702_MY2024_Rx" SG_ 1111 TrlrHitYaw_AnRate_Actl 1;
BA_ "U_P708_MY2023_Rx" SG_ 1111 TrlrHitchYaw_D_Stat 1;
BA_ "U_V710_MY2023_Rx" SG_ 1111 TrlrHitchYaw_D_Stat 1;
BA_ "U_P702_MY2024_Rx" SG_ 1111 TrlrHitchYaw_D_Stat 1;
BA_ "GenSigStartValue" SG_ 1111 TrlrHitchYaw_An_Actl 4093;
BA_ "U_P708_MY2023_Rx" SG_ 1111 TrlrHitchYaw_An_Actl 1;
BA_ "U_V710_MY2023_Rx" SG_ 1111 TrlrHitchYaw_An_Actl 1;
BA_ "U_P702_MY2024_Rx" SG_ 1111 TrlrHitchYaw_An_Actl 1;
BA_ "U_P708_MY2023_Rx" SG_ 1106 TrlrSnsId_No_Actl 1;
BA_ "U_V710_MY2023_Rx" SG_ 1106 TrlrSnsId_No_Actl 1;
BA_ "U_P702_MY2024_Rx" SG_ 1106 TrlrSnsId_No_Actl 1;
BA_ "WakeupSignal" SG_ 909 HazrdLght_B_Stat 1;
BA_ "WakeupSignal" SG_ 909 IgnPsswrdDsply_B_Rq 1;
BA_ "WakeupSignal" SG_ 909 ElPwPoint_D_Rq 1;
BA_ "WakeupSignal" SG_ 909 PrsnlDevcChrgEnbl_B_Rq 1;
BA_ "WakeupSignal" SG_ 909 immoMsgTxt_D_Rq 1;
BA_ "MetaData" SG_ 909 KeyMykeyTot_No_Cnt 1;
BA_ "MetaData" SG_ 909 KeyAdmnTot_No_Cnt 1;
BA_ "GenSigStartValue" SG_ 909 WiprFront_D_Stat2 15;
BA_ "GenSigStartValue" SG_ 909 HeadLghtHiPrmsn_D_Stat 3;
BA_ "U_P708_MY2023_Rx" SG_ 909 HeadLghtHiPrmsn_D_Stat 1;
BA_ "U_V710_MY2023_Rx" SG_ 909 HeadLghtHiPrmsn_D_Stat 1;
BA_ "U_P702_MY2024_Rx" SG_ 909 HeadLghtHiPrmsn_D_Stat 1;
BA_ "U_CDX74X_MY2024_Rx" SG_ 909 HeadLghtHiPrmsn_D_Stat 1;
BA_ "U_P708_MY2023_Rx" SG_ 963 PudLampPsngr_D_Rq 1;
BA_ "U_P702_MY2024_Rx" SG_ 963 ImpactEvntFdbck_D_Stat 1;
BA_ "U_CDX707_MY2023_Rx" SG_ 963 ImpactEvntFdbck_D_Stat 1;
BA_ "WakeupSignal" SG_ 963 ImpactEvntFdbck_D_Stat 1;
BA_ "WakeupSignal" SG_ 963 KeyInIgnWarn_B_Cmd 1;
BA_ "WakeupSignal" SG_ 963 HomeSafeLtChime_B_Rq 1;
BA_ "WakeupSignal" SG_ 963 Headlamp_On_Wrning_Cmd 1;
BA_ "WakeupSignal" SG_ 963 PrkLght_D_Stat 1;
BA_ "WakeupSignal" SG_ 963 PerimeterAlarmChimeRq 1;
BA_ "U_P708_MY2023_Rx" SG_ 963 CrnrLghtRight_Pc_Rq 1;
BA_ "U_CDX74X_MY2024_Rx" SG_ 963 CrnrLghtRight_Pc_Rq 1;
BA_ "U_V710_MY2023_Rx" SG_ 963 CrnrLghtRight_Pc_Rq 1;
BA_ "U_P702_MY2024_Rx" SG_ 963 CrnrLghtRight_Pc_Rq 1;
BA_ "U_P708_MY2023_Rx" SG_ 963 CrnrLghtLeft_Pc_Rq 1;
BA_ "U_CDX74X_MY2024_Rx" SG_ 963 CrnrLghtLeft_Pc_Rq 1;
BA_ "U_V710_MY2023_Rx" SG_ 963 CrnrLghtLeft_Pc_Rq 1;
BA_ "U_P702_MY2024_Rx" SG_ 963 CrnrLghtLeft_Pc_Rq 1;
BA_ "U_P708_MY2023_Rx" SG_ 963 HeadLghtHiFdbck_D_Stat 1;
BA_ "U_P702_MY2024_Rx" SG_ 963 HeadLghtHiFdbck_D_Stat 1;
BA_ "U_P708_MY2023_Rx" SG_ 963 PudLampDrv_D_Rq 1;
BA_ "U_P702_MY2024_Rx" SG_ 963 PudLampDrv_D_Rq 1;
BA_ "WakeupSignal" SG_ 963 StopLghtOn_B_Stat 1;
BA_ "U_P708_MY2023_Rx" SG_ 963 StopLghtOn_B_Stat 1;
BA_ "U_CDX74X_MY2024_Rx" SG_ 963 StopLghtOn_B_Stat 1;
BA_ "U_V710_MY2023_Rx" SG_ 963 StopLghtOn_B_Stat 1;
BA_ "U_P702_MY2024_Rx" SG_ 963 StopLghtOn_B_Stat 1;
BA_ "WakeupSignal" SG_ 963 HeadLghtSwtch_D_Stat 1;
BA_ "GenSigStartValue" SG_ 963 HeadLghtSwtch_D_Stat 2;
BA_ "U_P708_MY2023_Rx" SG_ 963 HeadLghtSwtch_D_Stat 1;
BA_ "U_V710_MY2023_Rx" SG_ 963 HeadLghtSwtch_D_Stat 1;
BA_ "U_P702_MY2024_Rx" SG_ 963 HeadLghtSwtch_D_Stat 1;
BA_ "U_CDX74X_MY2024_Rx" SG_ 963 HeadLghtSwtch_D_Stat 1;
BA_ "GenSigStartValue" SG_ 963 HeadLampLoFrOn_B_Stat 1;
BA_ "U_P708_MY2023_Rx" SG_ 963 HeadLampLoFrOn_B_Stat 1;
BA_ "U_V710_MY2023_Rx" SG_ 963 HeadLampLoFrOn_B_Stat 1;
BA_ "U_P702_MY2024_Rx" SG_ 963 HeadLampLoFrOn_B_Stat 1;
BA_ "U_CDX74X_MY2024_Rx" SG_ 963 HeadLampLoFrOn_B_Stat 1;
BA_ "GenSigStartValue" SG_ 963 HeadLampLoFlOn_B_Stat 1;
BA_ "U_P708_MY2023_Rx" SG_ 963 HeadLampLoFlOn_B_Stat 1;
BA_ "U_V710_MY2023_Rx" SG_ 963 HeadLampLoFlOn_B_Stat 1;
BA_ "U_P702_MY2024_Rx" SG_ 963 HeadLampLoFlOn_B_Stat 1;
BA_ "U_CDX74X_MY2024_Rx" SG_ 963 HeadLampLoFlOn_B_Stat 1;
BA_ "GenSigStartValue" SG_ 963 HeadLampLoActv_B_Stat 1;
BA_ "U_P708_MY2023_Rx" SG_ 963 HeadLampLoActv_B_Stat 1;
BA_ "U_V710_MY2023_Rx" SG_ 963 HeadLampLoActv_B_Stat 1;
BA_ "U_P702_MY2024_Rx" SG_ 963 HeadLampLoActv_B_Stat 1;
BA_ "U_CDX74X_MY2024_Rx" SG_ 963 HeadLampLoActv_B_Stat 1;
BA_ "WakeupSignal" SG_ 963 HeadLghtHiOn_B_Stat 1;
BA_ "U_P708_MY2023_Rx" SG_ 963 HeadLghtHiOn_B_Stat 1;
BA_ "U_V710_MY2023_Rx" SG_ 963 HeadLghtHiOn_B_Stat 1;
BA_ "U_P702_MY2024_Rx" SG_ 963 HeadLghtHiOn_B_Stat 1;
BA_ "U_CDX74X_MY2024_Rx" SG_ 963 HeadLghtHiOn_B_Stat 1;
BA_ "WakeupSignal" SG_ 963 Perimeter_Alarm_Status 1;
BA_ "U_P708_MY2023_Rx" SG_ 963 Perimeter_Alarm_Status 1;
BA_ "U_V710_MY2023_Rx" SG_ 963 Perimeter_Alarm_Status 1;
BA_ "U_P702_MY2024_Rx" SG_ 963 Perimeter_Alarm_Status 1;
BA_ "WakeupSignal" SG_ 963 Courtesy_BSave_Stat 1;
BA_ "GenSigStartValue" SG_ 963 Courtesy_BSave_Stat 1;
BA_ "U_P708_MY2023_Rx" SG_ 963 Courtesy_BSave_Stat 1;
BA_ "U_P702_MY2024_Rx" SG_ 963 Courtesy_BSave_Stat 1;
BA_ "WakeupSignal" SG_ 963 WndwGlbl_D_Cmd 1;
BA_ "U_P708_MY2023_Rx" SG_ 963 WndwGlbl_D_Cmd 1;
BA_ "U_P702_MY2024_Rx" SG_ 963 WndwGlbl_D_Cmd 1;
BA_ "WakeupSignal" SG_ 963 PudLamp_D_Rq 1;
BA_ "U_P708_MY2023_Rx" SG_ 963 PudLamp_D_Rq 1;
BA_ "U_P702_MY2024_Rx" SG_ 963 PudLamp_D_Rq 1;
BA_ "U_P708_MY2023_Rx" SG_ 963 DayRnngLampOn_B_Stat 1;
BA_ "U_CDX74X_MY2024_Rx" SG_ 963 DayRnngLampOn_B_Stat 1;
BA_ "U_V710_MY2023_Rx" SG_ 963 DayRnngLampOn_B_Stat 1;
BA_ "U_P702_MY2024_Rx" SG_ 963 DayRnngLampOn_B_Stat 1;
BA_ "WakeupSignal" SG_ 578 ReFuelSwtchStat_D_Actl 1;
BA_ "GenSigStartValue" SG_ 578 BattULo_U_Actl 255;
BA_ "U_P708_MY2023_Rx" SG_ 578 BattULo_U_Actl 1;
BA_ "U_V710_MY2023_Rx" SG_ 578 BattULo_U_Actl 1;
BA_ "U_P702_MY2024_Rx" SG_ 578 BattULo_U_Actl 1;
BA_ "U_V713N_MY2022_Rx" SG_ 578 BattULo_U_Actl 1;
BA_ "WakeupSignal" SG_ 578 PrkLckCtlMsgTxt_D_Rq 1;
BA_ "WakeupSignal" SG_ 578 PrkLckCtlAvail_T_Stat 1;
BA_ "U_P708_MY2023_Rx" SG_ 578 EngOff_T_Actl 1;
BA_ "U_V710_MY2023_Rx" SG_ 578 EngOff_T_Actl 1;
BA_ "U_P702_MY2024_Rx" SG_ 578 EngOff_T_Actl 1;
BA_ "GenSigStartValue" SG_ 578 BattULo_I_Actl 16383;
BA_ "GenSigSendType" SG_ 1892 TesterPhysicalReqCCM 3;
BA_ "U_P708_MY2023_Rx" SG_ 1892 TesterPhysicalReqCCM 1;
BA_ "U_V710_MY2023_Rx" SG_ 1892 TesterPhysicalReqCCM 1;
BA_ "U_P702_MY2024_Rx" SG_ 1892 TesterPhysicalReqCCM 1;
BA_ "GenSigSendType" SG_ 1798 TesterPhysicalReqIPMA 3;
BA_ "U_P708_MY2023_Rx" SG_ 1798 TesterPhysicalReqIPMA 1;
BA_ "U_V710_MY2023_Rx" SG_ 1798 TesterPhysicalReqIPMA 1;
BA_ "U_P702_MY2024_Rx" SG_ 1798 TesterPhysicalReqIPMA 1;
BA_ "GenSigSendType" SG_ 1900 TesterPhysicalResCCM 3;
BA_ "U_P708_MY2023_Tx" SG_ 1900 TesterPhysicalResCCM 1;
BA_ "U_V710_MY2023_Tx" SG_ 1900 TesterPhysicalResCCM 1;
BA_ "U_P702_MY2024_Tx" SG_ 1900 TesterPhysicalResCCM 1;
BA_ "GenSigSendType" SG_ 1806 TesterPhysicalResIPMA 3;
BA_ "U_P708_MY2023_Tx" SG_ 1806 TesterPhysicalResIPMA 1;
BA_ "U_V710_MY2023_Tx" SG_ 1806 TesterPhysicalResIPMA 1;
BA_ "U_P702_MY2024_Tx" SG_ 1806 TesterPhysicalResIPMA 1;
BA_ "U_P708_MY2023_Rx" SG_ 1010 LightRng_L_Max 1;
BA_ "U_CDX74X_MY2024_Rx" SG_ 1010 LightRng_L_Max 1;
BA_ "U_V710_MY2023_Rx" SG_ 1010 LightRng_L_Max 1;
BA_ "U_P702_MY2024_Rx" SG_ 1010 LightRng_L_Max 1;
BA_ "U_P708_MY2023_Tx" SG_ 1010 LightRng_L_Max 1;
BA_ "U_V710_MY2023_Tx" SG_ 1010 LightRng_L_Max 1;
BA_ "U_P702_MY2024_Tx" SG_ 1010 LightRng_L_Max 1;
BA_ "U_P708_MY2023_Rx" SG_ 1010 LightPathOffst_L_Actl 1;
BA_ "U_CDX74X_MY2024_Rx" SG_ 1010 LightPathOffst_L_Actl 1;
BA_ "U_V710_MY2023_Rx" SG_ 1010 LightPathOffst_L_Actl 1;
BA_ "U_P702_MY2024_Rx" SG_ 1010 LightPathOffst_L_Actl 1;
BA_ "U_P708_MY2023_Tx" SG_ 1010 LightPathOffst_L_Actl 1;
BA_ "U_V710_MY2023_Tx" SG_ 1010 LightPathOffst_L_Actl 1;
BA_ "U_P702_MY2024_Tx" SG_ 1010 LightPathOffst_L_Actl 1;
BA_ "U_P708_MY2023_Rx" SG_ 1010 LightPath_An_Actl 1;
BA_ "U_CDX74X_MY2024_Rx" SG_ 1010 LightPath_An_Actl 1;
BA_ "U_V710_MY2023_Rx" SG_ 1010 LightPath_An_Actl 1;
BA_ "U_P702_MY2024_Rx" SG_ 1010 LightPath_An_Actl 1;
BA_ "U_P708_MY2023_Tx" SG_ 1010 LightPath_An_Actl 1;
BA_ "U_V710_MY2023_Tx" SG_ 1010 LightPath_An_Actl 1;
BA_ "U_P702_MY2024_Tx" SG_ 1010 LightPath_An_Actl 1;
BA_ "U_P708_MY2023_Rx" SG_ 1010 LightCurv_NoRate_Actl 1;
BA_ "U_CDX74X_MY2024_Rx" SG_ 1010 LightCurv_NoRate_Actl 1;
BA_ "U_V710_MY2023_Rx" SG_ 1010 LightCurv_NoRate_Actl 1;
BA_ "U_P702_MY2024_Rx" SG_ 1010 LightCurv_NoRate_Actl 1;
BA_ "U_P708_MY2023_Tx" SG_ 1010 LightCurv_NoRate_Actl 1;
BA_ "U_V710_MY2023_Tx" SG_ 1010 LightCurv_NoRate_Actl 1;
BA_ "U_P702_MY2024_Tx" SG_ 1010 LightCurv_NoRate_Actl 1;
BA_ "U_P708_MY2023_Rx" SG_ 1010 LightCurv_No_Actl 1;
BA_ "U_CDX74X_MY2024_Rx" SG_ 1010 LightCurv_No_Actl 1;
BA_ "U_V710_MY2023_Rx" SG_ 1010 LightCurv_No_Actl 1;
BA_ "U_P702_MY2024_Rx" SG_ 1010 LightCurv_No_Actl 1;
BA_ "U_P708_MY2023_Tx" SG_ 1010 LightCurv_No_Actl 1;
BA_ "U_V710_MY2023_Tx" SG_ 1010 LightCurv_No_Actl 1;
BA_ "U_P702_MY2024_Tx" SG_ 1010 LightCurv_No_Actl 1;
BA_ "U_P708_MY2023_Rx" SG_ 1010 MbdblActv_B_RqAdas 1;
BA_ "U_CDX74X_MY2024_Rx" SG_ 1010 MbdblActv_B_RqAdas 1;
BA_ "U_V710_MY2023_Rx" SG_ 1010 MbdblActv_B_RqAdas 1;
BA_ "U_P702_MY2024_Rx" SG_ 1010 MbdblActv_B_RqAdas 1;
BA_ "U_P708_MY2023_Tx" SG_ 1010 MbdblActv_B_RqAdas 1;
BA_ "U_V710_MY2023_Tx" SG_ 1010 MbdblActv_B_RqAdas 1;
BA_ "U_P702_MY2024_Tx" SG_ 1010 MbdblActv_B_RqAdas 1;
BA_ "U_P708_MY2023_Rx" SG_ 1010 CbdblActv_B_RqAdas 1;
BA_ "U_CDX74X_MY2024_Rx" SG_ 1010 CbdblActv_B_RqAdas 1;
BA_ "U_V710_MY2023_Rx" SG_ 1010 CbdblActv_B_RqAdas 1;
BA_ "U_P702_MY2024_Rx" SG_ 1010 CbdblActv_B_RqAdas 1;
BA_ "U_P708_MY2023_Tx" SG_ 1010 CbdblActv_B_RqAdas 1;
BA_ "U_V710_MY2023_Tx" SG_ 1010 CbdblActv_B_RqAdas 1;
BA_ "U_P702_MY2024_Tx" SG_ 1010 CbdblActv_B_RqAdas 1;
BA_ "U_P708_MY2023_Rx" SG_ 1010 AdbUrbanArea_B_Stat 1;
BA_ "U_CDX74X_MY2024_Rx" SG_ 1010 AdbUrbanArea_B_Stat 1;
BA_ "U_V710_MY2023_Rx" SG_ 1010 AdbUrbanArea_B_Stat 1;
BA_ "U_P702_MY2024_Rx" SG_ 1010 AdbUrbanArea_B_Stat 1;
BA_ "U_P708_MY2023_Tx" SG_ 1010 AdbUrbanArea_B_Stat 1;
BA_ "U_V710_MY2023_Tx" SG_ 1010 AdbUrbanArea_B_Stat 1;
BA_ "U_P702_MY2024_Tx" SG_ 1010 AdbUrbanArea_B_Stat 1;
BA_ "MetaData" SG_ 985 LongCtrlEnblDRq_No_Cs 1;
BA_ "ContentDependant" SG_ 985 LongCtrlEnblDRq_No_Cs 1;
BA_ "U_P708_MY2023_Tx" SG_ 985 LongCtrlEnblDRq_No_Cs 1;
BA_ "U_V710_MY2023_Tx" SG_ 985 LongCtrlEnblDRq_No_Cs 1;
BA_ "U_P702_MY2024_Tx" SG_ 985 LongCtrlEnblDRq_No_Cs 1;
BA_ "MetaData" SG_ 985 LongCtrlEnblDRq_No_Cnt 1;
BA_ "ContentDependant" SG_ 985 LongCtrlEnblDRq_No_Cnt 1;
BA_ "U_P708_MY2023_Tx" SG_ 985 LongCtrlEnblDRq_No_Cnt 1;
BA_ "U_V710_MY2023_Tx" SG_ 985 LongCtrlEnblDRq_No_Cnt 1;
BA_ "U_P702_MY2024_Tx" SG_ 985 LongCtrlEnblDRq_No_Cnt 1;
BA_ "GenSigSendType" SG_ 985 ClrExitAsst_D_Stat 3;
BA_ "U_P708_MY2023_Tx" SG_ 985 ClrExitAsst_D_Stat 1;
BA_ "U_V710_MY2023_Tx" SG_ 985 ClrExitAsst_D_Stat 1;
BA_ "U_P702_MY2024_Tx" SG_ 985 ClrExitAsst_D_Stat 1;
BA_ "GenSigSendType" SG_ 985 ClrExitAsstMsgTxt_D_Rq 3;
BA_ "U_P708_MY2023_Tx" SG_ 985 ClrExitAsstMsgTxt_D_Rq 1;
BA_ "U_V710_MY2023_Tx" SG_ 985 ClrExitAsstMsgTxt_D_Rq 1;
BA_ "U_P702_MY2024_Tx" SG_ 985 ClrExitAsstMsgTxt_D_Rq 1;
BA_ "GenSigSendType" SG_ 985 ClrExitAsstChime_D_Rq 3;
BA_ "U_P708_MY2023_Tx" SG_ 985 ClrExitAsstChime_D_Rq 1;
BA_ "U_V710_MY2023_Tx" SG_ 985 ClrExitAsstChime_D_Rq 1;
BA_ "U_P702_MY2024_Tx" SG_ 985 ClrExitAsstChime_D_Rq 1;
BA_ "GenSigSendType" SG_ 985 PwSustnAdas_B_Rq 3;
BA_ "U_P708_MY2023_Tx" SG_ 985 PwSustnAdas_B_Rq 1;
BA_ "U_V710_MY2023_Tx" SG_ 985 PwSustnAdas_B_Rq 1;
BA_ "U_P702_MY2024_Tx" SG_ 985 PwSustnAdas_B_Rq 1;
BA_ "GenSigSendType" SG_ 985 AdbDrvSide_B_Stat 3;
BA_ "U_P708_MY2023_Tx" SG_ 985 AdbDrvSide_B_Stat 1;
BA_ "U_V710_MY2023_Tx" SG_ 985 AdbDrvSide_B_Stat 1;
BA_ "U_P702_MY2024_Tx" SG_ 985 AdbDrvSide_B_Stat 1;
BA_ "GenSigSendType" SG_ 985 LcwaMsgTxt_D_Stat 3;
BA_ "U_P708_MY2023_Tx" SG_ 985 LcwaMsgTxt_D_Stat 1;
BA_ "U_V710_MY2023_Tx" SG_ 985 LcwaMsgTxt_D_Stat 1;
BA_ "U_P702_MY2024_Tx" SG_ 985 LcwaMsgTxt_D_Stat 1;
BA_ "GenSigSendType" SG_ 985 AdbDividedRoad_B_Stat 3;
BA_ "U_P708_MY2023_Tx" SG_ 985 AdbDividedRoad_B_Stat 1;
BA_ "U_V710_MY2023_Tx" SG_ 985 AdbDividedRoad_B_Stat 1;
BA_ "U_P702_MY2024_Tx" SG_ 985 AdbDividedRoad_B_Stat 1;
BA_ "GenSigSendType" SG_ 985 IsaVLimUnit_D_Rq 3;
BA_ "U_P708_MY2023_Tx" SG_ 985 IsaVLimUnit_D_Rq 1;
BA_ "U_V710_MY2023_Tx" SG_ 985 IsaVLimUnit_D_Rq 1;
BA_ "U_P702_MY2024_Tx" SG_ 985 IsaVLimUnit_D_Rq 1;
BA_ "GenSigSendType" SG_ 985 SblmYieldScnr_B_Stat 3;
BA_ "U_P708_MY2023_Rx" SG_ 985 SblmYieldScnr_B_Stat 1;
BA_ "U_CDX74X_MY2024_Rx" SG_ 985 SblmYieldScnr_B_Stat 1;
BA_ "U_V710_MY2023_Rx" SG_ 985 SblmYieldScnr_B_Stat 1;
BA_ "U_P702_MY2024_Rx" SG_ 985 SblmYieldScnr_B_Stat 1;
BA_ "U_P708_MY2023_Tx" SG_ 985 SblmYieldScnr_B_Stat 1;
BA_ "U_V710_MY2023_Tx" SG_ 985 SblmYieldScnr_B_Stat 1;
BA_ "U_P702_MY2024_Tx" SG_ 985 SblmYieldScnr_B_Stat 1;
BA_ "GenSigSendType" SG_ 985 SblmStopScnr_B_Stat 3;
BA_ "U_P708_MY2023_Rx" SG_ 985 SblmStopScnr_B_Stat 1;
BA_ "U_CDX74X_MY2024_Rx" SG_ 985 SblmStopScnr_B_Stat 1;
BA_ "U_V710_MY2023_Rx" SG_ 985 SblmStopScnr_B_Stat 1;
BA_ "U_P702_MY2024_Rx" SG_ 985 SblmStopScnr_B_Stat 1;
BA_ "U_P708_MY2023_Tx" SG_ 985 SblmStopScnr_B_Stat 1;
BA_ "U_V710_MY2023_Tx" SG_ 985 SblmStopScnr_B_Stat 1;
BA_ "U_P702_MY2024_Tx" SG_ 985 SblmStopScnr_B_Stat 1;
BA_ "GenSigStartValue" SG_ 985 IsaVLim_D_Rq 254;
BA_ "GenSigSendType" SG_ 985 IsaVLim_D_Rq 3;
BA_ "U_P708_MY2023_Tx" SG_ 985 IsaVLim_D_Rq 1;
BA_ "U_V710_MY2023_Tx" SG_ 985 IsaVLim_D_Rq 1;
BA_ "U_P702_MY2024_Tx" SG_ 985 IsaVLim_D_Rq 1;
BA_ "GenSigStartValue" SG_ 985 IaccVLimUnit_D_Rq 3;
BA_ "GenSigSendType" SG_ 985 IaccVLimUnit_D_Rq 3;
BA_ "U_P708_MY2023_Tx" SG_ 985 IaccVLimUnit_D_Rq 1;
BA_ "U_V710_MY2023_Tx" SG_ 985 IaccVLimUnit_D_Rq 1;
BA_ "U_P702_MY2024_Tx" SG_ 985 IaccVLimUnit_D_Rq 1;
BA_ "GenSigStartValue" SG_ 985 IaccVLim_D_Rq 254;
BA_ "GenSigSendType" SG_ 985 IaccVLim_D_Rq 3;
BA_ "U_P708_MY2023_Tx" SG_ 985 IaccVLim_D_Rq 1;
BA_ "U_V710_MY2023_Tx" SG_ 985 IaccVLim_D_Rq 1;
BA_ "U_P702_MY2024_Tx" SG_ 985 IaccVLim_D_Rq 1;
BA_ "GenSigSendType" SG_ 985 DasAlrtInfo_D_Dsply 3;
BA_ "U_P708_MY2023_Tx" SG_ 985 DasAlrtInfo_D_Dsply 1;
BA_ "U_V710_MY2023_Tx" SG_ 985 DasAlrtInfo_D_Dsply 1;
BA_ "U_P702_MY2024_Tx" SG_ 985 DasAlrtInfo_D_Dsply 1;
BA_ "GenSigSendType" SG_ 985 SblmRndAbtScnr_B_Stat 3;
BA_ "U_P708_MY2023_Rx" SG_ 985 SblmRndAbtScnr_B_Stat 1;
BA_ "U_CDX74X_MY2024_Rx" SG_ 985 SblmRndAbtScnr_B_Stat 1;
BA_ "U_V710_MY2023_Rx" SG_ 985 SblmRndAbtScnr_B_Stat 1;
BA_ "U_P702_MY2024_Rx" SG_ 985 SblmRndAbtScnr_B_Stat 1;
BA_ "U_P708_MY2023_Tx" SG_ 985 SblmRndAbtScnr_B_Stat 1;
BA_ "U_V710_MY2023_Tx" SG_ 985 SblmRndAbtScnr_B_Stat 1;
BA_ "U_P702_MY2024_Tx" SG_ 985 SblmRndAbtScnr_B_Stat 1;
BA_ "GenSigSendType" SG_ 985 LongCtrlEnbl_D_Rq 3;
BA_ "U_P708_MY2023_Tx" SG_ 985 LongCtrlEnbl_D_Rq 1;
BA_ "U_V710_MY2023_Tx" SG_ 985 LongCtrlEnbl_D_Rq 1;
BA_ "U_P702_MY2024_Tx" SG_ 985 LongCtrlEnbl_D_Rq 1;
BA_ "GenSigSendType" SG_ 985 SblmPedCrossScnr_B_Stat 3;
BA_ "U_P708_MY2023_Rx" SG_ 985 SblmPedCrossScnr_B_Stat 1;
BA_ "U_CDX74X_MY2024_Rx" SG_ 985 SblmPedCrossScnr_B_Stat 1;
BA_ "U_V710_MY2023_Rx" SG_ 985 SblmPedCrossScnr_B_Stat 1;
BA_ "U_P702_MY2024_Rx" SG_ 985 SblmPedCrossScnr_B_Stat 1;
BA_ "U_P708_MY2023_Tx" SG_ 985 SblmPedCrossScnr_B_Stat 1;
BA_ "U_V710_MY2023_Tx" SG_ 985 SblmPedCrossScnr_B_Stat 1;
BA_ "U_P702_MY2024_Tx" SG_ 985 SblmPedCrossScnr_B_Stat 1;
BA_ "GenSigSendType" SG_ 985 TsrRegionTxt_D_Stat 3;
BA_ "U_P708_MY2023_Tx" SG_ 985 TsrRegionTxt_D_Stat 1;
BA_ "U_V710_MY2023_Tx" SG_ 985 TsrRegionTxt_D_Stat 1;
BA_ "U_P702_MY2024_Tx" SG_ 985 TsrRegionTxt_D_Stat 1;
BA_ "GenSigSendType" SG_ 985 LongCtrlBrk_D_Rq 3;
BA_ "U_P708_MY2023_Tx" SG_ 985 LongCtrlBrk_D_Rq 1;
BA_ "U_V710_MY2023_Tx" SG_ 985 LongCtrlBrk_D_Rq 1;
BA_ "U_P702_MY2024_Tx" SG_ 985 LongCtrlBrk_D_Rq 1;
BA_ "GenSigSendType" SG_ 985 LdwChime_B_Rq 3;
BA_ "U_P708_MY2023_Tx" SG_ 985 LdwChime_B_Rq 1;
BA_ "U_V710_MY2023_Tx" SG_ 985 LdwChime_B_Rq 1;
BA_ "U_P702_MY2024_Tx" SG_ 985 LdwChime_B_Rq 1;
BA_ "GenSigSendType" SG_ 984 AhbFeat_D_Stat 3;
BA_ "U_P708_MY2023_Rx" SG_ 984 AhbFeat_D_Stat 1;
BA_ "U_P702_MY2024_Rx" SG_ 984 AhbFeat_D_Stat 1;
BA_ "U_CDX74X_MY2024_Rx" SG_ 984 AhbFeat_D_Stat 1;
BA_ "U_P708_MY2023_Tx" SG_ 984 AhbFeat_D_Stat 1;
BA_ "U_V710_MY2023_Tx" SG_ 984 AhbFeat_D_Stat 1;
BA_ "U_P702_MY2024_Tx" SG_ 984 AhbFeat_D_Stat 1;
BA_ "GenSigSendType" SG_ 984 LaActvStats_D2_Dsply 3;
BA_ "U_P708_MY2023_Tx" SG_ 984 LaActvStats_D2_Dsply 1;
BA_ "U_V710_MY2023_Tx" SG_ 984 LaActvStats_D2_Dsply 1;
BA_ "U_P702_MY2024_Tx" SG_ 984 LaActvStats_D2_Dsply 1;
BA_ "GenSigSendType" SG_ 984 DasWarn_D_Dsply 3;
BA_ "U_P708_MY2023_Tx" SG_ 984 DasWarn_D_Dsply 1;
BA_ "U_V710_MY2023_Tx" SG_ 984 DasWarn_D_Dsply 1;
BA_ "U_P702_MY2024_Tx" SG_ 984 DasWarn_D_Dsply 1;
BA_ "GenSigSendType" SG_ 984 DasStats_D_Dsply 3;
BA_ "U_P708_MY2023_Tx" SG_ 984 DasStats_D_Dsply 1;
BA_ "U_V710_MY2023_Tx" SG_ 984 DasStats_D_Dsply 1;
BA_ "U_P702_MY2024_Tx" SG_ 984 DasStats_D_Dsply 1;
BA_ "GenSigSendType" SG_ 984 DasAlrtLvl_D_Dsply 3;
BA_ "U_P708_MY2023_Tx" SG_ 984 DasAlrtLvl_D_Dsply 1;
BA_ "U_V710_MY2023_Tx" SG_ 984 DasAlrtLvl_D_Dsply 1;
BA_ "U_P702_MY2024_Tx" SG_ 984 DasAlrtLvl_D_Dsply 1;
BA_ "GenSigSendType" SG_ 984 CamraStats_D_Dsply 3;
BA_ "U_P708_MY2023_Tx" SG_ 984 CamraStats_D_Dsply 1;
BA_ "U_V710_MY2023_Tx" SG_ 984 CamraStats_D_Dsply 1;
BA_ "U_P702_MY2024_Tx" SG_ 984 CamraStats_D_Dsply 1;
BA_ "GenSigSendType" SG_ 984 CamraDefog_B_Req 3;
BA_ "U_P708_MY2023_Tx" SG_ 984 CamraDefog_B_Req 1;
BA_ "U_V710_MY2023_Tx" SG_ 984 CamraDefog_B_Req 1;
BA_ "U_P702_MY2024_Tx" SG_ 984 CamraDefog_B_Req 1;
BA_ "GenSigSendType" SG_ 984 LaHandsOff_D_Dsply 3;
BA_ "U_P708_MY2023_Tx" SG_ 984 LaHandsOff_D_Dsply 1;
BA_ "U_V710_MY2023_Tx" SG_ 984 LaHandsOff_D_Dsply 1;
BA_ "U_P702_MY2024_Tx" SG_ 984 LaHandsOff_D_Dsply 1;
BA_ "GenSigSendType" SG_ 984 LaDenyStats_B_Dsply 3;
BA_ "U_P708_MY2023_Tx" SG_ 984 LaDenyStats_B_Dsply 1;
BA_ "U_V710_MY2023_Tx" SG_ 984 LaDenyStats_B_Dsply 1;
BA_ "U_P702_MY2024_Tx" SG_ 984 LaDenyStats_B_Dsply 1;
BA_ "GenSigSendType" SG_ 984 AhbcRampingV_D_Rq 3;
BA_ "U_P708_MY2023_Tx" SG_ 984 AhbcRampingV_D_Rq 1;
BA_ "U_V710_MY2023_Tx" SG_ 984 AhbcRampingV_D_Rq 1;
BA_ "U_P702_MY2024_Tx" SG_ 984 AhbcRampingV_D_Rq 1;
BA_ "GenSigStartValue" SG_ 984 PersIndexIpma_D_Actl 4;
BA_ "GenSigSendType" SG_ 984 PersIndexIpma_D_Actl 3;
BA_ "U_P708_MY2023_Tx" SG_ 984 PersIndexIpma_D_Actl 1;
BA_ "U_V710_MY2023_Tx" SG_ 984 PersIndexIpma_D_Actl 1;
BA_ "U_P702_MY2024_Tx" SG_ 984 PersIndexIpma_D_Actl 1;
BA_ "GenSigSendType" SG_ 984 FeatNoIpmaActl 3;
BA_ "U_P708_MY2023_Tx" SG_ 984 FeatNoIpmaActl 1;
BA_ "U_V710_MY2023_Tx" SG_ 984 FeatNoIpmaActl 1;
BA_ "U_P702_MY2024_Tx" SG_ 984 FeatNoIpmaActl 1;
BA_ "GenSigSendType" SG_ 984 FeatConfigIpmaActl 3;
BA_ "U_P708_MY2023_Tx" SG_ 984 FeatConfigIpmaActl 1;
BA_ "U_V710_MY2023_Tx" SG_ 984 FeatConfigIpmaActl 1;
BA_ "U_P702_MY2024_Tx" SG_ 984 FeatConfigIpmaActl 1;
BA_ "GenSigSendType" SG_ 984 AhbHiBeam_D_Rq 3;
BA_ "U_P708_MY2023_Rx" SG_ 984 AhbHiBeam_D_Rq 1;
BA_ "U_P702_MY2024_Rx" SG_ 984 AhbHiBeam_D_Rq 1;
BA_ "U_P708_MY2023_Tx" SG_ 984 AhbHiBeam_D_Rq 1;
BA_ "U_V710_MY2023_Tx" SG_ 984 AhbHiBeam_D_Rq 1;
BA_ "U_P702_MY2024_Tx" SG_ 984 AhbHiBeam_D_Rq 1;
BA_ "GenSigSendType" SG_ 984 DsmcMsgTxt_D_Dsply 3;
BA_ "U_P708_MY2023_Tx" SG_ 984 DsmcMsgTxt_D_Dsply 1;
BA_ "U_V710_MY2023_Tx" SG_ 984 DsmcMsgTxt_D_Dsply 1;
BA_ "U_P702_MY2024_Tx" SG_ 984 DsmcMsgTxt_D_Dsply 1;
BA_ "U_V713N_MY2022_Rx" SG_ 983 CmbbObjRelLong_V_Actl 1;
BA_ "U_P708_MY2023_Rx" SG_ 983 CmbbObjRelLong_V_Actl 1;
BA_ "U_CDX74X_MY2024_Rx" SG_ 983 CmbbObjRelLong_V_Actl 1;
BA_ "U_V710_MY2023_Rx" SG_ 983 CmbbObjRelLong_V_Actl 1;
BA_ "U_P702_MY2024_Rx" SG_ 983 CmbbObjRelLong_V_Actl 1;
BA_ "U_P708_MY2023_Tx" SG_ 983 CmbbObjRelLong_V_Actl 1;
BA_ "U_V710_MY2023_Tx" SG_ 983 CmbbObjRelLong_V_Actl 1;
BA_ "U_P702_MY2024_Tx" SG_ 983 CmbbObjRelLong_V_Actl 1;
BA_ "GenSigStartValue" SG_ 983 CmbbObjRelLat_V_Actl 510;
BA_ "U_V713N_MY2022_Rx" SG_ 983 CmbbObjRelLat_V_Actl 1;
BA_ "U_P708_MY2023_Rx" SG_ 983 CmbbObjRelLat_V_Actl 1;
BA_ "U_CDX74X_MY2024_Rx" SG_ 983 CmbbObjRelLat_V_Actl 1;
BA_ "U_V710_MY2023_Rx" SG_ 983 CmbbObjRelLat_V_Actl 1;
BA_ "U_P702_MY2024_Rx" SG_ 983 CmbbObjRelLat_V_Actl 1;
BA_ "U_P708_MY2023_Tx" SG_ 983 CmbbObjRelLat_V_Actl 1;
BA_ "U_V710_MY2023_Tx" SG_ 983 CmbbObjRelLat_V_Actl 1;
BA_ "U_P702_MY2024_Tx" SG_ 983 CmbbObjRelLat_V_Actl 1;
BA_ "GenSigStartValue" SG_ 983 CmbbObjDistLong_L_Actl 1022;
BA_ "U_V713N_MY2022_Rx" SG_ 983 CmbbObjDistLong_L_Actl 1;
BA_ "U_P708_MY2023_Rx" SG_ 983 CmbbObjDistLong_L_Actl 1;
BA_ "U_CDX74X_MY2024_Rx" SG_ 983 CmbbObjDistLong_L_Actl 1;
BA_ "U_V710_MY2023_Rx" SG_ 983 CmbbObjDistLong_L_Actl 1;
BA_ "U_P702_MY2024_Rx" SG_ 983 CmbbObjDistLong_L_Actl 1;
BA_ "U_P708_MY2023_Tx" SG_ 983 CmbbObjDistLong_L_Actl 1;
BA_ "U_V710_MY2023_Tx" SG_ 983 CmbbObjDistLong_L_Actl 1;
BA_ "U_P702_MY2024_Tx" SG_ 983 CmbbObjDistLong_L_Actl 1;
BA_ "GenSigStartValue" SG_ 983 CmbbObjDistLat_L_Actl 510;
BA_ "U_V713N_MY2022_Rx" SG_ 983 CmbbObjDistLat_L_Actl 1;
BA_ "U_P708_MY2023_Rx" SG_ 983 CmbbObjDistLat_L_Actl 1;
BA_ "U_CDX74X_MY2024_Rx" SG_ 983 CmbbObjDistLat_L_Actl 1;
BA_ "U_V710_MY2023_Rx" SG_ 983 CmbbObjDistLat_L_Actl 1;
BA_ "U_P702_MY2024_Rx" SG_ 983 CmbbObjDistLat_L_Actl 1;
BA_ "U_P708_MY2023_Tx" SG_ 983 CmbbObjDistLat_L_Actl 1;
BA_ "U_V710_MY2023_Tx" SG_ 983 CmbbObjDistLat_L_Actl 1;
BA_ "U_P702_MY2024_Tx" SG_ 983 CmbbObjDistLat_L_Actl 1;
BA_ "U_V713N_MY2022_Rx" SG_ 983 CmbbObjConfdnc_D_Stat 1;
BA_ "U_P708_MY2023_Rx" SG_ 983 CmbbObjConfdnc_D_Stat 1;
BA_ "U_CDX74X_MY2024_Rx" SG_ 983 CmbbObjConfdnc_D_Stat 1;
BA_ "U_V710_MY2023_Rx" SG_ 983 CmbbObjConfdnc_D_Stat 1;
BA_ "U_P702_MY2024_Rx" SG_ 983 CmbbObjConfdnc_D_Stat 1;
BA_ "U_P708_MY2023_Tx" SG_ 983 CmbbObjConfdnc_D_Stat 1;
BA_ "U_V710_MY2023_Tx" SG_ 983 CmbbObjConfdnc_D_Stat 1;
BA_ "U_P702_MY2024_Tx" SG_ 983 CmbbObjConfdnc_D_Stat 1;
BA_ "GenSigStartValue" SG_ 983 CmbbObjColl_T_Actl 125;
BA_ "U_V713N_MY2022_Rx" SG_ 983 CmbbObjColl_T_Actl 1;
BA_ "U_P708_MY2023_Rx" SG_ 983 CmbbObjColl_T_Actl 1;
BA_ "U_CDX74X_MY2024_Rx" SG_ 983 CmbbObjColl_T_Actl 1;
BA_ "U_V710_MY2023_Rx" SG_ 983 CmbbObjColl_T_Actl 1;
BA_ "U_P702_MY2024_Rx" SG_ 983 CmbbObjColl_T_Actl 1;
BA_ "U_P708_MY2023_Tx" SG_ 983 CmbbObjColl_T_Actl 1;
BA_ "U_V710_MY2023_Tx" SG_ 983 CmbbObjColl_T_Actl 1;
BA_ "U_P702_MY2024_Tx" SG_ 983 CmbbObjColl_T_Actl 1;
BA_ "U_V713N_MY2022_Rx" SG_ 983 CmbbObjClass_D_Stat 1;
BA_ "U_P708_MY2023_Rx" SG_ 983 CmbbObjClass_D_Stat 1;
BA_ "U_CDX74X_MY2024_Rx" SG_ 983 CmbbObjClass_D_Stat 1;
BA_ "U_V710_MY2023_Rx" SG_ 983 CmbbObjClass_D_Stat 1;
BA_ "U_P702_MY2024_Rx" SG_ 983 CmbbObjClass_D_Stat 1;
BA_ "U_P708_MY2023_Tx" SG_ 983 CmbbObjClass_D_Stat 1;
BA_ "U_V710_MY2023_Tx" SG_ 983 CmbbObjClass_D_Stat 1;
BA_ "U_P702_MY2024_Tx" SG_ 983 CmbbObjClass_D_Stat 1;
BA_ "U_V713N_MY2022_Rx" SG_ 983 EsaEnbl_D2_Rq 1;
BA_ "U_P708_MY2023_Rx" SG_ 983 EsaEnbl_D2_Rq 1;
BA_ "U_CDX74X_MY2024_Rx" SG_ 983 EsaEnbl_D2_Rq 1;
BA_ "U_V710_MY2023_Rx" SG_ 983 EsaEnbl_D2_Rq 1;
BA_ "U_P702_MY2024_Rx" SG_ 983 EsaEnbl_D2_Rq 1;
BA_ "U_P708_MY2023_Tx" SG_ 983 EsaEnbl_D2_Rq 1;
BA_ "U_V710_MY2023_Tx" SG_ 983 EsaEnbl_D2_Rq 1;
BA_ "U_P702_MY2024_Tx" SG_ 983 EsaEnbl_D2_Rq 1;
BA_ "U_V713N_MY2022_Rx" SG_ 970 LkaDrvOvrrd_D_Rq 1;
BA_ "U_P708_MY2023_Rx" SG_ 970 LkaDrvOvrrd_D_Rq 1;
BA_ "U_CDX74X_MY2024_Rx" SG_ 970 LkaDrvOvrrd_D_Rq 1;
BA_ "U_V710_MY2023_Rx" SG_ 970 LkaDrvOvrrd_D_Rq 1;
BA_ "U_P702_MY2024_Rx" SG_ 970 LkaDrvOvrrd_D_Rq 1;
BA_ "U_P708_MY2023_Tx" SG_ 970 LkaDrvOvrrd_D_Rq 1;
BA_ "U_V710_MY2023_Tx" SG_ 970 LkaDrvOvrrd_D_Rq 1;
BA_ "U_P702_MY2024_Tx" SG_ 970 LkaDrvOvrrd_D_Rq 1;
BA_ "U_V713N_MY2022_Rx" SG_ 970 LkaActvStats_D2_Req 1;
BA_ "U_P708_MY2023_Rx" SG_ 970 LkaActvStats_D2_Req 1;
BA_ "U_CDX74X_MY2024_Rx" SG_ 970 LkaActvStats_D2_Req 1;
BA_ "U_V710_MY2023_Rx" SG_ 970 LkaActvStats_D2_Req 1;
BA_ "U_P702_MY2024_Rx" SG_ 970 LkaActvStats_D2_Req 1;
BA_ "U_P708_MY2023_Tx" SG_ 970 LkaActvStats_D2_Req 1;
BA_ "U_V710_MY2023_Tx" SG_ 970 LkaActvStats_D2_Req 1;
BA_ "U_P702_MY2024_Tx" SG_ 970 LkaActvStats_D2_Req 1;
BA_ "U_V713N_MY2022_Rx" SG_ 970 LaRefAng_No_Req 1;
BA_ "U_P708_MY2023_Rx" SG_ 970 LaRefAng_No_Req 1;
BA_ "U_CDX74X_MY2024_Rx" SG_ 970 LaRefAng_No_Req 1;
BA_ "U_V710_MY2023_Rx" SG_ 970 LaRefAng_No_Req 1;
BA_ "U_P702_MY2024_Rx" SG_ 970 LaRefAng_No_Req 1;
BA_ "U_P708_MY2023_Tx" SG_ 970 LaRefAng_No_Req 1;
BA_ "U_V710_MY2023_Tx" SG_ 970 LaRefAng_No_Req 1;
BA_ "U_P702_MY2024_Tx" SG_ 970 LaRefAng_No_Req 1;
BA_ "U_V713N_MY2022_Rx" SG_ 970 LaRampType_B_Req 1;
BA_ "U_P708_MY2023_Rx" SG_ 970 LaRampType_B_Req 1;
BA_ "U_CDX74X_MY2024_Rx" SG_ 970 LaRampType_B_Req 1;
BA_ "U_V710_MY2023_Rx" SG_ 970 LaRampType_B_Req 1;
BA_ "U_P702_MY2024_Rx" SG_ 970 LaRampType_B_Req 1;
BA_ "U_P708_MY2023_Tx" SG_ 970 LaRampType_B_Req 1;
BA_ "U_V710_MY2023_Tx" SG_ 970 LaRampType_B_Req 1;
BA_ "U_P702_MY2024_Tx" SG_ 970 LaRampType_B_Req 1;
BA_ "U_V713N_MY2022_Rx" SG_ 970 LaCurvature_No_Calc 1;
BA_ "U_P708_MY2023_Rx" SG_ 970 LaCurvature_No_Calc 1;
BA_ "U_CDX74X_MY2024_Rx" SG_ 970 LaCurvature_No_Calc 1;
BA_ "U_V710_MY2023_Rx" SG_ 970 LaCurvature_No_Calc 1;
BA_ "U_P702_MY2024_Rx" SG_ 970 LaCurvature_No_Calc 1;
BA_ "U_P708_MY2023_Tx" SG_ 970 LaCurvature_No_Calc 1;
BA_ "U_V710_MY2023_Tx" SG_ 970 LaCurvature_No_Calc 1;
BA_ "U_P702_MY2024_Tx" SG_ 970 LaCurvature_No_Calc 1;
BA_ "U_V713N_MY2022_Rx" SG_ 970 LdwActvStats_D_Req 1;
BA_ "U_P708_MY2023_Rx" SG_ 970 LdwActvStats_D_Req 1;
BA_ "U_CDX74X_MY2024_Rx" SG_ 970 LdwActvStats_D_Req 1;
BA_ "U_V710_MY2023_Rx" SG_ 970 LdwActvStats_D_Req 1;
BA_ "U_P702_MY2024_Rx" SG_ 970 LdwActvStats_D_Req 1;
BA_ "U_P708_MY2023_Tx" SG_ 970 LdwActvStats_D_Req 1;
BA_ "U_V710_MY2023_Tx" SG_ 970 LdwActvStats_D_Req 1;
BA_ "U_P702_MY2024_Tx" SG_ 970 LdwActvStats_D_Req 1;
BA_ "U_V713N_MY2022_Rx" SG_ 970 LdwActvIntns_D_Req 1;
BA_ "U_P708_MY2023_Rx" SG_ 970 LdwActvIntns_D_Req 1;
BA_ "U_CDX74X_MY2024_Rx" SG_ 970 LdwActvIntns_D_Req 1;
BA_ "U_V710_MY2023_Rx" SG_ 970 LdwActvIntns_D_Req 1;
BA_ "U_P702_MY2024_Rx" SG_ 970 LdwActvIntns_D_Req 1;
BA_ "U_P708_MY2023_Tx" SG_ 970 LdwActvIntns_D_Req 1;
BA_ "U_V710_MY2023_Tx" SG_ 970 LdwActvIntns_D_Req 1;
BA_ "U_P702_MY2024_Tx" SG_ 970 LdwActvIntns_D_Req 1;
BA_REL_ "SC_Verification" BU_SG_REL_ IPMA_ADAS SG_ 1003 RecallEvent_No_Cnt 1;
BA_REL_ "SC_Verification" BU_SG_REL_ IPMA_ADAS SG_ 1003 PersNo_D_Actl 1;
BA_REL_ "SC_Verification" BU_SG_REL_ HCM SG_ 909 HeadLghtHiPrmsn_D_Stat 1;
BA_REL_ "SC_Verification" BU_SG_REL_ IPMA_ADAS SG_ 909 HeadLghtHiPrmsn_D_Stat 1;
BA_REL_ "SC_Verification" BU_SG_REL_ IPMA_ADAS SG_ 963 HeadLghtSwtch_D_Stat 1;
BA_REL_ "SC_Verification" BU_SG_REL_ HCM SG_ 1010 LightRng_L_Max 1;
BA_REL_ "SC_Verification" BU_SG_REL_ HCM SG_ 1010 LightPathOffst_L_Actl 1;
BA_REL_ "SC_Verification" BU_SG_REL_ HCM SG_ 1010 LightPath_An_Actl 1;
BA_REL_ "SC_Verification" BU_SG_REL_ HCM SG_ 1010 LightCurv_NoRate_Actl 1;
BA_REL_ "SC_Verification" BU_SG_REL_ HCM SG_ 1010 LightCurv_No_Actl 1;
BA_REL_ "SC_Verification" BU_SG_REL_ HCM SG_ 985 SblmYieldScnr_B_Stat 1;
BA_REL_ "SC_Verification" BU_SG_REL_ HCM SG_ 985 SblmStopScnr_B_Stat 1;
BA_REL_ "SC_Verification" BU_SG_REL_ HCM SG_ 985 SblmRndAbtScnr_B_Stat 1;
VAL_ 831 MirrorTelescopic_D_Rq 3 "NotUsed" 2 "Retract" 1 "Extend" 0 "Null" ;
VAL_ 831 RearPassWindowLockCmd 1 "Enable" 0 "Disable" ;
VAL_ 831 RearPassWindowCmd 7 "Unused2" 6 "Unused1" 5 "NotDefined" 4 "Audo_Down" 3 "Manual_Down" 2 "Auto_Up" 1 "Manual_Up" 0 "Idle" ;
VAL_ 831 PassWindowCmd 7 "Unused2" 6 "Unused1" 5 "NotDefined" 4 "Audo_Down" 3 "Manual_Down" 2 "Auto_Up" 1 "Manual_Up" 0 "Idle" ;
VAL_ 831 PassMirrorCmd 7 "Unused" 6 "Unfold" 5 "Fold" 4 "Right" 3 "Left" 2 "Down" 1 "Up" 0 "Idle" ;
VAL_ 831 DipMirrorPosPassenger 1 "Dipped" 0 "Off" ;
VAL_ 831 ActiveStoragePassenger 7 "Unused3" 6 "Unused2" 5 "Unused1" 4 "StoreDipMemoryButton4" 3 "StoreDipMemoryButton3" 2 "StoreDipMemoryButton2" 1 "StoreDipMemoryButton1" 0 "Off" ;
VAL_ 831 RearDriverWindowPos 7 "Unused2" 6 "Unused1" 5 "Fully_Open" 4 "Bet60Percent_FullyOpen" 3 "Bet10Percent_60Percent" 2 "BetFully_10PercentOpen" 1 "Fully_Closed" 0 "Undefined" ;
VAL_ 831 DriverWindowPosition 7 "Unused2" 6 "Unused1" 5 "Fully_Open" 4 "Bet60Percent_FullyOpen" 3 "Bet10Percent_60Percent" 2 "BetFully_10PercentOpen" 1 "Fully_Closed" 0 "Undefined" ;
VAL_ 1258 TrlrCamraCalib_D_Stat 3 "NotUsed_2" 2 "NotUsed_1" 1 "Calibrating" 0 "NotCalibrating" ;
VAL_ 1258 TrlrCamraView_D_Stat 15 "NotUsed_9" 14 "NotUsed_8" 13 "NotUsed_7" 12 "NotUsed_6" 11 "NotUsed_5" 10 "NotUsed_4" 9 "NotUsed_3" 8 "NotUsed_2" 7 "NotUsed_1" 6 "TrailerRightSideView" 5 "TrailerLeftSideView" 4 "TrailerInteriorView2" 3 "TrailerInteriorView1" 2 "TrailerRearNormalView" 1 "Trailer360View" 0 "Off" ;
VAL_ 648 TrlrCamraCalib_D_Rq 3 "NotUsed_2" 2 "NotUsed_1" 1 "CalibrationRequested" 0 "CalibrationNotRequested" ;
VAL_ 1158 SodAltRight_D2_StatAft 3 "Faulty" 2 "ActiveDetection" 1 "ActiveNoDetection" 0 "Standby" ;
VAL_ 1157 SodAltLeft_D2_StatAft 3 "Faulty" 2 "ActiveDetection" 1 "ActiveNoDetection" 0 "Standby" ;
VAL_ 1208 Btt_L2_Actl2 127 "Faulty" 126 "NoDataExists" ;
VAL_ 1218 OprtSrc_D_Stat 7 "NotUsed_5" 6 "NotUsed_4" 5 "NotUsed_3" 4 "NotUsed_2" 3 "NotUsed_1" 2 "Handsfree" 1 "RemoteKey" 0 "Null" ;
VAL_ 1218 DrPsngrRearLck_D_Stat 3 "NoDeviceOrDoor" 2 "Unlocked" 1 "Locked" 0 "Null" ;
VAL_ 1218 DrDrvRearLck_D_Stat 3 "NoDeviceOrDoor" 2 "Unlocked" 1 "Locked" 0 "Null" ;
VAL_ 1218 ClsrOprtSrvc_D_Res 15 "Faulty" 14 "NotUsed_7" 13 "NotUsed_6" 12 "NotUsed_5" 11 "NotUsed_4" 10 "NotUsed_3" 9 "NotUsed_2" 8 "NotUsed_1" 7 "Invalid" 6 "In_Prog" 5 "Failed" 4 "Interrupted" 3 "Rejected" 2 "Pending" 1 "Success" 0 "Null" ;
VAL_ 1218 LckUnlckSrvc_D_Res 15 "Faulty" 14 "NotUsed_7" 13 "NotUsed_6" 12 "NotUsed_5" 11 "NotUsed_4" 10 "NotUsed_3" 9 "NotUsed_2" 8 "NotUsed_1" 7 "Invalid" 6 "In_Prog" 5 "Failed" 4 "Interrupted" 3 "Rejected" 2 "Pending" 1 "Success" 0 "Null" ;
VAL_ 1218 ClsrOprtSrvc_D_Arb 3 "NotUsed_1" 2 "Soa" 1 "Local" 0 "Null" ;
VAL_ 1218 LckUnlckSrvc_D_Arb 3 "NotUsed_1" 2 "Soa" 1 "Local" 0 "Null" ;
VAL_ 1218 LatchFdbck_B_Stat 1 "Inferred" 0 "Real" ;
VAL_ 1218 FecSwtchExtLck_D_Stat 3 "NoDeviceOrDoor" 2 "Unlocked" 1 "Locked" 0 "Null" ;
VAL_ 1218 DrPsngrLck_D_Stat 3 "NoDeviceOrDoor" 2 "Unlocked" 1 "Locked" 0 "Null" ;
VAL_ 1218 DrDrvLck_D_Stat 3 "NoDeviceOrDoor" 2 "Unlocked" 1 "Locked" 0 "Null" ;
VAL_ 1218 BecSwtchExtLck_D_Stat 3 "NoDeviceOrDoor" 2 "Unlocked" 1 "Locked" 0 "Null" ;
VAL_ 1218 BecSwtch2ExtLck_D_Stat 3 "NoDeviceOrDoor" 2 "Unlocked" 1 "Locked" 0 "Null" ;
VAL_ 1043 SelDrvMdeHmi02_D_Rq 31 "Faulty" 30 "SelDrvMde31" 29 "SelDrvMde30" 28 "SelDrvMde29" 27 "SelDrvMde28" 26 "SelDrvMde27" 25 "SelDrvMde26" 24 "SelDrvMde25" 23 "SelDrvMde24" 22 "SelDrvMde23" 21 "SelDrvMde22" 20 "SelDrvMde21" 19 "SelDrvMde20" 18 "SelDrvMde19" 17 "SelDrvMde18" 16 "SelDrvMde17" 15 "SelDrvMde16" 14 "SelDrvMde15" 13 "SelDrvMde14" 12 "SelDrvMde13" 11 "SelDrvMde12" 10 "SelDrvMde11" 9 "SelDrvMde10" 8 "SelDrvMde09" 7 "SelDrvMde08" 6 "SelDrvMde07" 5 "SelDrvMde06" 4 "SelDrvMde05" 3 "SelDrvMde04" 2 "SelDrvMde03" 1 "SelDrvMde02" 0 "SelDrvMde01" ;
VAL_ 1043 OrtaSwtchLamp_B_Rq 1 "On" 0 "Off" ;
VAL_ 1043 OrtaMsgTxt_D_Rq 15 "Message15" 14 "Message14" 13 "Message13" 12 "Message12" 11 "Message11" 10 "Message10" 9 "Message9" 8 "Message8" 7 "Message7" 6 "Message6" 5 "Message5" 4 "Message4" 3 "Message3" 2 "Message2" 1 "Message1" 0 "NoMessage" ;
VAL_ 1043 OrtaMde_D_Ind 2 "StandbyRight" 1 "StandbyLeft" 0 "Off" 7 "Faulty" 6 "NotUsed_2" 5 "NotUsed_1" 4 "ActiveRight" 3 "ActiveLeft" ;
VAL_ 1049 TrailCtlSwtch_B_Stat4 1 "Pressed" 0 "Not_Pressed" ;
VAL_ 1049 StabBarCnncButtn_D_Sta3 3 "Faulty" 2 "NotUsed" 1 "Pressed" 0 "Not_Pressed" ;
VAL_ 1049 RearDiffLck_D_RqDrv3 3 "Faulty" 2 "NoRequest" 1 "On" 0 "Off" ;
VAL_ 1049 FrontDiffLck_D_RqDrv3 3 "Faulty" 2 "NoRequest" 1 "On" 0 "Off" ;
VAL_ 1049 TurnAsstSwtch_D_Stat 3 "Faulty" 2 "NotUsed" 1 "Pressed" 0 "Not_Pressed" ;
VAL_ 1049 SelDrvMdeTxtRst_B_Rq2 1 "Yes" 0 "No" ;
VAL_ 1049 SelDrvMdePage_B_Stat 1 "Active" 0 "Inactive" ;
VAL_ 1049 SelDrvMdeCnfm_D_Stat2 3 "NotUsed" 2 "Accepted" 1 "NotAccepted" 0 "Null" ;
VAL_ 1049 SelDrvMde_D_RqDrv 31 "Faulty" 30 "SelDrvMde31" 29 "SelDrvMde30" 28 "SelDrvMde29" 27 "SelDrvMde28" 26 "SelDrvMde27" 25 "SelDrvMde26" 24 "SelDrvMde25" 23 "SelDrvMde24" 22 "SelDrvMde23" 21 "SelDrvMde22" 20 "SelDrvMde21" 19 "SelDrvMde20" 18 "SelDrvMde19" 17 "SelDrvMde18" 16 "SelDrvMde17" 15 "SelDrvMde16" 14 "SelDrvMde15" 13 "SelDrvMde14" 12 "SelDrvMde13" 11 "SelDrvMde12" 10 "SelDrvMde11" 9 "SelDrvMde10" 8 "SelDrvMde09" 7 "SelDrvMde08" 6 "SelDrvMde07" 5 "SelDrvMde06" 4 "SelDrvMde05" 3 "SelDrvMde04" 2 "SelDrvMde03" 1 "SelDrvMde02" 0 "SelDrvMde01" ;
VAL_ 1049 Chrgr_Pw_EstMx 511 "Faulty" 510 "NoDataExists" ;
VAL_ 1049 DcacZone3PwBttn_B_Stat 1 "Pressed" 0 "Not_Pressed" ;
VAL_ 1049 DcacZone2PwBttn_B_Stat 1 "Pressed" 0 "Not_Pressed" ;
VAL_ 1049 DcacPwResetBtn2_B_Stat 1 "Pressed" 0 "Not_Pressed" ;
VAL_ 1049 DcacPwOffButtn2_B_Stat 1 "Pressed" 0 "Not_Pressed" ;
VAL_ 1049 DcacPwHiButtn2_B_Stat 1 "Pressed" 0 "Not_Pressed" ;
VAL_ 1049 DcacGfciTestBtn2_B_Stat 1 "Pressed" 0 "Not_Pressed" ;
VAL_ 1049 DcacAllZoneBttn_B_Stat 1 "Pressed" 0 "Not_Pressed" ;
VAL_ 1049 DcacChime_D_Rq 3 "NotUsed" 2 "SoftChime" 1 "InformationChime" 0 "NoChime" ;
VAL_ 1049 PersTurnSglView_D_RqMnu 3 "NotUsed" 2 "Enable" 1 "Disable" 0 "Null" ;
VAL_ 1049 CamraFrnt_B_RqMnu 1 "On" 0 "Off" ;
VAL_ 595 DrvIdMde_D_Rq 7 "Faulty" 6 "NotUsed_2" 5 "KeepAwake" 4 "DeleteMid" 3 "ClearAll" 2 "Enroll" 1 "Recognize" 0 "Disable" ;
VAL_ 595 EngIdlShutDownT_D_Rq 255 "NotUsed_13" 254 "NotUsed_12" 253 "NotUsed_11" 252 "NotUsed_10" 251 "NotUsed_9" 250 "NotUsed_8" 249 "NotUsed_7" 248 "NotUsed_6" 247 "NotUsed_5" 246 "NotUsed_4" 245 "NotUsed_3" 244 "NotUsed_2" 243 "NotUsed_1" 242 "Indefinite_Idle" 241 "Selectable_Idle_Not_Active" 240 "IdleMinutes_240" 239 "IdleMinutes_239" 238 "IdleMinutes_238" 237 "IdleMinutes_237" 236 "IdleMinutes_236" 235 "IdleMinutes_235" 234 "IdleMinutes_234" 233 "IdleMinutes_233" 232 "IdleMinutes_232" 231 "IdleMinutes_231" 230 "IdleMinutes_230" 229 "IdleMinutes_229" 228 "IdleMinutes_228" 227 "IdleMinutes_227" 226 "IdleMinutes_226" 225 "IdleMinutes_225" 224 "IdleMinutes_224" 223 "IdleMinutes_223" 222 "IdleMinutes_222" 221 "IdleMinutes_221" 220 "IdleMinutes_220" 219 "IdleMinutes_219" 218 "IdleMinutes_218" 217 "IdleMinutes_217" 216 "IdleMinutes_216" 215 "IdleMinutes_215" 214 "IdleMinutes_214" 213 "IdleMinutes_213" 212 "IdleMinutes_212" 211 "IdleMinutes_211" 210 "IdleMinutes_210" 209 "IdleMinutes_209" 208 "IdleMinutes_208" 207 "IdleMinutes_207" 206 "IdleMinutes_206" 205 "IdleMinutes_205" 204 "IdleMinutes_204" 203 "IdleMinutes_203" 202 "IdleMinutes_202" 201 "IdleMinutes_201" 200 "IdleMinutes_200" 199 "IdleMinutes_199" 198 "IdleMinutes_198" 197 "IdleMinutes_197" 196 "IdleMinutes_196" 195 "IdleMinutes_195" 194 "IdleMinutes_194" 193 "IdleMinutes_193" 192 "IdleMinutes_192" 191 "IdleMinutes_191" 190 "IdleMinutes_190" 189 "IdleMinutes_189" 188 "IdleMinutes_188" 187 "IdleMinutes_187" 186 "IdleMinutes_186" 185 "IdleMinutes_185" 184 "IdleMinutes_184" 183 "IdleMinutes_183" 182 "IdleMinutes_182" 181 "IdleMinutes_181" 180 "IdleMinutes_180" 179 "IdleMinutes_179" 178 "IdleMinutes_178" 177 "IdleMinutes_177" 176 "IdleMinutes_176" 175 "IdleMinutes_175" 174 "IdleMinutes_174" 173 "IdleMinutes_173" 172 "IdleMinutes_172" 171 "IdleMinutes_171" 170 "IdleMinutes_170" 169 "IdleMinutes_169" 168 "IdleMinutes_168" 167 "IdleMinutes_167" 166 "IdleMinutes_166" 165 "IdleMinutes_165" 164 "IdleMinutes_164" 163 "IdleMinutes_163" 162 "IdleMinutes_162" 161 "IdleMinutes_161" 160 "IdleMinutes_160" 159 "IdleMinutes_159" 158 "IdleMinutes_158" 157 "IdleMinutes_157" 156 "IdleMinutes_156" 155 "IdleMinutes_155" 154 "IdleMinutes_154" 153 "IdleMinutes_153" 152 "IdleMinutes_152" 151 "IdleMinutes_151" 150 "IdleMinutes_150" 149 "IdleMinutes_149" 148 "IdleMinutes_148" 147 "IdleMinutes_147" 146 "IdleMinutes_146" 145 "IdleMinutes_145" 144 "IdleMinutes_144" 143 "IdleMinutes_143" 142 "IdleMinutes_142" 141 "IdleMinutes_141" 140 "IdleMinutes_140" 139 "IdleMinutes_139" 138 "IdleMinutes_138" 137 "IdleMinutes_137" 136 "IdleMinutes_136" 135 "IdleMinutes_135" 134 "IdleMinutes_134" 133 "IdleMinutes_133" 132 "IdleMinutes_132" 131 "IdleMinutes_131" 130 "IdleMinutes_130" 129 "IdleMinutes_129" 128 "IdleMinutes_128" 127 "IdleMinutes_127" 126 "IdleMinutes_126" 125 "IdleMinutes_125" 124 "IdleMinutes_124" 123 "IdleMinutes_123" 122 "IdleMinutes_122" 121 "IdleMinutes_121" 120 "IdleMinutes_120" 119 "IdleMinutes_119" 118 "IdleMinutes_118" 117 "IdleMinutes_117" 116 "IdleMinutes_116" 115 "IdleMinutes_115" 114 "IdleMinutes_114" 113 "IdleMinutes_113" 112 "IdleMinutes_112" 111 "IdleMinutes_111" 110 "IdleMinutes_110" 109 "IdleMinutes_109" 108 "IdleMinutes_108" 107 "IdleMinutes_107" 106 "IdleMinutes_106" 105 "IdleMinutes_105" 104 "IdleMinutes_104" 103 "IdleMinutes_103" 102 "IdleMinutes_102" 101 "IdleMinutes_101" 100 "IdleMinutes_100" 99 "IdleMinutes_99" 98 "IdleMinutes_98" 97 "IdleMinutes_97" 96 "IdleMinutes_96" 95 "IdleMinutes_95" 94 "IdleMinutes_94" 93 "IdleMinutes_93" 92 "IdleMinutes_92" 91 "IdleMinutes_91" 90 "IdleMinutes_90" 89 "IdleMinutes_89" 88 "IdleMinutes_88" 87 "IdleMinutes_87" 86 "IdleMinutes_86" 85 "IdleMinutes_85" 84 "IdleMinutes_84" 83 "IdleMinutes_83" 82 "IdleMinutes_82" 81 "IdleMinutes_81" 80 "IdleMinutes_80" 79 "IdleMinutes_79" 78 "IdleMinutes_78" 77 "IdleMinutes_77" 76 "IdleMinutes_76" 75 "IdleMinutes_75" 74 "IdleMinutes_74" 73 "IdleMinutes_73" 72 "IdleMinutes_72" 71 "IdleMinutes_71" 70 "IdleMinutes_70" 69 "IdleMinutes_69" 68 "IdleMinutes_68" 67 "IdleMinutes_67" 66 "IdleMinutes_66" 65 "IdleMinutes_65" 64 "IdleMinutes_64" 63 "IdleMinutes_63" 62 "IdleMinutes_62" 61 "IdleMinutes_61" 60 "IdleMinutes_60" 59 "IdleMinutes_59" 58 "IdleMinutes_58" 57 "IdleMinutes_57" 56 "IdleMinutes_56" 55 "IdleMinutes_55" 54 "IdleMinutes_54" 53 "IdleMinutes_53" 52 "IdleMinutes_52" 51 "IdleMinutes_51" 50 "IdleMinutes_50" 49 "IdleMinutes_49" 48 "IdleMinutes_48" 47 "IdleMinutes_47" 46 "IdleMinutes_46" 45 "IdleMinutes_45" 44 "IdleMinutes_44" 43 "IdleMinutes_43" 42 "IdleMinutes_42" 41 "IdleMinutes_41" 40 "IdleMinutes_40" 39 "IdleMinutes_39" 38 "IdleMinutes_38" 37 "IdleMinutes_37" 36 "IdleMinutes_36" 35 "IdleMinutes_35" 34 "IdleMinutes_34" 33 "IdleMinutes_33" 32 "IdleMinutes_32" 31 "IdleMinutes_31" 30 "IdleMinutes_30" 29 "IdleMinutes_29" 28 "IdleMinutes_28" 27 "IdleMinutes_27" 26 "IdleMinutes_26" 25 "IdleMinutes_25" 24 "IdleMinutes_24" 23 "IdleMinutes_23" 22 "IdleMinutes_22" 21 "IdleMinutes_21" 20 "IdleMinutes_20" 19 "IdleMinutes_19" 18 "IdleMinutes_18" 17 "IdleMinutes_17" 16 "IdleMinutes_16" 15 "IdleMinutes_15" 14 "IdleMinutes_14" 13 "IdleMinutes_13" 12 "IdleMinutes_12" 11 "IdleMinutes_11" 10 "IdleMinutes_10" 9 "IdleMinutes_9" 8 "IdleMinutes_8" 7 "IdleMinutes_7" 6 "IdleMinutes_6" 5 "IdleMinutes_5" 4 "IdleMinutes_4" 3 "IdleMinutes_3" 2 "IdleMinutes_2" 1 "IdleMinute_1" 0 "Null" ;
VAL_ 140 DcacPwResetBttn_D_Stat 3 "NotUsed" 2 "Stuck" 1 "Pressed" 0 "Not_Pressed" ;
VAL_ 739 BptDly_T_RqMnu 63 "Faulty" 62 "NoDataExists" ;
VAL_ 739 BptMnSoc_L_RqMnu 8191 "Faulty" 8190 "NoDataExists" ;
VAL_ 739 VehHornOccAlrt_D_Stat 3 "NotUsed" 2 "On" 1 "Off" 0 "Null" ;
VAL_ 739 SeatOccRear_D_Stat 3 "NotUsed" 2 "On" 1 "Off" 0 "Null" ;
VAL_ 739 BabySeatInUse_D_Stat 3 "NotUsed" 2 "InUse" 1 "NotInUse" 0 "Null" ;
VAL_ 739 SeatOccChime_B_RqCancl 1 "Cancel" 0 "Null" ;
VAL_ 739 EngExhMdeHrEnbl_D_Rq 3 "NotConfigured" 2 "Enabled" 1 "Disabled" 0 "Null" ;
VAL_ 739 EngExhMdeHrEnd_D_Rq 31 "NotUsed_7" 30 "NotUsed_6" 29 "NotUsed_5" 28 "NotUsed_4" 27 "NotUsed_3" 26 "NotUsed_2" 25 "NotUsed_1" 24 "Hour23_11pm" 23 "Hour22_10pm" 22 "Hour21_9pm" 21 "Hour20_8pm" 20 "Hour19_7pm" 19 "Hour18_6pm" 18 "Hour17_5pm" 17 "Hour16_4pm" 16 "Hour15_3pm" 15 "Hour14_2pm" 14 "Hour13_1pm" 13 "Hour12_12pm" 12 "Hour11_11am" 11 "Hour10_10am" 10 "Hour9_9am" 9 "Hour8_8am" 8 "Hour7_7am" 7 "Hour6_6am" 6 "Hour5_5am" 5 "Hour4_4am" 4 "Hour3_3am" 3 "Hour2_2am" 2 "Hour1_1am" 1 "Hour0_12am" 0 "Null" ;
VAL_ 739 EngExhMdeHrStrt_D_Rq 31 "NotUsed_7" 30 "NotUsed_6" 29 "NotUsed_5" 28 "NotUsed_4" 27 "NotUsed_3" 26 "NotUsed_2" 25 "NotUsed_1" 24 "Hour23_11pm" 23 "Hour22_10pm" 22 "Hour21_9pm" 21 "Hour20_8pm" 20 "Hour19_7pm" 19 "Hour18_6pm" 18 "Hour17_5pm" 17 "Hour16_4pm" 16 "Hour15_3pm" 15 "Hour14_2pm" 14 "Hour13_1pm" 13 "Hour12_12pm" 12 "Hour11_11am" 11 "Hour10_10am" 10 "Hour9_9am" 9 "Hour8_8am" 8 "Hour7_7am" 7 "Hour6_6am" 6 "Hour5_5am" 5 "Hour4_4am" 4 "Hour3_3am" 3 "Hour2_2am" 2 "Hour1_1am" 1 "Hour0_12am" 0 "Null" ;
VAL_ 739 Partial_Amp_Shutdown 1 "Active" 0 "Inactive" ;
VAL_ 739 BptStrtStop_D_RqMnu 3 "NotUsed_1" 2 "Start" 1 "Stop" 0 "NoRequest" ;
VAL_ 739 BptMde_D_RqMnu 7 "NotUsed_4" 6 "NotUsed_3" 5 "NotUsed_2" 4 "NotUsed_1" 3 "Automatic" 2 "Manual" 1 "Off" 0 "Null" ;
VAL_ 739 OnbTrgtSocOvrrd_D_Rq 3 "NotUsed" 2 "Enable" 1 "Disable" 0 "Null" ;
VAL_ 739 HMI_HMIMode_St 7 "NotUsed2" 6 "NotUsed1" 5 "Load_Shed_Active" 0 "Invalid" 1 "OffMode" 2 "On" 3 "Phone" 4 "Climate" ;
VAL_ 129 SelDrvMdeSwtch4_D_Stat4 3 "Faulty" 2 "Pressed" 1 "NotPressed" 0 "Null" ;
VAL_ 129 EngExhMdeQuiet_B_RqDrv2 1 "Pressed" 0 "Not_Pressed" ;
VAL_ 129 SelDrvMdeSwtch3_D_Stat4 3 "Faulty" 2 "Pressed" 1 "NotPressed" 0 "Null" ;
VAL_ 129 SelDrvMdeSwtch2_D_Stat4 3 "Faulty" 2 "Pressed" 1 "NotPressed" 0 "Null" ;
VAL_ 129 SelDrvMdeSwtch1_D_Stat4 3 "Faulty" 2 "Pressed" 1 "NotPressed" 0 "Null" ;
VAL_ 129 PoliceAux4Swtch_B_Stat 1 "Switch_Active" 0 "Switch_Not_Active" ;
VAL_ 129 PoliceAux3Swtch_B_Stat 1 "Switch_Active" 0 "Switch_Not_Active" ;
VAL_ 129 PoliceAux2Swtch_B_Stat 1 "Switch_Active" 0 "Switch_Not_Active" ;
VAL_ 129 PoliceAux1Swtch_B_Stat 1 "Switch_Active" 0 "Switch_Not_Active" ;
VAL_ 129 SteWhlSwtchView_B_Stat 1 "Pressed" 0 "Not_Pressed" ;
VAL_ 129 SteWhlSwtchSet_B_Stat 1 "Pressed" 0 "Not_Pressed" ;
VAL_ 129 SteWhlSwtchPhon_B_Stat 1 "Pressed" 0 "Not_Pressed" ;
VAL_ 129 SteWhlSwtchNav_B_Stat 1 "Pressed" 0 "Not_Pressed" ;
VAL_ 129 SteWhlSwtchMed_B_Stat 1 "Pressed" 0 "Not_Pressed" ;
VAL_ 129 SteWhlSwtchIod_B_Stat 1 "Pressed" 0 "Not_Pressed" ;
VAL_ 129 SteWhlSwtchHud_B_Stat 1 "Pressed" 0 "Not_Pressed" ;
VAL_ 129 SteWhlSwtchBack_B_Stat 1 "Pressed" 0 "Not_Pressed" ;
VAL_ 129 SteWhlSwtchMenu_B_Stat 1 "Pressed" 0 "Not_Pressed" ;
VAL_ 129 SteEffortInc_B_RqDrv 1 "Pressed" 0 "Not_Pressed" ;
VAL_ 129 SelDrvMdeInc_B_RqDrv 1 "Pressed" 0 "Not_Pressed" ;
VAL_ 129 SelDrvMdeDec_B_RqDrv 1 "Pressed" 0 "Not_Pressed" ;
VAL_ 129 SuspDampInc_B_RqDrv 1 "Pressed" 0 "Not_Pressed" ;
VAL_ 129 SteWhlSwtchUp_B_Stat 1 "Pressed" 0 "Not_Pressed" ;
VAL_ 129 SteWhlSwtchRght_B_Stat 1 "Pressed" 0 "Not_Pressed" ;
VAL_ 129 SteWhlSwtchOk_B_Stat 1 "Pressed" 0 "Not_Pressed" ;
VAL_ 129 SteWhlSwtchLeft_B_Stat 1 "Pressed" 0 "Not_Pressed" ;
VAL_ 129 SteWhlSwtchDown_B_Stat 1 "Pressed" 0 "Not_Pressed" ;
VAL_ 863 SteWhlHeat_D_Stat 15 "NotUsed6" 14 "NotUsed5" 13 "NotUsed4" 12 "NotUsed3" 11 "NotUsed2" 10 "NotUsed1" 9 "Reserved_3" 8 "Reserved_2" 7 "Reserved_1" 6 "Level_3_Heating" 5 "Level_3_Heating_LS" 4 "Level_2_Heating" 3 "Level_2_Heating_LS" 2 "Level_1_Heating" 1 "Level_1_Heating_LS" 0 "Off" ;
VAL_ 1116 TrlrAidSetup_D2_Rq 15 "NotUsed_9" 14 "NotUsed_8" 13 "NotUsed_7" 12 "NotUsed_6" 11 "NotUsed_5" 10 "NotUsed_4" 9 "NotUsed_3" 8 "NotUsed_2" 7 "NotUsed_1" 6 "CompleteSetup" 5 "ReturnToSetup" 4 "StickerNotCircled" 3 "ConfirmSetup" 2 "EndSetup" 1 "BeginSetup" 0 "Inactive" ;
VAL_ 1116 TrlrAidEnbl_D2_Rq 7 "NotUsed_4" 6 "NotUsed_3" 5 "NotUsed_2" 4 "NotUsed_1" 3 "Deactivate" 2 "ActivateTrg" 1 "ActivateTba" 0 "Inactive" ;
VAL_ 1116 TrlrRvrseCancl_B_Rq 1 "Cancel" 0 "Null" ;
VAL_ 1116 TrlrIdType_D_Stat 3 "Gooseneck" 2 "FifthWheel" 1 "Conventional" 0 "Null" ;
VAL_ 1116 TrlrAnOffstDir_D_Mem 3 "NotUSed" 2 "Right" 1 "Left_or_Center" 0 "Null" ;
VAL_ 1116 TlightTest_D_Mnu 3 "TestEndAcknowledge" 2 "StartTest" 1 "StopTest" 0 "Null" ;
VAL_ 1003 Pers4Key_D_Stat 3 "NotUsed_1" 2 "KeyUnAssociated" 1 "KeyAssociated" 0 "Null" ;
VAL_ 1003 EmPrflNo_D_Stat 7 "NotUsed_3" 6 "NotUsed_2" 5 "NotUsed_1" 4 "Pers4" 3 "Pers3" 2 "Pers2" 1 "Pers1" 0 "Null" ;
VAL_ 1003 EmPrflKeyAssoc_D_Stat 7 "WrongDevice" 6 "KeyAssociateFailed" 5 "KeyAssociateSuccess" 4 "KeyAlreadyInUse" 3 "KeyDisassociated" 2 "KeyAssociationExited" 1 "KeyAssociationEntered" 0 "Null" ;
VAL_ 1003 Pers3Key_D_Stat 3 "NotUsed_1" 2 "KeyUnAssociated" 1 "KeyAssociated" 0 "Null" ;
VAL_ 1003 Pers2Key_D_Stat 3 "NotUsed_1" 2 "KeyUnAssociated" 1 "KeyAssociated" 0 "Null" ;
VAL_ 1003 VehKeyActv_D_Stat 15 "NotUsed7" 14 "NotUsed6" 13 "NotUsed5" 12 "NotUsed4" 11 "NotUsed3" 10 "NotUsed2" 9 "NotUsed1" 8 "Key8Active" 7 "Key7Active" 6 "Key6Active" 5 "Key5Active" 4 "Key4Active" 3 "Key3Active" 2 "Key2Active" 1 "Key1Active" 0 "NoKeyActive" ;
VAL_ 1003 PersNoPos_D_Actl 7 "Unused_3" 6 "Unused_2" 5 "Unused_1" 4 "Vehicle" 3 "PERS_4" 2 "PERS_3" 1 "PERS_2" 0 "PERS_1" ;
VAL_ 1003 PersConflict_D_Actl 1 "Conflict" 0 "No_Conflict" ;
VAL_ 1003 Pers1Key_D_Stat 3 "NotUsed_1" 2 "KeyUnAssociated" 1 "KeyAssociated" 0 "Null" ;
VAL_ 1003 AssocConfirm_D_Actl 0 "None" 7 "Associate" 6 "Keycode_Rejected" 5 "Keycode_Accepted" 4 "In_Progress" 3 "Erase" 2 "Duplicate" 1 "Disassociate" ;
VAL_ 1003 TailLghtLoadMde_D_Stat 7 "Faulty" 6 "NotUsed_2" 5 "NotUsed_1" 4 "TailLightModeOverride" 3 "FalrModeActive" 2 "HitchLoadModeActive" 1 "PayloadModeActive" 0 "NoTailLightActive" ;
VAL_ 1003 PersRecallSrc_D_Actl 7 "NotUsed_3" 6 "NotUsed_2" 5 "NotUsed_1" 4 "MemorySwitch" 3 "RemoteStart" 2 "KeyFob" 1 "CenterStack" 0 "Null" ;
VAL_ 1003 PersSetupRestr_D_Actl 3 "Non_Moveable_Person" 2 "Moveable_Person" 1 "Vehicle" 0 "Factory" ;
VAL_ 1003 PersSetupAccessCtrl 1 "Limited" 0 "Full" ;
VAL_ 1003 PersNo_D_Actl 7 "Unused_3" 6 "Unused_2" 5 "NotDetermined" 4 "Vehicle" 3 "PERS_4" 2 "PERS_3" 1 "PERS_2" 0 "PERS_1" ;
VAL_ 1146 TrlrAidSwtch_D_RqDrv 3 "Faulty" 2 "NotUsed" 1 "Pressed" 0 "Not_Pressed" ;
VAL_ 1146 TrlrAidCtl_U_RqDrv 4095 "Faulty" 4094 "NoDataExists" ;
VAL_ 778 PrkAidAcsyRear_D_RqDrv 3 "NotUsed" 2 "On" 1 "Off" 0 "Null" ;
VAL_ 778 PrkAidAcsyFront_D_RqDrv 3 "NotUsed" 2 "On" 1 "Off" 0 "Null" ;
VAL_ 778 Cta_D_Rq 3 "Unused" 2 "NoDataExists" 1 "On" 0 "Off" ;
VAL_ 778 PrkAidRear_D_RqDrv 2 "Status" 3 "NotUsed" 1 "Enabled" 0 "Disabled" ;
VAL_ 778 PrkAidFront_D_RqDrv 2 "Status" 3 "NotUsed" 1 "Enabled" 0 "Disabled" ;
VAL_ 778 SteEffort_D_Rq 7 "NotUsed_3" 6 "NotUsed_2" 5 "NotUsed_1" 4 "SpecialMode_2" 3 "SpecialMode_1" 2 "Comfort" 1 "Sport" 0 "Normal" ;
VAL_ 778 Sod_D_Rq 3 "No_Selection_Made" 2 "BLIS_On_Second_Warning_ON" 1 "BLIS_On_Second_Warning_OFF" 0 "Off" ;
VAL_ 778 ClrExitAsstEnbl_D_RqDrv 3 "NotUsed" 0 "Inactive" 2 "Enable" 1 "Disable" ;
VAL_ 1255 BalrRight4Threat_D_Stat 1 "Yes" 0 "No" ;
VAL_ 1255 BalrRight4Fast_B_Stat 1 "Yes" 0 "No" ;
VAL_ 1255 BalrRight4Dsply_B_Stat 1 "Yes" 0 "No" ;
VAL_ 1254 BalrRight3Threat_D_Stat 1 "Yes" 0 "No" ;
VAL_ 1254 BalrRight3Fast_B_Stat 1 "Yes" 0 "No" ;
VAL_ 1254 BalrRight3Dsply_B_Stat 1 "Yes" 0 "No" ;
VAL_ 1253 BalrRight2Threat_D_Stat 1 "Yes" 0 "No" ;
VAL_ 1253 BalrRight2Fast_B_Stat 1 "Yes" 0 "No" ;
VAL_ 1253 BalrRight2Dsply_B_Stat 1 "Yes" 0 "No" ;
VAL_ 1252 BalrRight1Threat_D_Stat 1 "Yes" 0 "No" ;
VAL_ 1252 BalrRight1Fast_B_Stat 1 "Yes" 0 "No" ;
VAL_ 1252 BalrRight1Dsply_B_Stat 1 "Yes" 0 "No" ;
VAL_ 1251 BalrLeft4Threat_D_Stat 1 "Yes" 0 "No" ;
VAL_ 1251 BalrLeft4Fast_B_Stat 1 "Yes" 0 "No" ;
VAL_ 1251 BalrLeft4Dsply_B_Stat 1 "Yes" 0 "No" ;
VAL_ 1250 BalrLeft3Threat_D_Stat 1 "Yes" 0 "No" ;
VAL_ 1250 BalrLeft3Fast_B_Stat 1 "Yes" 0 "No" ;
VAL_ 1250 BalrLeft3Dsply_B_Stat 1 "Yes" 0 "No" ;
VAL_ 1249 BalrLeft2Threat_D_Stat 1 "Yes" 0 "No" ;
VAL_ 1249 BalrLeft2Fast_B_Stat 1 "Yes" 0 "No" ;
VAL_ 1249 BalrLeft2Dsply_B_Stat 1 "Yes" 0 "No" ;
VAL_ 1248 BalrLeft1Threat_D_Stat 1 "Yes" 0 "No" ;
VAL_ 1248 BalrLeft1Fast_B_Stat 1 "Yes" 0 "No" ;
VAL_ 1248 BalrLeft1Dsply_B_Stat 1 "Yes" 0 "No" ;
VAL_ 1105 ClrExitAsstMsgTxt2_D_Rq 15 "NotUsed_7" 14 "NotUsed_6" 13 "NotUsed_5" 12 "NotUsed_4" 11 "NotUsed_3" 10 "NotUsed_2" 9 "NotUsed_1" 8 "FrontLeftRearRight" 7 "RearLeftFrontRight" 6 "FrontLeftFrontRight" 5 "RearLeftRearRight" 4 "FrontRight" 3 "FrontLeft" 2 "RearRight" 1 "RearLeft" 0 "NoMessage" ;
VAL_ 1105 ClrExitAsstActv_B_Rq 1 "Active" 0 "Inactive" ;
VAL_ 1105 TrlrRvrseMsgTxt_D2_Rq 31 "Message31" 30 "Message30" 29 "Message29" 28 "Message28" 27 "Message27" 26 "Message26" 25 "Message25" 24 "Message24" 23 "Message23" 22 "Message22" 21 "Message21" 20 "Message20" 19 "Message19" 18 "Message18" 17 "Message17" 16 "Message16" 15 "Message15" 14 "Message14" 13 "Message13" 12 "Message12" 11 "Message11" 10 "Message10" 9 "Message9" 8 "Message8" 7 "Message7" 6 "Message6" 5 "Message5" 4 "Message4" 3 "Message3" 2 "Message2" 1 "Message1" 0 "NoMessage" 63 "Message63" 47 "Message47" ;
VAL_ 1105 TrlrRvrseEnbl_D2_Stat 7 "NotUsed" 6 "TbaActiveExpertActive" 5 "TbaActiveExpertAvail" 4 "TbaOffTrgActive" 3 "TbaOffTrgSetup" 2 "TbaSetup" 1 "TbaActive" 0 "Inactive" ;
VAL_ 1105 RbaMsg_D_Rq 3 "Faulty" 2 "Unavailable" 1 "Off" 0 "Null" ;
VAL_ 1105 BrkDecel_B_RqRba 1 "Enable" 0 "Disable" ;
VAL_ 1105 BrkEnbl_B_RqRba 1 "Enable" 0 "Disable" ;
VAL_ 1105 Rba_D_Stat 3 "NotUsed" 2 "Disabled" 1 "On" 0 "Off" ;
VAL_ 1105 RbaAlrt_D_Dsply 3 "Both" 2 "Text" 1 "Graphic" 0 "Off" ;
VAL_ 1105 RbaMnu_D_Rq 3 "NotUsed" 2 "Active" 1 "Inactive" 0 "None" ;
VAL_ 1105 CamraFrntStat_D_Stat 3 "No_Data_Present" 2 "NotUsed" 1 "On" 0 "Off" ;
VAL_ 1105 TrlrHitchLamp_D_Rq2 1 "On" 0 "Off" ;
VAL_ 1105 TrlrAidSwtchLamp_B_Rq 1 "On" 0 "Off" ;
VAL_ 1105 TrlrAidEnbl_D_RqAdas 7 "NotUsed_4" 6 "NotUsed_3" 5 "NotUsed_2" 4 "NotUsed_1" 3 "Deactivate" 2 "NotAvailable" 1 "ActiveTba" 0 "Inactive" ;
VAL_ 1105 TrlrHitchMsgTxt_D_Rq 31 "Message31" 30 "Message30" 29 "Message29" 28 "Message28" 27 "Message27" 26 "Message26" 25 "Message25" 24 "Message24" 23 "Message23" 22 "Message22" 21 "Message21" 20 "Message20" 19 "Message19" 18 "Message18" 17 "Message17" 16 "Message16" 15 "Message15" 14 "Message14" 13 "Message13" 12 "Message12" 11 "Message11" 10 "Message10" 9 "Message9" 8 "Message8" 7 "Message7" 6 "Message6" 5 "Message5" 4 "Message4" 3 "Message3" 2 "Message2" 1 "Message1" 0 "NoMessage" 63 "Message63" 47 "Message47" ;
VAL_ 1105 TrlrHitchIcon_D_Rq 15 "Icon15" 14 "Icon14" 13 "Icon13" 12 "Icon12" 11 "Icon11" 10 "Icon10" 9 "Icon9" 8 "Icon8" 7 "Icon7" 6 "Icon6" 5 "Icon5" 4 "Icon4" 3 "Icon3" 2 "Icon2" 1 "Icon1" 0 "NoIcon" ;
VAL_ 1105 TrlrHitchChime_D_Rq 7 "NotUsed_1" 6 "NotUsed_1" 5 "WarningChime" 4 "NonCriticalAlertChime" 3 "StopNowChime" 2 "ManeuveringReadyChime" 1 "TrailerFoundChime" 0 "NoChime" ;
VAL_ 1105 CamraFrntOffRd_B_Stat 1 "Active" 0 "Inactive" ;
VAL_ 1111 TrlrYawWActl_D_Qf 3 "OK" 2 "Not_Within_Specifications" 1 "No_Data_Exists" 0 "Faulty" ;
VAL_ 1111 TrlrYaw_W_Actl 65535 "Faulty" 65534 "NoDataExists" ;
VAL_ 1111 TrlrHitYaw_AnRate_Actl 4095 "Fault" 4094 "NoDataExists" ;
VAL_ 1111 TrlrHitchYaw_D_Stat 15 "Faulty" 14 "NotUsed_4" 13 "NotUsed_3" 12 "NotUsed_2" 11 "NotUsed_1" 10 "FaultyYrsuConnection" 9 "FaultyYrsu" 8 "HiConfdLrndAngle" 7 "LowConfdLrndAngle" 6 "HiConfdAngleMem" 5 "LowConfdAngleMem" 4 "InitNoTadAngle" 3 "InitInputs" 2 "TadTrlrDataOutOfRange" 1 "TadNotWithinSpecification" 0 "NoConnectionWithYrsu" ;
VAL_ 1111 TrlrHitchYaw_An_Actl 4095 "Faulty" 4094 "NoDataExists" ;
VAL_ 1106 TrlrSnsId_No_Actl -1 "Faulty_FFFFFFFFFFFF" -2 "NoDataExists_FFFFFFFFFFFE" ;
VAL_ 909 HazrdLght_B_Stat 1 "On" 0 "Off" ;
VAL_ 909 IgnPsswrdDsply_B_Rq 1 "Active" 0 "Inactive" ;
VAL_ 909 ElPwPoint_D_Rq 3 "On" 2 "Off2" 1 "Off1" 0 "Null" ;
VAL_ 909 TurnLghtSwtch_D_Stat2 3 "NotUsed" 2 "Right" 1 "Left" 0 "Off" ;
VAL_ 909 PoliceIdlMde_D_Stat 15 "NotUsed_7" 14 "NotUsed_6" 13 "NotUsed_5" 12 "NotUsed_4" 11 "NotUsed_3" 10 "UtilityIdleActive" 9 "PepsActive" 8 "Decommissioned" 7 "ActiveFault" 6 "ArmFault" 5 "PrearmedFault" 4 "OffFault" 3 "Active" 2 "Arm" 1 "Prearmed" 0 "Off" ;
VAL_ 909 PrsnlDevcChrgEnbl_B_Rq 1 "Active" 0 "Inactive" ;
VAL_ 909 DrLatchMsgTxt_D_Rq 7 "Message7" 6 "Message6" 5 "Message5" 4 "Message4" 3 "Message3" 2 "Message2" 1 "Message1" 0 "NoMessage" ;
VAL_ 909 TracKeyMde_D_Stat 3 "NotUsed" 2 "NotActive" 1 "Active" 0 "ModeNotDetermined" ;
VAL_ 909 SecurityMsgTxt_D_Rq 3 "Message3" 2 "Message2" 1 "Message1" 0 "NoMessage" ;
VAL_ 909 PrmtrAlrmEvnt_D_Stat 15 "Diag_Tamper" 14 "Trailer" 13 "Shock_Sensor" 12 "Post_Crash" 11 "Panic" 10 "Intrusion" 9 "Inclination" 8 "Ign_Tamper" 7 "LG_Door" 6 "Decklid" 5 "Hood" 4 "PR_Door" 3 "PF_Door" 2 "DR_Door" 1 "DF_Door" 0 "Null" ;
VAL_ 909 immoMsgTxt_D_Rq 15 "Immo_Msg_15" 14 "Immo_Msg_14" 13 "Immo_Msg_13" 12 "Immo_Msg_12" 11 "Immo_Msg_11" 10 "Immo_Msg_10" 9 "Immo_Msg_9" 8 "Immo_Msg_8" 7 "Immo_Msg_7" 6 "Immo_Msg_6" 5 "Immo_Msg_5" 4 "Immo_Msg_4" 3 "Immo_Msg_3" 2 "Immo_Msg_2" 1 "Immo_Msg_1" 0 "Immo_Msg_0_Null" ;
VAL_ 909 SteWhlLckMsgTxt_D_Rq 3 "Message_3" 2 "Message_2" 1 "Message_1" 0 "No_Message" ;
VAL_ 909 PEBackupSlot_Stats 3 "No_Valid_FOB_In_Slot" 2 "MyKey_FOB_In_Slot" 1 "Standard_FOB_In_Slot" 0 "Null" ;
VAL_ 909 KeyMykeyTot_No_Cnt 13 "Thirteen" 12 "Twelve" 11 "Eleven" 10 "Ten" 9 "Nine" 8 "Eight" 7 "Seven" 6 "Six" 5 "Five" 4 "Four" 3 "Three" 2 "Two" 1 "One" 0 "Zero" 15 "Invalid" 14 "Unlimited" ;
VAL_ 909 KeyAdmnTot_No_Cnt 13 "Thirteen" 12 "Twelve" 11 "Eleven" 10 "Ten" 9 "Nine" 8 "Eight" 7 "Seven" 6 "Six" 5 "Five" 4 "Four" 3 "Three" 2 "Two" 1 "One" 0 "Zero" 15 "Invalid" 14 "Unlimited" ;
VAL_ 909 WiprFront_D_Stat2 15 "NO_DATA_EXISTS" 14 "STALLED" 13 "NotUsed" 12 "AUTO_ADJUST" 11 "COURTESYWIPE" 10 "AUTO_HIGH" 9 "AUTO_LOW" 8 "WASH" 7 "MIST_FLICK" 6 "MAN_HIGH" 5 "MAN_LOW" 4 "MAN_INT_ON" 3 "MAN_INT_OFF" 2 "OFF_MOVING" 1 "AUTO_OFF" 0 "OFF" ;
VAL_ 909 HeadLghtHiPrmsn_D_Stat 3 "CancelAndSuppress" 2 "Cancel" 1 "Hold" 0 "AllowChange" ;
VAL_ 963 PudLampPsngr_D_Rq 3 "Ramp_Down" 2 "Ramp_Up" 1 "On" 0 "Off" ;
VAL_ 963 DrTgateLck_D_Stat 3 "NotUsed" 2 "Unlock" 1 "Lock" 0 "Null" ;
VAL_ 963 Illuminated_Entry_Stat 3 "Invalid" 2 "Unknown" 1 "On" 0 "Off" ;
VAL_ 963 Dr_Courtesy_Light_Stat 3 "Invalid" 2 "Unknown" 1 "On" 0 "Off" ;
VAL_ 963 Courtesy_Delay_Status 3 "Invalid" 2 "Unknown" 1 "On" 0 "Off" ;
VAL_ 963 ImpactEvntFdbck_D_Stat 3 "NotUsed" 2 "EventComplete" 1 "EventInProgress" 0 "Normal" ;
VAL_ 963 WrlssAcsyChrgInhbt_B_Rq 1 "Yes" 0 "No" ;
VAL_ 963 HeadLampLoOut_B_Stat 1 "Out" 0 "Null" ;
VAL_ 963 TrnNotInPrkChime_B_Rq 1 "On" 0 "Off" ;
VAL_ 963 PrkLightChime_B_Rq 1 "On" 0 "Off" ;
VAL_ 963 Park_Brake_Chime_Rqst 1 "On" 0 "Off" ;
VAL_ 963 KeyInIgnWarn_B_Cmd 1 "On" 0 "Off" ;
VAL_ 963 HomeSafeLtChime_B_Rq 1 "On" 0 "Off" ;
VAL_ 963 Headlamp_On_Wrning_Cmd 1 "On" 0 "Off" ;
VAL_ 963 Brk_Fluid_Lvl_Low 3 "Invalid" 2 "Unknown" 1 "Low" 0 "OK" ;
VAL_ 963 ReducedGuard_D_Stat 3 "NotUsed" 2 "Alarm_On" 1 "Alarm_Off_Previously_On" 0 "Alarm_Off" ;
VAL_ 963 BrkWarnInd_B_Rq 1 "On" 0 "Off" ;
VAL_ 963 RvrseLghtOn_B_Stat 1 "On" 0 "Off" ;
VAL_ 963 PrkLght_D_Stat 3 "Park_Both" 2 "Park_Right" 1 "Park_Left" 0 "Off" ;
VAL_ 963 PerimeterAlarmChimeRq 1 "On" 0 "Off" ;
VAL_ 963 HeadLghtHiFdbck_D_Stat 3 "NotUsed" 2 "Cancel" 1 "Hold" 0 "Allow_Change" ;
VAL_ 963 PudLampDrv_D_Rq 3 "Ramp_Down" 2 "Ramp_Up" 1 "On" 0 "Off" ;
VAL_ 963 StopLghtOn_B_Stat 1 "On" 0 "Off" ;
VAL_ 963 HeadLghtSwtch_D_Stat 3 "Autolamp" 2 "Headlamp" 1 "Parklamp" 0 "Off" ;
VAL_ 963 HeadLampLoFrOn_B_Stat 1 "Low" 0 "Not_Low" ;
VAL_ 963 HeadLampLoFlOn_B_Stat 1 "Low" 0 "Not_Low" ;
VAL_ 963 HeadLampLoActv_B_Stat 1 "On" 0 "Off" ;
VAL_ 963 HeadLghtHiOn_B_Stat 1 "On" 0 "Off" ;
VAL_ 963 Perimeter_Alarm_Status 3 "Activated" 2 "Armed" 1 "Prearmed" 0 "Disarmed" ;
VAL_ 963 Courtesy_BSave_Stat 3 "Invalid" 2 "Unknown" 1 "No_Effect" 0 "Off" ;
VAL_ 963 WndwGlbl_D_Cmd 7 "NotUsed3" 6 "NotUsed2" 5 "NotUsed1" 4 "GLEARN" 3 "GCLOSE" 2 "GOPEN" 1 "GSTOP" 0 "Null" ;
VAL_ 963 PudLamp_D_Rq 3 "RAMP_DOWN" 2 "RAMP_UP" 1 "ON" 0 "OFF" ;
VAL_ 963 DayRnngLampOn_B_Stat 1 "On" 0 "Off" ;
VAL_ 578 PtLatchActv_B_RqBcm 1 "On" 0 "Off" ;
VAL_ 578 immoSecureIdleMode 3 "NotUsed2" 2 "NotUsed1" 1 "Active" 0 "Inactive" ;
VAL_ 578 ReFuelSwtchStat_D_Actl 3 "NotUsed2" 2 "NotUsed1" 1 "On" 0 "Off" ;
VAL_ 578 FuelPumpPwr_D_Stat 7 "NotUsed3" 6 "NotUsed2" 5 "NotUsed1" 4 "Power_Off_Default" 3 "Power_Off_Command" 2 "Power_Off_Service" 1 "Power_Off_Impact" 0 "Power_On" ;
VAL_ 578 BattULo_U_Actl 255 "Fault" ;
VAL_ 578 PrkLckCtl_B_Enbl 1 "Enable" 0 "Disable" ;
VAL_ 578 PrkLckCtlMsgTxt_D_Rq 3 "BTSI_DI_3" 2 "BTSI_DI_2" 1 "BTSI_DI_1" 0 "Null_BTSI_DI" ;
VAL_ 578 BrkTrnShifLck_B_Stat 1 "Shift" 0 "NoShift" ;
VAL_ 578 PrkLckCtlUnlck_D_Stat 3 "Trans_And_Steer_Unlckd" 2 "Steering_Unlckd" 1 "Transmission_Unlckd" 0 "Null" ;
VAL_ 578 PrkLckCtlTow_B_Enbl 1 "Enable" 0 "Disable" ;
VAL_ 578 DriverCrankingReq 1 "Crank_Request" 0 "No_Crank_Request" ;
VAL_ 578 EngOff_T_Actl 65535 "Invalid" ;
VAL_ 578 DcacElPw_D_Rq 3 "NotUsed" 2 "AC_HighPower_Requested" 1 "AC_LowPower_Requested" 0 "AC_Power_NotRequested" ;
VAL_ 578 BattULo_I_Actl 16383 "Fault" ;
VAL_ 1010 MbdblActv_B_RqAdas 1 "Yes" 0 "No" ;
VAL_ 1010 CbdblActv_B_RqAdas 1 "Yes" 0 "No" ;
VAL_ 1010 AdbUrbanArea_B_Stat 1 "Yes" 0 "No" ;
VAL_ 985 ClrExitAsst_D_Stat 3 "NotUsed" 2 "Enabled" 1 "Disabled" 0 "Null" ;
VAL_ 985 ClrExitAsstMsgTxt_D_Rq 15 "NotUsed_8" 14 "NotUsed_7" 13 "NotUsed_6" 12 "NotUsed_5" 11 "NotUsed_4" 10 "NotUsed_3" 9 "NotUsed_2" 8 "NotUsed_1" 7 "SystemFault" 6 "ChildLockMaintained" 5 "WarningRight" 4 "WarningLeft" 3 "InformationRight" 2 "InformationLeft" 1 "Shutdown" 0 "NoMessage" ;
VAL_ 985 ClrExitAsstChime_D_Rq 7 "NotUsed_4" 6 "NotUsed_3" 5 "NotUsed_2" 4 "NotUsed_1" 3 "WarningChimeFront" 2 "WarningChimeRear" 1 "InformationChime" 0 "Off" ;
VAL_ 985 PwSustnAdas_B_Rq 1 "Active" 0 "Inactive" ;
VAL_ 985 AdbDrvSide_B_Stat 1 "Left_Hand_Traffic" 0 "Right_Hand_Traffic" ;
VAL_ 985 LcwaMsgTxt_D_Stat 3 "SodXFaulty" 2 "SodXBlocked" 1 "TrailerConnected" 0 "NoMessage" ;
VAL_ 985 AdbDividedRoad_B_Stat 1 "Yes" 0 "No" ;
VAL_ 985 IsaVLimUnit_D_Rq 3 "NoDataExists" 2 "Mph" 1 "Kph" 0 "Null" ;
VAL_ 985 SblmYieldScnr_B_Stat 1 "Yes" 0 "No" ;
VAL_ 985 SblmStopScnr_B_Stat 1 "Yes" 0 "No" ;
VAL_ 985 IsaVLim_D_Rq 252 "NotUsed_2" 250 "LimitSpeed_250" 240 "LimitSpeed_240" 230 "LimitSpeed_230" 220 "LimitSpeed_220" 210 "LimitSpeed_210" 200 "LimitSpeed_200" 190 "LimitSpeed_190" 150 "LimitSpeed_150" 140 "LimitSpeed_140" 130 "LimitSpeed_130" 120 "LimitSpeed_120" 110 "LimitSpeed_110" 100 "LimitSpeed_100" 90 "LimitSpeed_90" 80 "LimitSpeed_80" 70 "LimitSpeed_70" 60 "LimitSpeed_60" 50 "LimitSpeed_50" 40 "LimitSpeed_40" 30 "LimitSpeed_30" 20 "LimtSpeed_20" 251 "NotUsed_1" 255 "Faulty" 254 "NoDataExists" 253 "NotUsed_3" 180 "LimitSpeed_180" 179 "LimitSpeed_179" 178 "LimitSpeed_178" 177 "LimitSpeed_177" 176 "LimitSpeed_176" 175 "LimitSpeed_175" 174 "LimitSpeed_174" 173 "LimitSpeed_173" 172 "LimitSpeed_172" 171 "LimitSpeed_171" 170 "LimitSpeed_170" 169 "LimitSpeed_169" 168 "LimitSpeed_168" 167 "LimitSpeed_167" 166 "LimitSpeed_166" 165 "LimitSpeed_165" 164 "LimitSpeed_164" 163 "LimitSpeed_163" 162 "LimitSpeed_162" 161 "LimitSpeed_161" 160 "LimitSpeed_160" 15 "LimitSpeed_15" 14 "LimitSpeed_14" 13 "LimitSpeed_13" 12 "LimitSpeed_12" 11 "LimitSpeed_11" 10 "LimitSpeed_10" 9 "LimitSpeed_9" 8 "LimitSpeed_8" 7 "LimitSpeed_7" 6 "LimitSpeed_6" 5 "LimitSpeed_5" 4 "LimitSpeed_4" 3 "LimitSpeed_3" 2 "LimitSpeed_2" 1 "LimitSpeed_1" 0 "LimitSpeed_0" ;
VAL_ 985 IaccVLimUnit_D_Rq 3 "NoDataExists" 2 "Mph" 1 "Kph" 0 "Null" ;
VAL_ 985 IaccVLim_D_Rq 252 "NotUsed_2" 250 "LimitSpeed_250" 240 "LimitSpeed_240" 230 "LimitSpeed_230" 220 "LimitSpeed_220" 210 "LimitSpeed_210" 200 "LimitSpeed_200" 190 "LimitSpeed_190" 150 "LimitSpeed_150" 140 "LimitSpeed_140" 130 "LimitSpeed_130" 120 "LimitSpeed_120" 110 "LimitSpeed_110" 100 "LimitSpeed_100" 90 "LimitSpeed_90" 80 "LimitSpeed_80" 70 "LimitSpeed_70" 60 "LimitSpeed_60" 50 "LimitSpeed_50" 40 "LimitSpeed_40" 30 "LimitSpeed_30" 20 "LimtSpeed_20" 251 "NotUsed_1" 255 "Faulty" 254 "NoDataExists" 253 "NotUsed_3" 180 "LimitSpeed_180" 179 "LimitSpeed_179" 178 "LimitSpeed_178" 177 "LimitSpeed_177" 176 "LimitSpeed_176" 175 "LimitSpeed_175" 174 "LimitSpeed_174" 173 "LimitSpeed_173" 172 "LimitSpeed_172" 171 "LimitSpeed_171" 170 "LimitSpeed_170" 169 "LimitSpeed_169" 168 "LimitSpeed_168" 167 "LimitSpeed_167" 166 "LimitSpeed_166" 165 "LimitSpeed_165" 164 "LimitSpeed_164" 163 "LimitSpeed_163" 162 "LimitSpeed_162" 161 "LimitSpeed_161" 160 "LimitSpeed_160" 15 "LimitSpeed_15" 14 "LimitSpeed_14" 13 "LimitSpeed_13" 12 "LimitSpeed_12" 11 "LimitSpeed_11" 10 "LimitSpeed_10" 9 "LimitSpeed_9" 8 "LimitSpeed_8" 7 "LimitSpeed_7" 6 "LimitSpeed_6" 5 "LimitSpeed_5" 4 "LimitSpeed_4" 3 "LimitSpeed_3" 2 "LimitSpeed_2" 1 "LimitSpeed_1" 0 "LimitSpeed_0" ;
VAL_ 985 DasAlrtInfo_D_Dsply 3 "NotUsed" 2 "On" 1 "Off" 0 "Null" ;
VAL_ 985 SblmRndAbtScnr_B_Stat 1 "Yes" 0 "No" ;
VAL_ 985 LongCtrlEnbl_D_Rq 7 "Faulty" 6 "NotUsed_3" 5 "NotUsed_2" 4 "NotUsed_1" 3 "RemoteParking" 2 "Autohitch" 1 "AutomaticParking" 0 "None" ;
VAL_ 985 SblmPedCrossScnr_B_Stat 1 "Yes" 0 "No" ;
VAL_ 985 TsrRegionTxt_D_Stat 31 "Faulty" 30 "NotUsed_8" 29 "NotUsed_7" 28 "NotUsed_6" 27 "NotUsed_5" 26 "NotUsed_4" 25 "NotUsed_3" 24 "NotUsed_2" 23 "NotUsed_1" 22 "Region_22" 21 "Region_21" 20 "Region_20" 19 "Region_19" 18 "Region_18" 17 "Region_17" 16 "Region_16" 15 "Region_15" 14 "Region_14" 13 "Region_13" 12 "Region_12" 11 "Region_11" 10 "Region_10" 9 "Region_09" 8 "Region_08" 7 "Region_07" 6 "Region_06" 5 "Region_05" 4 "Region_04" 3 "Region_03" 2 "Region_02" 1 "Region_01" 0 "NotDetermined" ;
VAL_ 985 LongCtrlBrk_D_Rq 3 "NotUsed" 2 "LowDecel" 1 "HighDecel" 0 "NoRequest" ;
VAL_ 985 LdwChime_B_Rq 1 "On" 0 "Off" ;
VAL_ 984 AhbFeat_D_Stat 3 "ADB" 2 "GFHB" 1 "AHBC" 0 "None" ;
VAL_ 984 LaActvStats_D2_Dsply 31 "Unused7" 30 "LA_Off" 29 "ECE_OFF_RTT" 28 "Unused4" 27 "Unused3" 26 "Unused2" 25 "Unused1" 24 "InerveneLeft_InterveneRght" 23 "WarnLeft_InterveneRight" 22 "SuppressLeft_InterveneRght" 21 "AvailLeft_InterveneRhtt" 20 "NoLeft_InterveneRight" 19 "InterveneLeft_WarnRight" 18 "WarnLeft_WarnRight" 17 "SuppressLeft_WarnRight" 16 "AvailableLeft_WarnRight" 15 "NoLeft_WarnRight" 14 "InterveneLeft_SuppressRght" 13 "WarnLeft_SuppressRight" 12 "SuppressLeft_SuppressRight" 11 "AvailLeft_SuppressRight" 10 "NoLeft_SuppressRight" 9 "InterveneLeft_AvailRight" 8 "WarnLeft_AvailRight" 7 "SuppressLeft_AvailRight" 6 "AvailableLeft_AvailRight" 5 "NoLeft_AvailableRight" 4 "InterveneLeft_NoRight" 3 "WarnLeft_NoRight" 2 "SuppressLeft_NoRight" 1 "AvailableLeft_NoRight" 0 "NoLeft_NoRight" ;
VAL_ 984 DasWarn_D_Dsply 3 "Undefined" 2 "Warning_Level_2" 1 "Warning_Level_1" 0 "No_Warning" ;
VAL_ 984 DasStats_D_Dsply 3 "Available" 2 "Unavailable_Other" 1 "Feedback_due_to_Speed" 0 "Off" ;
VAL_ 984 DasAlrtLvl_D_Dsply 5 "Alertness_Level_5" 4 "Alertness_Level_4" 3 "Alertness_Level_3" 2 "Alertness_Level_2" 1 "Alertness_Level_1" 0 "Undefined" ;
VAL_ 984 CamraStats_D_Dsply 3 "FrtCam_TempUnavailOther" 2 "FrtCam_TempUnavailVisibile" 1 "Front_Camera_Service_Reqd" 0 "Front_Camera_OK" ;
VAL_ 984 CamraDefog_B_Req 1 "On" 0 "Off" ;
VAL_ 984 LaHandsOff_D_Dsply 3 "Suppressed" 2 "Level2" 1 "Level1" 0 "HandsOn" ;
VAL_ 984 LaDenyStats_B_Dsply 1 "Unavailable" 0 "Available" ;
VAL_ 984 AhbcRampingV_D_Rq 3 "Slow" 2 "Medium" 1 "Fast" 0 "Immediately" ;
VAL_ 984 PersIndexIpma_D_Actl 7 "Unused_3" 6 "Unused_2" 5 "Unused_1" 4 "Vehicle" 3 "PERS_4" 2 "PERS_3" 1 "PERS_2" 0 "PERS_1" ;
VAL_ 984 AhbHiBeam_D_Rq 3 "NotUsed" 2 "HighBeamRecommended" 1 "LowBeamRecommended" 0 "DeactivatedUnavailable" ;
VAL_ 984 DsmcMsgTxt_D_Dsply 3 "Blockage" 2 "DriverNotSeen" 1 "Fault" 0 "NoMessage" ;
VAL_ 983 CmbbObjRelLong_V_Actl 1023 "Faulty" 1022 "NoDataExists" ;
VAL_ 983 CmbbObjRelLat_V_Actl 511 "Faulty" 510 "NoDataExists" ;
VAL_ 983 CmbbObjDistLong_L_Actl 1023 "Faulty" 1022 "NoDataExists" ;
VAL_ 983 CmbbObjDistLat_L_Actl 511 "Faulty" 510 "NoDataExists" ;
VAL_ 983 CmbbObjConfdnc_D_Stat 3 "High" 2 "Medium" 1 "Low" 0 "NotDetermined" ;
VAL_ 983 CmbbObjColl_T_Actl 127 "Faulty" 126 "NoDataExists" ;
VAL_ 983 CmbbObjClass_D_Stat 15 "NotUsed_9" 14 "NotUsed_8" 13 "NotUsed_7" 12 "NotUsed_6" 11 "NotUsed_5" 10 "NotUsed_4" 9 "NotUsed_3" 8 "NotUsed_2" 7 "NotUsed_1" 6 "Unclassified_Vehicle" 5 "Bicycle" 4 "Pedestrian" 3 "Truck" 2 "Motorcycle" 1 "Vehicle" 0 "Undetermined" ;
VAL_ 983 EsaEnbl_D2_Rq 3 "NotConfigured" 2 "Enabled" 1 "Pending" 0 "Disabled" ;
VAL_ 970 LkaDrvOvrrd_D_Rq 3 "Level_3" 2 "Level_2" 1 "Level_1" 0 "Level_0" ;
VAL_ 970 LkaActvStats_D2_Req 7 "NotUsed" 6 "LkaIncrIntervRight" 5 "LkaSupprRight" 4 "LkaStandIntervRight" 3 "LkaSupprLeft" 2 "LkaStandIntervLeft" 1 "LkaIncrIntervLeft" 0 "LkaNoInterv" ;
VAL_ 970 LaRefAng_No_Req 4095 "Fault" ;
VAL_ 970 LaRampType_B_Req 1 "Quick" 0 "Smooth" ;
VAL_ 970 LaCurvature_No_Calc 4095 "Fault" ;
VAL_ 970 LdwActvStats_D_Req 7 "LDW_Suppress_Right_Left" 6 "Not_Used2" 5 "LDW_Suppress_Right" 4 "LDW_Warning_Right" 3 "LDW_Suppress_Left" 2 "LDW_Warning_Left" 1 "LDW_DemoVibration" 0 "LDW_Idle" ;
VAL_ 970 LdwActvIntns_D_Req 3 "High" 2 "Medium" 1 "Low" 0 "None" ;
